AUTOSAR XML (schema 4-0-3)
package /AUTOSAR/Services/Dcm
  swc implementation IMPL_Dcm: programming-language=C, sw-version=6.14.0, swc-bsw-mapping=Dcm_SwcBswMapping, vendor-id=41, behavior=IB_Dcm
    code-descriptors:
      code CODE_Dcm: artifact-descriptors=autosar-engineering-object={short-label=Dcm, category=SWSRC}
    resource consumption RC_Dcm
  unit UnitNone
  178 x client server interface, all with is-service=true:
    DTRServices
      operation GetDTRValue: possible-error=DTRServices/E_NOT_OK
        5 x arg:
          OpStatus: type=Dcm_OpStatusType, direction=IN
          Testval: type=uint16, direction=OUT
          Minlimit: type=uint16, direction=OUT
          Maxlimit: type=uint16, direction=OUT
          Status: type=Dcm_DTRStatusType, direction=OUT
      error E_NOT_OK: error-code=1
    CallbackDCMRequestServices
      operation StartProtocol: possible-error=[CallbackDCMRequestServices/E_NOT_OK, E_PROTOCOL_NOT_ALLOWED, CallbackDCMRequestServices/E_UNCONNECTED]
        arg ProtocolID: type=Dcm_ProtocolType, direction=IN
      operation StopProtocol: possible-error=CallbackDCMRequestServices/E_NOT_OK
        arg ProtocolID: type=Dcm_ProtocolType, direction=IN
      error E_NOT_OK: error-code=1
      error E_PROTOCOL_NOT_ALLOWED: error-code=5
      error E_UNCONNECTED: error-code=134
    ServiceRequestNotification
      operation Indication: possible-error=[ServiceRequestNotification/E_NOT_OK, E_REQUEST_NOT_ACCEPTED, ServiceRequestNotification/E_UNCONNECTED]
        6 x arg:
          SID: type=uint8, direction=IN
          RequestData: type=Dcm_DataBuffer1024FixedType, direction=INOUT
          DataSize: type=uint16, direction=IN
          ReqType: type=uint8, direction=IN
          SourceAddress: type=uint16, direction=IN
          ErrorCode: type=Dcm_NegativeResponseCodeType, direction=OUT
      operation Confirmation: possible-error=ServiceRequestNotification/E_NOT_OK
        4 x arg, all with direction=IN:
          SID: type=uint8
          ReqType: type=uint8
          SourceAddress: type=uint16
          ConfirmationStatus: type=Dcm_ConfirmationStatusType
      error E_NOT_OK: error-code=1
      error E_REQUEST_NOT_ACCEPTED: error-code=8
      error E_UNCONNECTED: error-code=134
    ResetService
      operation EcuReset: possible-error=[ResetService/E_NOT_OK, ResetService/E_PENDING]
        arg resetType: type=uint8, direction=IN
        arg ErrorCode: type=Dcm_NegativeResponseCodeType, direction=OUT
      error E_NOT_OK: error-code=1
      error E_PENDING: error-code=10
    DCMServices
      4 x operation, all with possible-error=DCMServices/E_NOT_OK:
        GetActiveProtocol
          arg ActiveProtocol: type=Dcm_ProtocolType, direction=OUT
        GetSesCtrlType
          arg ActiveSession: type=Dcm_SesCtrlType, direction=OUT
        GetSecurityLevel
          arg SecLevel: type=Dcm_SecLevelType, direction=OUT
        ResetToDefaultSession
      error E_NOT_OK: error-code=1
    DCM_Roe
      operation TriggerOnEvent: possible-error=DCM_Roe/E_NOT_OK
        arg RoeEventId: type=uint8, direction=IN
      error E_NOT_OK: error-code=1
    ROEServices
      operation ActivateEvent: possible-error=ROEServices/E_NOT_OK
        arg RoeEventId: type=uint8, direction=IN
        arg RoeState: type=Dcm_RoeStateType, direction=IN
      error E_NOT_OK: error-code=1
    SecurityAccess_SecurityLevel1
      operation GetSeed: possible-error=[SecurityAccess_SecurityLevel1/E_NOT_OK, SecurityAccess_SecurityLevel1/E_PENDING]
        arg OpStatus: type=Dcm_OpStatusType, direction=IN
        arg Seed: type=Dcm_DataBuffer4FixedType, direction=OUT
        arg ErrorCode: type=Dcm_NegativeResponseCodeType, direction=OUT
      operation CompareKey: possible-error=[SecurityAccess_SecurityLevel1/E_NOT_OK, SecurityAccess_SecurityLevel1/E_PENDING, E_COMPARE_KEY_FAILED]
        arg Key: type=Dcm_DataBuffer4FixedType, direction=INOUT
        arg OpStatus: type=Dcm_OpStatusType, direction=IN
      error E_NOT_OK: error-code=1
      error E_PENDING: error-code=10
      error E_COMPARE_KEY_FAILED: error-code=11
    RoutineServices_RidAE10_MainRelayCtrl
      operation Start: possible-error=[RoutineServices_RidAE10_MainRelayCtrl/E_NOT_OK, RoutineServices_RidAE10_MainRelayCtrl/E_PENDING, RoutineServices_RidAE10_MainRelayCtrl/E_FORCE_RCRRP]
        arg OpStatus: type=Dcm_OpStatusType, direction=IN
        arg ErrorCode: type=Dcm_NegativeResponseCodeType, direction=OUT
      operation Stop: possible-error=[RoutineServices_RidAE10_MainRelayCtrl/E_NOT_OK, RoutineServices_RidAE10_MainRelayCtrl/E_PENDING, RoutineServices_RidAE10_MainRelayCtrl/E_FORCE_RCRRP]
        arg OpStatus: type=Dcm_OpStatusType, direction=IN
        arg ErrorCode: type=Dcm_NegativeResponseCodeType, direction=OUT
      operation RequestResults: possible-error=[RoutineServices_RidAE10_MainRelayCtrl/E_NOT_OK, RoutineServices_RidAE10_MainRelayCtrl/E_PENDING, RoutineServices_RidAE10_MainRelayCtrl/E_FORCE_RCRRP]
        arg OpStatus: type=Dcm_OpStatusType, direction=IN
        arg dataOut1: type=uint8, direction=OUT
        arg ErrorCode: type=Dcm_NegativeResponseCodeType, direction=OUT
      error E_NOT_OK: error-code=1
      error E_PENDING: error-code=10
      error E_FORCE_RCRRP: error-code=12
    RoutineServices_RidAE11_OnbdRelayCtrl
      operation Start: possible-error=[RoutineServices_RidAE11_OnbdRelayCtrl/E_NOT_OK, RoutineServices_RidAE11_OnbdRelayCtrl/E_PENDING, RoutineServices_RidAE11_OnbdRelayCtrl/E_FORCE_RCRRP]
        arg OpStatus: type=Dcm_OpStatusType, direction=IN
        arg ErrorCode: type=Dcm_NegativeResponseCodeType, direction=OUT
      operation Stop: possible-error=[RoutineServices_RidAE11_OnbdRelayCtrl/E_NOT_OK, RoutineServices_RidAE11_OnbdRelayCtrl/E_PENDING, RoutineServices_RidAE11_OnbdRelayCtrl/E_FORCE_RCRRP]
        arg OpStatus: type=Dcm_OpStatusType, direction=IN
        arg ErrorCode: type=Dcm_NegativeResponseCodeType, direction=OUT
      operation RequestResults: possible-error=[RoutineServices_RidAE11_OnbdRelayCtrl/E_NOT_OK, RoutineServices_RidAE11_OnbdRelayCtrl/E_PENDING, RoutineServices_RidAE11_OnbdRelayCtrl/E_FORCE_RCRRP]
        arg OpStatus: type=Dcm_OpStatusType, direction=IN
        arg dataOut1: type=uint8, direction=OUT
        arg ErrorCode: type=Dcm_NegativeResponseCodeType, direction=OUT
      error E_NOT_OK: error-code=1
      error E_PENDING: error-code=10
      error E_FORCE_RCRRP: error-code=12
    RoutineServices_RidAE12_OffbdRelayCtrl
      operation Start: possible-error=[RoutineServices_RidAE12_OffbdRelayCtrl/E_NOT_OK, RoutineServices_RidAE12_OffbdRelayCtrl/E_PENDING, RoutineServices_RidAE12_OffbdRelayCtrl/E_FORCE_RCRRP]
        arg OpStatus: type=Dcm_OpStatusType, direction=IN
        arg ErrorCode: type=Dcm_NegativeResponseCodeType, direction=OUT
      operation Stop: possible-error=[RoutineServices_RidAE12_OffbdRelayCtrl/E_NOT_OK, RoutineServices_RidAE12_OffbdRelayCtrl/E_PENDING, RoutineServices_RidAE12_OffbdRelayCtrl/E_FORCE_RCRRP]
        arg OpStatus: type=Dcm_OpStatusType, direction=IN
        arg ErrorCode: type=Dcm_NegativeResponseCodeType, direction=OUT
      operation RequestResults: possible-error=[RoutineServices_RidAE12_OffbdRelayCtrl/E_NOT_OK, RoutineServices_RidAE12_OffbdRelayCtrl/E_PENDING, RoutineServices_RidAE12_OffbdRelayCtrl/E_FORCE_RCRRP]
        arg OpStatus: type=Dcm_OpStatusType, direction=IN
        arg dataOut1: type=uint8, direction=OUT
        arg ErrorCode: type=Dcm_NegativeResponseCodeType, direction=OUT
      error E_NOT_OK: error-code=1
      error E_PENDING: error-code=10
      error E_FORCE_RCRRP: error-code=12
    RoutineServices_RidAE13_WakeOnbdChrgr
      operation Start: possible-error=[RoutineServices_RidAE13_WakeOnbdChrgr/E_NOT_OK, RoutineServices_RidAE13_WakeOnbdChrgr/E_PENDING, RoutineServices_RidAE13_WakeOnbdChrgr/E_FORCE_RCRRP]
        arg OpStatus: type=Dcm_OpStatusType, direction=IN
        arg ErrorCode: type=Dcm_NegativeResponseCodeType, direction=OUT
      operation RequestResults: possible-error=[RoutineServices_RidAE13_WakeOnbdChrgr/E_NOT_OK, RoutineServices_RidAE13_WakeOnbdChrgr/E_PENDING, RoutineServices_RidAE13_WakeOnbdChrgr/E_FORCE_RCRRP]
        arg OpStatus: type=Dcm_OpStatusType, direction=IN
        arg dataOut1: type=uint8, direction=OUT
        arg ErrorCode: type=Dcm_NegativeResponseCodeType, direction=OUT
      error E_NOT_OK: error-code=1
      error E_PENDING: error-code=10
      error E_FORCE_RCRRP: error-code=12
    RoutineServices_RidAE14_OBCRvseChk
      operation Start: possible-error=[RoutineServices_RidAE14_OBCRvseChk/E_NOT_OK, RoutineServices_RidAE14_OBCRvseChk/E_PENDING, RoutineServices_RidAE14_OBCRvseChk/E_FORCE_RCRRP]
        arg OpStatus: type=Dcm_OpStatusType, direction=IN
        arg ErrorCode: type=Dcm_NegativeResponseCodeType, direction=OUT
      operation RequestResults: possible-error=[RoutineServices_RidAE14_OBCRvseChk/E_NOT_OK, RoutineServices_RidAE14_OBCRvseChk/E_PENDING, RoutineServices_RidAE14_OBCRvseChk/E_FORCE_RCRRP]
        arg OpStatus: type=Dcm_OpStatusType, direction=IN
        arg dataOut1: type=uint8, direction=OUT
        arg ErrorCode: type=Dcm_NegativeResponseCodeType, direction=OUT
      error E_NOT_OK: error-code=1
      error E_PENDING: error-code=10
      error E_FORCE_RCRRP: error-code=12
    DataServices_Did010B_Data_DateTime
      operation ReadData: possible-error=DataServices_Did010B_Data_DateTime/E_NOT_OK
        arg Data: type=Dcm_DataBuffer6FixedType, direction=OUT
      operation ConditionCheckRead: possible-error=[DataServices_Did010B_Data_DateTime/E_NOT_OK, DataServices_Did010B_Data_DateTime/E_PENDING]
        arg OpStatus: type=Dcm_OpStatusType, direction=IN
        arg ErrorCode: type=Dcm_NegativeResponseCodeType, direction=OUT
      error E_NOT_OK: error-code=1
      error E_PENDING: error-code=10
    DataServices_Did010C_Data_CoolantTemp
      operation ReadData: possible-error=DataServices_Did010C_Data_CoolantTemp/E_NOT_OK
        arg Data: type=Dcm_DataBuffer1FixedType, direction=OUT
      operation ConditionCheckRead: possible-error=[DataServices_Did010C_Data_CoolantTemp/E_NOT_OK, DataServices_Did010C_Data_CoolantTemp/E_PENDING]
        arg OpStatus: type=Dcm_OpStatusType, direction=IN
        arg ErrorCode: type=Dcm_NegativeResponseCodeType, direction=OUT
      error E_NOT_OK: error-code=1
      error E_PENDING: error-code=10
    DataServices_Did0112_Data_LVSupplyVoltage
      operation ReadData: possible-error=DataServices_Did0112_Data_LVSupplyVoltage/E_NOT_OK
        arg Data: type=Dcm_DataBuffer1FixedType, direction=OUT
      operation ConditionCheckRead: possible-error=[DataServices_Did0112_Data_LVSupplyVoltage/E_NOT_OK, DataServices_Did0112_Data_LVSupplyVoltage/E_PENDING]
        arg OpStatus: type=Dcm_OpStatusType, direction=IN
        arg ErrorCode: type=Dcm_NegativeResponseCodeType, direction=OUT
      error E_NOT_OK: error-code=1
      error E_PENDING: error-code=10
    DataServices_DidB001_Data_Mod1CellInfo
      operation ReadData: possible-error=DataServices_DidB001_Data_Mod1CellInfo/E_NOT_OK
        arg Data: type=Dcm_DataBuffer7FixedType, direction=OUT
      operation ConditionCheckRead: possible-error=[DataServices_DidB001_Data_Mod1CellInfo/E_NOT_OK, DataServices_DidB001_Data_Mod1CellInfo/E_PENDING]
        arg OpStatus: type=Dcm_OpStatusType, direction=IN
        arg ErrorCode: type=Dcm_NegativeResponseCodeType, direction=OUT
      error E_NOT_OK: error-code=1
      error E_PENDING: error-code=10
    DataServices_DidB002_Data_Mod1CellVmax
      operation ReadData: possible-error=DataServices_DidB002_Data_Mod1CellVmax/E_NOT_OK
        arg Data: type=Dcm_DataBuffer2FixedType, direction=OUT
      operation ConditionCheckRead: possible-error=[DataServices_DidB002_Data_Mod1CellVmax/E_NOT_OK, DataServices_DidB002_Data_Mod1CellVmax/E_PENDING]
        arg OpStatus: type=Dcm_OpStatusType, direction=IN
        arg ErrorCode: type=Dcm_NegativeResponseCodeType, direction=OUT
      error E_NOT_OK: error-code=1
      error E_PENDING: error-code=10
    DataServices_DidB006_Data_Mod1Temp2
      operation ReadData: possible-error=DataServices_DidB006_Data_Mod1Temp2/E_NOT_OK
        arg Data: type=Dcm_DataBuffer1FixedType, direction=OUT
      operation ConditionCheckRead: possible-error=[DataServices_DidB006_Data_Mod1Temp2/E_NOT_OK, DataServices_DidB006_Data_Mod1Temp2/E_PENDING]
        arg OpStatus: type=Dcm_OpStatusType, direction=IN
        arg ErrorCode: type=Dcm_NegativeResponseCodeType, direction=OUT
      error E_NOT_OK: error-code=1
      error E_PENDING: error-code=10
    DataServices_DidB007_Data_Mod1Temp1
      operation ReadData: possible-error=DataServices_DidB007_Data_Mod1Temp1/E_NOT_OK
        arg Data: type=Dcm_DataBuffer1FixedType, direction=OUT
      operation ConditionCheckRead: possible-error=[DataServices_DidB007_Data_Mod1Temp1/E_NOT_OK, DataServices_DidB007_Data_Mod1Temp1/E_PENDING]
        arg OpStatus: type=Dcm_OpStatusType, direction=IN
        arg ErrorCode: type=Dcm_NegativeResponseCodeType, direction=OUT
      error E_NOT_OK: error-code=1
      error E_PENDING: error-code=10
    DataServices_DidB008_Data_Mod1PCBTemp
      operation ReadData: possible-error=DataServices_DidB008_Data_Mod1PCBTemp/E_NOT_OK
        arg Data: type=Dcm_DataBuffer1FixedType, direction=OUT
      operation ConditionCheckRead: possible-error=[DataServices_DidB008_Data_Mod1PCBTemp/E_NOT_OK, DataServices_DidB008_Data_Mod1PCBTemp/E_PENDING]
        arg OpStatus: type=Dcm_OpStatusType, direction=IN
        arg ErrorCode: type=Dcm_NegativeResponseCodeType, direction=OUT
      error E_NOT_OK: error-code=1
      error E_PENDING: error-code=10
    DataServices_DidB009_Data_Mod2CellInfo
      operation ReadData: possible-error=DataServices_DidB009_Data_Mod2CellInfo/E_NOT_OK
        arg Data: type=Dcm_DataBuffer7FixedType, direction=OUT
      operation ConditionCheckRead: possible-error=[DataServices_DidB009_Data_Mod2CellInfo/E_NOT_OK, DataServices_DidB009_Data_Mod2CellInfo/E_PENDING]
        arg OpStatus: type=Dcm_OpStatusType, direction=IN
        arg ErrorCode: type=Dcm_NegativeResponseCodeType, direction=OUT
      error E_NOT_OK: error-code=1
      error E_PENDING: error-code=10
    DataServices_DidB00A_Data_Mod2CellVmax
      operation ReadData: possible-error=DataServices_DidB00A_Data_Mod2CellVmax/E_NOT_OK
        arg Data: type=Dcm_DataBuffer2FixedType, direction=OUT
      operation ConditionCheckRead: possible-error=[DataServices_DidB00A_Data_Mod2CellVmax/E_NOT_OK, DataServices_DidB00A_Data_Mod2CellVmax/E_PENDING]
        arg OpStatus: type=Dcm_OpStatusType, direction=IN
        arg ErrorCode: type=Dcm_NegativeResponseCodeType, direction=OUT
      error E_NOT_OK: error-code=1
      error E_PENDING: error-code=10
    DataServices_DidB00E_Data_Mod2Temp2
      operation ReadData: possible-error=DataServices_DidB00E_Data_Mod2Temp2/E_NOT_OK
        arg Data: type=Dcm_DataBuffer1FixedType, direction=OUT
      operation ConditionCheckRead: possible-error=[DataServices_DidB00E_Data_Mod2Temp2/E_NOT_OK, DataServices_DidB00E_Data_Mod2Temp2/E_PENDING]
        arg OpStatus: type=Dcm_OpStatusType, direction=IN
        arg ErrorCode: type=Dcm_NegativeResponseCodeType, direction=OUT
      error E_NOT_OK: error-code=1
      error E_PENDING: error-code=10
    DataServices_DidB00F_Data_Mod2Temp1
      operation ReadData: possible-error=DataServices_DidB00F_Data_Mod2Temp1/E_NOT_OK
        arg Data: type=Dcm_DataBuffer1FixedType, direction=OUT
      operation ConditionCheckRead: possible-error=[DataServices_DidB00F_Data_Mod2Temp1/E_NOT_OK, DataServices_DidB00F_Data_Mod2Temp1/E_PENDING]
        arg OpStatus: type=Dcm_OpStatusType, direction=IN
        arg ErrorCode: type=Dcm_NegativeResponseCodeType, direction=OUT
      error E_NOT_OK: error-code=1
      error E_PENDING: error-code=10
    DataServices_DidB010_Data_Mod2PCBTemp
      operation ReadData: possible-error=DataServices_DidB010_Data_Mod2PCBTemp/E_NOT_OK
        arg Data: type=Dcm_DataBuffer1FixedType, direction=OUT
      operation ConditionCheckRead: possible-error=[DataServices_DidB010_Data_Mod2PCBTemp/E_NOT_OK, DataServices_DidB010_Data_Mod2PCBTemp/E_PENDING]
        arg OpStatus: type=Dcm_OpStatusType, direction=IN
        arg ErrorCode: type=Dcm_NegativeResponseCodeType, direction=OUT
      error E_NOT_OK: error-code=1
      error E_PENDING: error-code=10
    DataServices_DidB011_Data_Mod3CellInfo
      operation ReadData: possible-error=DataServices_DidB011_Data_Mod3CellInfo/E_NOT_OK
        arg Data: type=Dcm_DataBuffer7FixedType, direction=OUT
      operation ConditionCheckRead: possible-error=[DataServices_DidB011_Data_Mod3CellInfo/E_NOT_OK, DataServices_DidB011_Data_Mod3CellInfo/E_PENDING]
        arg OpStatus: type=Dcm_OpStatusType, direction=IN
        arg ErrorCode: type=Dcm_NegativeResponseCodeType, direction=OUT
      error E_NOT_OK: error-code=1
      error E_PENDING: error-code=10
    DataServices_DidB012_Data_Mod3CellVmax
      operation ReadData: possible-error=DataServices_DidB012_Data_Mod3CellVmax/E_NOT_OK
        arg Data: type=Dcm_DataBuffer2FixedType, direction=OUT
      operation ConditionCheckRead: possible-error=[DataServices_DidB012_Data_Mod3CellVmax/E_NOT_OK, DataServices_DidB012_Data_Mod3CellVmax/E_PENDING]
        arg OpStatus: type=Dcm_OpStatusType, direction=IN
        arg ErrorCode: type=Dcm_NegativeResponseCodeType, direction=OUT
      error E_NOT_OK: error-code=1
      error E_PENDING: error-code=10
    DataServices_DidB016_Data_Mod3Temp2
      operation ReadData: possible-error=DataServices_DidB016_Data_Mod3Temp2/E_NOT_OK
        arg Data: type=Dcm_DataBuffer1FixedType, direction=OUT
      operation ConditionCheckRead: possible-error=[DataServices_DidB016_Data_Mod3Temp2/E_NOT_OK, DataServices_DidB016_Data_Mod3Temp2/E_PENDING]
        arg OpStatus: type=Dcm_OpStatusType, direction=IN
        arg ErrorCode: type=Dcm_NegativeResponseCodeType, direction=OUT
      error E_NOT_OK: error-code=1
      error E_PENDING: error-code=10
    DataServices_DidB017_Data_Mod3Temp1
      operation ReadData: possible-error=DataServices_DidB017_Data_Mod3Temp1/E_NOT_OK
        arg Data: type=Dcm_DataBuffer1FixedType, direction=OUT
      operation ConditionCheckRead: possible-error=[DataServices_DidB017_Data_Mod3Temp1/E_NOT_OK, DataServices_DidB017_Data_Mod3Temp1/E_PENDING]
        arg OpStatus: type=Dcm_OpStatusType, direction=IN
        arg ErrorCode: type=Dcm_NegativeResponseCodeType, direction=OUT
      error E_NOT_OK: error-code=1
      error E_PENDING: error-code=10
    DataServices_DidB018_Data_Mod3PCBTemp
      operation ReadData: possible-error=DataServices_DidB018_Data_Mod3PCBTemp/E_NOT_OK
        arg Data: type=Dcm_DataBuffer1FixedType, direction=OUT
      operation ConditionCheckRead: possible-error=[DataServices_DidB018_Data_Mod3PCBTemp/E_NOT_OK, DataServices_DidB018_Data_Mod3PCBTemp/E_PENDING]
        arg OpStatus: type=Dcm_OpStatusType, direction=IN
        arg ErrorCode: type=Dcm_NegativeResponseCodeType, direction=OUT
      error E_NOT_OK: error-code=1
      error E_PENDING: error-code=10
    DataServices_DidB019_Data_Mod4CellInfo
      operation ReadData: possible-error=DataServices_DidB019_Data_Mod4CellInfo/E_NOT_OK
        arg Data: type=Dcm_DataBuffer7FixedType, direction=OUT
      operation ConditionCheckRead: possible-error=[DataServices_DidB019_Data_Mod4CellInfo/E_NOT_OK, DataServices_DidB019_Data_Mod4CellInfo/E_PENDING]
        arg OpStatus: type=Dcm_OpStatusType, direction=IN
        arg ErrorCode: type=Dcm_NegativeResponseCodeType, direction=OUT
      error E_NOT_OK: error-code=1
      error E_PENDING: error-code=10
    DataServices_DidB01A_Data_Mod4CellVmax
      operation ReadData: possible-error=DataServices_DidB01A_Data_Mod4CellVmax/E_NOT_OK
        arg Data: type=Dcm_DataBuffer2FixedType, direction=OUT
      operation ConditionCheckRead: possible-error=[DataServices_DidB01A_Data_Mod4CellVmax/E_NOT_OK, DataServices_DidB01A_Data_Mod4CellVmax/E_PENDING]
        arg OpStatus: type=Dcm_OpStatusType, direction=IN
        arg ErrorCode: type=Dcm_NegativeResponseCodeType, direction=OUT
      error E_NOT_OK: error-code=1
      error E_PENDING: error-code=10
    DataServices_DidB01E_Data_Mod4Temp2
      operation ReadData: possible-error=DataServices_DidB01E_Data_Mod4Temp2/E_NOT_OK
        arg Data: type=Dcm_DataBuffer1FixedType, direction=OUT
      operation ConditionCheckRead: possible-error=[DataServices_DidB01E_Data_Mod4Temp2/E_NOT_OK, DataServices_DidB01E_Data_Mod4Temp2/E_PENDING]
        arg OpStatus: type=Dcm_OpStatusType, direction=IN
        arg ErrorCode: type=Dcm_NegativeResponseCodeType, direction=OUT
      error E_NOT_OK: error-code=1
      error E_PENDING: error-code=10
    DataServices_DidB01F_Data_Mod4Temp1
      operation ReadData: possible-error=DataServices_DidB01F_Data_Mod4Temp1/E_NOT_OK
        arg Data: type=Dcm_DataBuffer1FixedType, direction=OUT
      operation ConditionCheckRead: possible-error=[DataServices_DidB01F_Data_Mod4Temp1/E_NOT_OK, DataServices_DidB01F_Data_Mod4Temp1/E_PENDING]
        arg OpStatus: type=Dcm_OpStatusType, direction=IN
        arg ErrorCode: type=Dcm_NegativeResponseCodeType, direction=OUT
      error E_NOT_OK: error-code=1
      error E_PENDING: error-code=10
    DataServices_DidB020_Data_Mod4PCBTemp
      operation ReadData: possible-error=DataServices_DidB020_Data_Mod4PCBTemp/E_NOT_OK
        arg Data: type=Dcm_DataBuffer1FixedType, direction=OUT
      operation ConditionCheckRead: possible-error=[DataServices_DidB020_Data_Mod4PCBTemp/E_NOT_OK, DataServices_DidB020_Data_Mod4PCBTemp/E_PENDING]
        arg OpStatus: type=Dcm_OpStatusType, direction=IN
        arg ErrorCode: type=Dcm_NegativeResponseCodeType, direction=OUT
      error E_NOT_OK: error-code=1
      error E_PENDING: error-code=10
    DataServices_DidB021_Data_Mod5CellInfo
      operation ReadData: possible-error=DataServices_DidB021_Data_Mod5CellInfo/E_NOT_OK
        arg Data: type=Dcm_DataBuffer7FixedType, direction=OUT
      operation ConditionCheckRead: possible-error=[DataServices_DidB021_Data_Mod5CellInfo/E_NOT_OK, DataServices_DidB021_Data_Mod5CellInfo/E_PENDING]
        arg OpStatus: type=Dcm_OpStatusType, direction=IN
        arg ErrorCode: type=Dcm_NegativeResponseCodeType, direction=OUT
      error E_NOT_OK: error-code=1
      error E_PENDING: error-code=10
    DataServices_DidB022_Data_Mod5CellVmax
      operation ReadData: possible-error=DataServices_DidB022_Data_Mod5CellVmax/E_NOT_OK
        arg Data: type=Dcm_DataBuffer2FixedType, direction=OUT
      operation ConditionCheckRead: possible-error=[DataServices_DidB022_Data_Mod5CellVmax/E_NOT_OK, DataServices_DidB022_Data_Mod5CellVmax/E_PENDING]
        arg OpStatus: type=Dcm_OpStatusType, direction=IN
        arg ErrorCode: type=Dcm_NegativeResponseCodeType, direction=OUT
      error E_NOT_OK: error-code=1
      error E_PENDING: error-code=10
    DataServices_DidB026_Data_Mod5Temp2
      operation ReadData: possible-error=DataServices_DidB026_Data_Mod5Temp2/E_NOT_OK
        arg Data: type=Dcm_DataBuffer1FixedType, direction=OUT
      operation ConditionCheckRead: possible-error=[DataServices_DidB026_Data_Mod5Temp2/E_NOT_OK, DataServices_DidB026_Data_Mod5Temp2/E_PENDING]
        arg OpStatus: type=Dcm_OpStatusType, direction=IN
        arg ErrorCode: type=Dcm_NegativeResponseCodeType, direction=OUT
      error E_NOT_OK: error-code=1
      error E_PENDING: error-code=10
    DataServices_DidB027_Data_Mod5Temp1
      operation ReadData: possible-error=DataServices_DidB027_Data_Mod5Temp1/E_NOT_OK
        arg Data: type=Dcm_DataBuffer1FixedType, direction=OUT
      operation ConditionCheckRead: possible-error=[DataServices_DidB027_Data_Mod5Temp1/E_NOT_OK, DataServices_DidB027_Data_Mod5Temp1/E_PENDING]
        arg OpStatus: type=Dcm_OpStatusType, direction=IN
        arg ErrorCode: type=Dcm_NegativeResponseCodeType, direction=OUT
      error E_NOT_OK: error-code=1
      error E_PENDING: error-code=10
    DataServices_DidB028_Data_Mod5PCBTemp
      operation ReadData: possible-error=DataServices_DidB028_Data_Mod5PCBTemp/E_NOT_OK
        arg Data: type=Dcm_DataBuffer1FixedType, direction=OUT
      operation ConditionCheckRead: possible-error=[DataServices_DidB028_Data_Mod5PCBTemp/E_NOT_OK, DataServices_DidB028_Data_Mod5PCBTemp/E_PENDING]
        arg OpStatus: type=Dcm_OpStatusType, direction=IN
        arg ErrorCode: type=Dcm_NegativeResponseCodeType, direction=OUT
      error E_NOT_OK: error-code=1
      error E_PENDING: error-code=10
    DataServices_DidB029_Data_Mod6CellInfo
      operation ReadData: possible-error=DataServices_DidB029_Data_Mod6CellInfo/E_NOT_OK
        arg Data: type=Dcm_DataBuffer7FixedType, direction=OUT
      operation ConditionCheckRead: possible-error=[DataServices_DidB029_Data_Mod6CellInfo/E_NOT_OK, DataServices_DidB029_Data_Mod6CellInfo/E_PENDING]
        arg OpStatus: type=Dcm_OpStatusType, direction=IN
        arg ErrorCode: type=Dcm_NegativeResponseCodeType, direction=OUT
      error E_NOT_OK: error-code=1
      error E_PENDING: error-code=10
    DataServices_DidB02A_Data_Mod6CellVmax
      operation ReadData: possible-error=DataServices_DidB02A_Data_Mod6CellVmax/E_NOT_OK
        arg Data: type=Dcm_DataBuffer2FixedType, direction=OUT
      operation ConditionCheckRead: possible-error=[DataServices_DidB02A_Data_Mod6CellVmax/E_NOT_OK, DataServices_DidB02A_Data_Mod6CellVmax/E_PENDING]
        arg OpStatus: type=Dcm_OpStatusType, direction=IN
        arg ErrorCode: type=Dcm_NegativeResponseCodeType, direction=OUT
      error E_NOT_OK: error-code=1
      error E_PENDING: error-code=10
    DataServices_DidB02E_Data_Mod6Temp2
      operation ReadData: possible-error=DataServices_DidB02E_Data_Mod6Temp2/E_NOT_OK
        arg Data: type=Dcm_DataBuffer1FixedType, direction=OUT
      operation ConditionCheckRead: possible-error=[DataServices_DidB02E_Data_Mod6Temp2/E_NOT_OK, DataServices_DidB02E_Data_Mod6Temp2/E_PENDING]
        arg OpStatus: type=Dcm_OpStatusType, direction=IN
        arg ErrorCode: type=Dcm_NegativeResponseCodeType, direction=OUT
      error E_NOT_OK: error-code=1
      error E_PENDING: error-code=10
    DataServices_DidB02F_Data_Mod6Temp1
      operation ReadData: possible-error=DataServices_DidB02F_Data_Mod6Temp1/E_NOT_OK
        arg Data: type=Dcm_DataBuffer1FixedType, direction=OUT
      operation ConditionCheckRead: possible-error=[DataServices_DidB02F_Data_Mod6Temp1/E_NOT_OK, DataServices_DidB02F_Data_Mod6Temp1/E_PENDING]
        arg OpStatus: type=Dcm_OpStatusType, direction=IN
        arg ErrorCode: type=Dcm_NegativeResponseCodeType, direction=OUT
      error E_NOT_OK: error-code=1
      error E_PENDING: error-code=10
    DataServices_DidB030_Data_Mod6PCBTemp
      operation ReadData: possible-error=DataServices_DidB030_Data_Mod6PCBTemp/E_NOT_OK
        arg Data: type=Dcm_DataBuffer1FixedType, direction=OUT
      operation ConditionCheckRead: possible-error=[DataServices_DidB030_Data_Mod6PCBTemp/E_NOT_OK, DataServices_DidB030_Data_Mod6PCBTemp/E_PENDING]
        arg OpStatus: type=Dcm_OpStatusType, direction=IN
        arg ErrorCode: type=Dcm_NegativeResponseCodeType, direction=OUT
      error E_NOT_OK: error-code=1
      error E_PENDING: error-code=10
    DataServices_DidB031_Data_Mod7CellVmin
      operation ReadData: possible-error=DataServices_DidB031_Data_Mod7CellVmin/E_NOT_OK
        arg Data: type=Dcm_DataBuffer2FixedType, direction=OUT
      operation ConditionCheckRead: possible-error=[DataServices_DidB031_Data_Mod7CellVmin/E_NOT_OK, DataServices_DidB031_Data_Mod7CellVmin/E_PENDING]
        arg OpStatus: type=Dcm_OpStatusType, direction=IN
        arg ErrorCode: type=Dcm_NegativeResponseCodeType, direction=OUT
      error E_NOT_OK: error-code=1
      error E_PENDING: error-code=10
    DataServices_DidB032_Data_Mod7CellVmax
      operation ReadData: possible-error=DataServices_DidB032_Data_Mod7CellVmax/E_NOT_OK
        arg Data: type=Dcm_DataBuffer2FixedType, direction=OUT
      operation ConditionCheckRead: possible-error=[DataServices_DidB032_Data_Mod7CellVmax/E_NOT_OK, DataServices_DidB032_Data_Mod7CellVmax/E_PENDING]
        arg OpStatus: type=Dcm_OpStatusType, direction=IN
        arg ErrorCode: type=Dcm_NegativeResponseCodeType, direction=OUT
      error E_NOT_OK: error-code=1
      error E_PENDING: error-code=10
    DataServices_DidB036_Data_Mod7Temp2
      operation ReadData: possible-error=DataServices_DidB036_Data_Mod7Temp2/E_NOT_OK
        arg Data: type=Dcm_DataBuffer1FixedType, direction=OUT
      operation ConditionCheckRead: possible-error=[DataServices_DidB036_Data_Mod7Temp2/E_NOT_OK, DataServices_DidB036_Data_Mod7Temp2/E_PENDING]
        arg OpStatus: type=Dcm_OpStatusType, direction=IN
        arg ErrorCode: type=Dcm_NegativeResponseCodeType, direction=OUT
      error E_NOT_OK: error-code=1
      error E_PENDING: error-code=10
    DataServices_DidB037_Data_Mod7Temp1
      operation ReadData: possible-error=DataServices_DidB037_Data_Mod7Temp1/E_NOT_OK
        arg Data: type=Dcm_DataBuffer1FixedType, direction=OUT
      operation ConditionCheckRead: possible-error=[DataServices_DidB037_Data_Mod7Temp1/E_NOT_OK, DataServices_DidB037_Data_Mod7Temp1/E_PENDING]
        arg OpStatus: type=Dcm_OpStatusType, direction=IN
        arg ErrorCode: type=Dcm_NegativeResponseCodeType, direction=OUT
      error E_NOT_OK: error-code=1
      error E_PENDING: error-code=10
    DataServices_DidB038_Data_Mod7PCBTemp
      operation ReadData: possible-error=DataServices_DidB038_Data_Mod7PCBTemp/E_NOT_OK
        arg Data: type=Dcm_DataBuffer1FixedType, direction=OUT
      operation ConditionCheckRead: possible-error=[DataServices_DidB038_Data_Mod7PCBTemp/E_NOT_OK, DataServices_DidB038_Data_Mod7PCBTemp/E_PENDING]
        arg OpStatus: type=Dcm_OpStatusType, direction=IN
        arg ErrorCode: type=Dcm_NegativeResponseCodeType, direction=OUT
      error E_NOT_OK: error-code=1
      error E_PENDING: error-code=10
    DataServices_DidB039_Data_Mod8CellVmin
      operation ReadData: possible-error=DataServices_DidB039_Data_Mod8CellVmin/E_NOT_OK
        arg Data: type=Dcm_DataBuffer2FixedType, direction=OUT
      operation ConditionCheckRead: possible-error=[DataServices_DidB039_Data_Mod8CellVmin/E_NOT_OK, DataServices_DidB039_Data_Mod8CellVmin/E_PENDING]
        arg OpStatus: type=Dcm_OpStatusType, direction=IN
        arg ErrorCode: type=Dcm_NegativeResponseCodeType, direction=OUT
      error E_NOT_OK: error-code=1
      error E_PENDING: error-code=10
    DataServices_DidB03A_Data_Mod8CellVmax
      operation ReadData: possible-error=DataServices_DidB03A_Data_Mod8CellVmax/E_NOT_OK
        arg Data: type=Dcm_DataBuffer2FixedType, direction=OUT
      operation ConditionCheckRead: possible-error=[DataServices_DidB03A_Data_Mod8CellVmax/E_NOT_OK, DataServices_DidB03A_Data_Mod8CellVmax/E_PENDING]
        arg OpStatus: type=Dcm_OpStatusType, direction=IN
        arg ErrorCode: type=Dcm_NegativeResponseCodeType, direction=OUT
      error E_NOT_OK: error-code=1
      error E_PENDING: error-code=10
    DataServices_DidB03E_Data_Mod8Temp2
      operation ReadData: possible-error=DataServices_DidB03E_Data_Mod8Temp2/E_NOT_OK
        arg Data: type=Dcm_DataBuffer1FixedType, direction=OUT
      operation ConditionCheckRead: possible-error=[DataServices_DidB03E_Data_Mod8Temp2/E_NOT_OK, DataServices_DidB03E_Data_Mod8Temp2/E_PENDING]
        arg OpStatus: type=Dcm_OpStatusType, direction=IN
        arg ErrorCode: type=Dcm_NegativeResponseCodeType, direction=OUT
      error E_NOT_OK: error-code=1
      error E_PENDING: error-code=10
    DataServices_DidB03F_Data_Mod8Temp1
      operation ReadData: possible-error=DataServices_DidB03F_Data_Mod8Temp1/E_NOT_OK
        arg Data: type=Dcm_DataBuffer1FixedType, direction=OUT
      operation ConditionCheckRead: possible-error=[DataServices_DidB03F_Data_Mod8Temp1/E_NOT_OK, DataServices_DidB03F_Data_Mod8Temp1/E_PENDING]
        arg OpStatus: type=Dcm_OpStatusType, direction=IN
        arg ErrorCode: type=Dcm_NegativeResponseCodeType, direction=OUT
      error E_NOT_OK: error-code=1
      error E_PENDING: error-code=10
    DataServices_DidB040_Data_Mod8PCBTemp
      operation ReadData: possible-error=DataServices_DidB040_Data_Mod8PCBTemp/E_NOT_OK
        arg Data: type=Dcm_DataBuffer1FixedType, direction=OUT
      operation ConditionCheckRead: possible-error=[DataServices_DidB040_Data_Mod8PCBTemp/E_NOT_OK, DataServices_DidB040_Data_Mod8PCBTemp/E_PENDING]
        arg OpStatus: type=Dcm_OpStatusType, direction=IN
        arg ErrorCode: type=Dcm_NegativeResponseCodeType, direction=OUT
      error E_NOT_OK: error-code=1
      error E_PENDING: error-code=10
    DataServices_DidB041_Data_BMSBusV
      operation ReadData: possible-error=DataServices_DidB041_Data_BMSBusV/E_NOT_OK
        arg Data: type=Dcm_DataBuffer2FixedType, direction=OUT
      operation ConditionCheckRead: possible-error=[DataServices_DidB041_Data_BMSBusV/E_NOT_OK, DataServices_DidB041_Data_BMSBusV/E_PENDING]
        arg OpStatus: type=Dcm_OpStatusType, direction=IN
        arg ErrorCode: type=Dcm_NegativeResponseCodeType, direction=OUT
      error E_NOT_OK: error-code=1
      error E_PENDING: error-code=10
    DataServices_DidB042_Data_BMSBatV
      operation ReadData: possible-error=DataServices_DidB042_Data_BMSBatV/E_NOT_OK
        arg Data: type=Dcm_DataBuffer2FixedType, direction=OUT
      operation ConditionCheckRead: possible-error=[DataServices_DidB042_Data_BMSBatV/E_NOT_OK, DataServices_DidB042_Data_BMSBatV/E_PENDING]
        arg OpStatus: type=Dcm_OpStatusType, direction=IN
        arg ErrorCode: type=Dcm_NegativeResponseCodeType, direction=OUT
      error E_NOT_OK: error-code=1
      error E_PENDING: error-code=10
    DataServices_DidB043_Data_BMSCur1
      operation ReadData: possible-error=DataServices_DidB043_Data_BMSCur1/E_NOT_OK
        arg Data: type=Dcm_DataBuffer2FixedType, direction=OUT
      operation ConditionCheckRead: possible-error=[DataServices_DidB043_Data_BMSCur1/E_NOT_OK, DataServices_DidB043_Data_BMSCur1/E_PENDING]
        arg OpStatus: type=Dcm_OpStatusType, direction=IN
        arg ErrorCode: type=Dcm_NegativeResponseCodeType, direction=OUT
      error E_NOT_OK: error-code=1
      error E_PENDING: error-code=10
    DataServices_DidB044_Data_BMSCur2
      operation ReadData: possible-error=DataServices_DidB044_Data_BMSCur2/E_NOT_OK
        arg Data: type=Dcm_DataBuffer2FixedType, direction=OUT
      operation ConditionCheckRead: possible-error=[DataServices_DidB044_Data_BMSCur2/E_NOT_OK, DataServices_DidB044_Data_BMSCur2/E_PENDING]
        arg OpStatus: type=Dcm_OpStatusType, direction=IN
        arg ErrorCode: type=Dcm_NegativeResponseCodeType, direction=OUT
      error E_NOT_OK: error-code=1
      error E_PENDING: error-code=10
    DataServices_DidB045_Data_BMSIso
      operation ReadData: possible-error=DataServices_DidB045_Data_BMSIso/E_NOT_OK
        arg Data: type=Dcm_DataBuffer2FixedType, direction=OUT
      operation ConditionCheckRead: possible-error=[DataServices_DidB045_Data_BMSIso/E_NOT_OK, DataServices_DidB045_Data_BMSIso/E_PENDING]
        arg OpStatus: type=Dcm_OpStatusType, direction=IN
        arg ErrorCode: type=Dcm_NegativeResponseCodeType, direction=OUT
      error E_NOT_OK: error-code=1
      error E_PENDING: error-code=10
    DataServices_DidB046_Data_BMSPackSOC
      operation ReadData: possible-error=[DataServices_DidB046_Data_BMSPackSOC/E_NOT_OK, DataServices_DidB046_Data_BMSPackSOC/E_PENDING]
        arg OpStatus: type=Dcm_OpStatusType, direction=IN
        arg Data: type=Dcm_DataBuffer2FixedType, direction=OUT
      operation ConditionCheckRead: possible-error=[DataServices_DidB046_Data_BMSPackSOC/E_NOT_OK, DataServices_DidB046_Data_BMSPackSOC/E_PENDING]
        arg OpStatus: type=Dcm_OpStatusType, direction=IN
        arg ErrorCode: type=Dcm_NegativeResponseCodeType, direction=OUT
      operation WriteData: possible-error=[DataServices_DidB046_Data_BMSPackSOC/E_NOT_OK, DataServices_DidB046_Data_BMSPackSOC/E_PENDING]
        arg Data: type=Dcm_DataBuffer2FixedType, direction=INOUT
        arg OpStatus: type=Dcm_OpStatusType, direction=IN
        arg ErrorCode: type=Dcm_NegativeResponseCodeType, direction=OUT
      error E_NOT_OK: error-code=1
      error E_PENDING: error-code=10
    DataServices_DidB047_Data_BMSFltLvl
      operation ReadData: possible-error=DataServices_DidB047_Data_BMSFltLvl/E_NOT_OK
        arg Data: type=Dcm_DataBuffer1FixedType, direction=OUT
      operation ConditionCheckRead: possible-error=[DataServices_DidB047_Data_BMSFltLvl/E_NOT_OK, DataServices_DidB047_Data_BMSFltLvl/E_PENDING]
        arg OpStatus: type=Dcm_OpStatusType, direction=IN
        arg ErrorCode: type=Dcm_NegativeResponseCodeType, direction=OUT
      error E_NOT_OK: error-code=1
      error E_PENDING: error-code=10
    DataServices_DidB048_Data_BMSBscSts
      operation ReadData: possible-error=DataServices_DidB048_Data_BMSBscSts/E_NOT_OK
        arg Data: type=Dcm_DataBuffer1FixedType, direction=OUT
      operation ConditionCheckRead: possible-error=[DataServices_DidB048_Data_BMSBscSts/E_NOT_OK, DataServices_DidB048_Data_BMSBscSts/E_PENDING]
        arg OpStatus: type=Dcm_OpStatusType, direction=IN
        arg ErrorCode: type=Dcm_NegativeResponseCodeType, direction=OUT
      error E_NOT_OK: error-code=1
      error E_PENDING: error-code=10
    DataServices_DidB049_Data_BMSVehHVIL
      operation ReadData: possible-error=DataServices_DidB049_Data_BMSVehHVIL/E_NOT_OK
        arg Data: type=Dcm_DataBuffer1FixedType, direction=OUT
      operation ConditionCheckRead: possible-error=[DataServices_DidB049_Data_BMSVehHVIL/E_NOT_OK, DataServices_DidB049_Data_BMSVehHVIL/E_PENDING]
        arg OpStatus: type=Dcm_OpStatusType, direction=IN
        arg ErrorCode: type=Dcm_NegativeResponseCodeType, direction=OUT
      error E_NOT_OK: error-code=1
      error E_PENDING: error-code=10
    DataServices_DidB04A_Data_BMSChgHVIL
      operation ReadData: possible-error=DataServices_DidB04A_Data_BMSChgHVIL/E_NOT_OK
        arg Data: type=Dcm_DataBuffer1FixedType, direction=OUT
      operation ConditionCheckRead: possible-error=[DataServices_DidB04A_Data_BMSChgHVIL/E_NOT_OK, DataServices_DidB04A_Data_BMSChgHVIL/E_PENDING]
        arg OpStatus: type=Dcm_OpStatusType, direction=IN
        arg ErrorCode: type=Dcm_NegativeResponseCodeType, direction=OUT
      error E_NOT_OK: error-code=1
      error E_PENDING: error-code=10
    DataServices_DidB04B_Data_BMSVehWake
      operation ReadData: possible-error=DataServices_DidB04B_Data_BMSVehWake/E_NOT_OK
        arg Data: type=Dcm_DataBuffer1FixedType, direction=OUT
      operation ConditionCheckRead: possible-error=[DataServices_DidB04B_Data_BMSVehWake/E_NOT_OK, DataServices_DidB04B_Data_BMSVehWake/E_PENDING]
        arg OpStatus: type=Dcm_OpStatusType, direction=IN
        arg ErrorCode: type=Dcm_NegativeResponseCodeType, direction=OUT
      error E_NOT_OK: error-code=1
      error E_PENDING: error-code=10
    DataServices_DidB04C_Data_BMSBMSOnbdWake
      operation ReadData: possible-error=DataServices_DidB04C_Data_BMSBMSOnbdWake/E_NOT_OK
        arg Data: type=Dcm_DataBuffer1FixedType, direction=OUT
      operation ConditionCheckRead: possible-error=[DataServices_DidB04C_Data_BMSBMSOnbdWake/E_NOT_OK, DataServices_DidB04C_Data_BMSBMSOnbdWake/E_PENDING]
        arg OpStatus: type=Dcm_OpStatusType, direction=IN
        arg ErrorCode: type=Dcm_NegativeResponseCodeType, direction=OUT
      error E_NOT_OK: error-code=1
      error E_PENDING: error-code=10
    DataServices_DidB04D_Data_BMSOffbdWake
      operation ReadData: possible-error=DataServices_DidB04D_Data_BMSOffbdWake/E_NOT_OK
        arg Data: type=Dcm_DataBuffer1FixedType, direction=OUT
      operation ConditionCheckRead: possible-error=[DataServices_DidB04D_Data_BMSOffbdWake/E_NOT_OK, DataServices_DidB04D_Data_BMSOffbdWake/E_PENDING]
        arg OpStatus: type=Dcm_OpStatusType, direction=IN
        arg ErrorCode: type=Dcm_NegativeResponseCodeType, direction=OUT
      error E_NOT_OK: error-code=1
      error E_PENDING: error-code=10
    DataServices_DidB04E_Data_BMSLvBat
      operation ReadData: possible-error=DataServices_DidB04E_Data_BMSLvBat/E_NOT_OK
        arg Data: type=Dcm_DataBuffer1FixedType, direction=OUT
      operation ConditionCheckRead: possible-error=[DataServices_DidB04E_Data_BMSLvBat/E_NOT_OK, DataServices_DidB04E_Data_BMSLvBat/E_PENDING]
        arg OpStatus: type=Dcm_OpStatusType, direction=IN
        arg ErrorCode: type=Dcm_NegativeResponseCodeType, direction=OUT
      error E_NOT_OK: error-code=1
      error E_PENDING: error-code=10
    DataServices_DidB04F_Data_BMSModuleEn
      operation ReadData: possible-error=DataServices_DidB04F_Data_BMSModuleEn/E_NOT_OK
        arg Data: type=Dcm_DataBuffer1FixedType, direction=OUT
      operation ConditionCheckRead: possible-error=[DataServices_DidB04F_Data_BMSModuleEn/E_NOT_OK, DataServices_DidB04F_Data_BMSModuleEn/E_PENDING]
        arg OpStatus: type=Dcm_OpStatusType, direction=IN
        arg ErrorCode: type=Dcm_NegativeResponseCodeType, direction=OUT
      error E_NOT_OK: error-code=1
      error E_PENDING: error-code=10
    DataServices_DidB050_Data_OffbdChgPlugOn
      operation ReadData: possible-error=DataServices_DidB050_Data_OffbdChgPlugOn/E_NOT_OK
        arg Data: type=Dcm_DataBuffer1FixedType, direction=OUT
      operation ConditionCheckRead: possible-error=[DataServices_DidB050_Data_OffbdChgPlugOn/E_NOT_OK, DataServices_DidB050_Data_OffbdChgPlugOn/E_PENDING]
        arg OpStatus: type=Dcm_OpStatusType, direction=IN
        arg ErrorCode: type=Dcm_NegativeResponseCodeType, direction=OUT
      error E_NOT_OK: error-code=1
      error E_PENDING: error-code=10
    DataServices_DidB051_Data_OnbdChgPlugOn
      operation ReadData: possible-error=DataServices_DidB051_Data_OnbdChgPlugOn/E_NOT_OK
        arg Data: type=Dcm_DataBuffer1FixedType, direction=OUT
      operation ConditionCheckRead: possible-error=[DataServices_DidB051_Data_OnbdChgPlugOn/E_NOT_OK, DataServices_DidB051_Data_OnbdChgPlugOn/E_PENDING]
        arg OpStatus: type=Dcm_OpStatusType, direction=IN
        arg ErrorCode: type=Dcm_NegativeResponseCodeType, direction=OUT
      error E_NOT_OK: error-code=1
      error E_PENDING: error-code=10
    DataServices_DidB052_Data_CrashSts
      operation ReadData: possible-error=DataServices_DidB052_Data_CrashSts/E_NOT_OK
        arg Data: type=Dcm_DataBuffer1FixedType, direction=OUT
      operation ConditionCheckRead: possible-error=[DataServices_DidB052_Data_CrashSts/E_NOT_OK, DataServices_DidB052_Data_CrashSts/E_PENDING]
        arg OpStatus: type=Dcm_OpStatusType, direction=IN
        arg ErrorCode: type=Dcm_NegativeResponseCodeType, direction=OUT
      error E_NOT_OK: error-code=1
      error E_PENDING: error-code=10
    DataServices_DidB053_Data_BMSBalSts
      operation ReadData: possible-error=DataServices_DidB053_Data_BMSBalSts/E_NOT_OK
        arg Data: type=Dcm_DataBuffer1FixedType, direction=OUT
      operation ConditionCheckRead: possible-error=[DataServices_DidB053_Data_BMSBalSts/E_NOT_OK, DataServices_DidB053_Data_BMSBalSts/E_PENDING]
        arg OpStatus: type=Dcm_OpStatusType, direction=IN
        arg ErrorCode: type=Dcm_NegativeResponseCodeType, direction=OUT
      error E_NOT_OK: error-code=1
      error E_PENDING: error-code=10
    DataServices_DidB054_Data_BMSBalCnt
      operation ReadData: possible-error=DataServices_DidB054_Data_BMSBalCnt/E_NOT_OK
        arg Data: type=Dcm_DataBuffer1FixedType, direction=OUT
      operation ConditionCheckRead: possible-error=[DataServices_DidB054_Data_BMSBalCnt/E_NOT_OK, DataServices_DidB054_Data_BMSBalCnt/E_PENDING]
        arg OpStatus: type=Dcm_OpStatusType, direction=IN
        arg ErrorCode: type=Dcm_NegativeResponseCodeType, direction=OUT
      error E_NOT_OK: error-code=1
      error E_PENDING: error-code=10
    DataServices_DidB055_Data_BMSEnergyAvail
      operation ReadData: possible-error=DataServices_DidB055_Data_BMSEnergyAvail/E_NOT_OK
        arg Data: type=Dcm_DataBuffer1FixedType, direction=OUT
      operation ConditionCheckRead: possible-error=[DataServices_DidB055_Data_BMSEnergyAvail/E_NOT_OK, DataServices_DidB055_Data_BMSEnergyAvail/E_PENDING]
        arg OpStatus: type=Dcm_OpStatusType, direction=IN
        arg ErrorCode: type=Dcm_NegativeResponseCodeType, direction=OUT
      error E_NOT_OK: error-code=1
      error E_PENDING: error-code=10
    DataServices_DidB056_Data_BMSCellTmax
      operation ReadData: possible-error=DataServices_DidB056_Data_BMSCellTmax/E_NOT_OK
        arg Data: type=Dcm_DataBuffer2FixedType, direction=OUT
      operation ConditionCheckRead: possible-error=[DataServices_DidB056_Data_BMSCellTmax/E_NOT_OK, DataServices_DidB056_Data_BMSCellTmax/E_PENDING]
        arg OpStatus: type=Dcm_OpStatusType, direction=IN
        arg ErrorCode: type=Dcm_NegativeResponseCodeType, direction=OUT
      error E_NOT_OK: error-code=1
      error E_PENDING: error-code=10
    DataServices_DidB057_Data_BMSCellTmin
      operation ReadData: possible-error=DataServices_DidB057_Data_BMSCellTmin/E_NOT_OK
        arg Data: type=Dcm_DataBuffer2FixedType, direction=OUT
      operation ConditionCheckRead: possible-error=[DataServices_DidB057_Data_BMSCellTmin/E_NOT_OK, DataServices_DidB057_Data_BMSCellTmin/E_PENDING]
        arg OpStatus: type=Dcm_OpStatusType, direction=IN
        arg ErrorCode: type=Dcm_NegativeResponseCodeType, direction=OUT
      error E_NOT_OK: error-code=1
      error E_PENDING: error-code=10
    DataServices_DidB058_Data_BMSCellVmax
      operation ReadData: possible-error=DataServices_DidB058_Data_BMSCellVmax/E_NOT_OK
        arg Data: type=Dcm_DataBuffer3FixedType, direction=OUT
      operation ConditionCheckRead: possible-error=[DataServices_DidB058_Data_BMSCellVmax/E_NOT_OK, DataServices_DidB058_Data_BMSCellVmax/E_PENDING]
        arg OpStatus: type=Dcm_OpStatusType, direction=IN
        arg ErrorCode: type=Dcm_NegativeResponseCodeType, direction=OUT
      error E_NOT_OK: error-code=1
      error E_PENDING: error-code=10
    DataServices_DidB059_Data_BMSCellVmin
      operation ReadData: possible-error=DataServices_DidB059_Data_BMSCellVmin/E_NOT_OK
        arg Data: type=Dcm_DataBuffer3FixedType, direction=OUT
      operation ConditionCheckRead: possible-error=[DataServices_DidB059_Data_BMSCellVmin/E_NOT_OK, DataServices_DidB059_Data_BMSCellVmin/E_PENDING]
        arg OpStatus: type=Dcm_OpStatusType, direction=IN
        arg ErrorCode: type=Dcm_NegativeResponseCodeType, direction=OUT
      error E_NOT_OK: error-code=1
      error E_PENDING: error-code=10
    DataServices_DidB05C_Data_BMSCoolantTemp
      operation ReadData: possible-error=DataServices_DidB05C_Data_BMSCoolantTemp/E_NOT_OK
        arg Data: type=Dcm_DataBuffer1FixedType, direction=OUT
      operation ConditionCheckRead: possible-error=[DataServices_DidB05C_Data_BMSCoolantTemp/E_NOT_OK, DataServices_DidB05C_Data_BMSCoolantTemp/E_PENDING]
        arg OpStatus: type=Dcm_OpStatusType, direction=IN
        arg ErrorCode: type=Dcm_NegativeResponseCodeType, direction=OUT
      error E_NOT_OK: error-code=1
      error E_PENDING: error-code=10
    DataServices_DidB05F_Data_BMSShuntTemp
      operation ReadData: possible-error=DataServices_DidB05F_Data_BMSShuntTemp/E_NOT_OK
        arg Data: type=Dcm_DataBuffer1FixedType, direction=OUT
      operation ConditionCheckRead: possible-error=[DataServices_DidB05F_Data_BMSShuntTemp/E_NOT_OK, DataServices_DidB05F_Data_BMSShuntTemp/E_PENDING]
        arg OpStatus: type=Dcm_OpStatusType, direction=IN
        arg ErrorCode: type=Dcm_NegativeResponseCodeType, direction=OUT
      error E_NOT_OK: error-code=1
      error E_PENDING: error-code=10
    DataServices_DidB061_Data_BMSPackSoh
      operation ReadData: possible-error=DataServices_DidB061_Data_BMSPackSoh/E_NOT_OK
        arg Data: type=Dcm_DataBuffer2FixedType, direction=OUT
      operation ConditionCheckRead: possible-error=[DataServices_DidB061_Data_BMSPackSoh/E_NOT_OK, DataServices_DidB061_Data_BMSPackSoh/E_PENDING]
        arg OpStatus: type=Dcm_OpStatusType, direction=IN
        arg ErrorCode: type=Dcm_NegativeResponseCodeType, direction=OUT
      error E_NOT_OK: error-code=1
      error E_PENDING: error-code=10
    DataServices_DidB062_Data_BMSPackCapFade
      operation ReadData: possible-error=DataServices_DidB062_Data_BMSPackCapFade/E_NOT_OK
        arg Data: type=Dcm_DataBuffer2FixedType, direction=OUT
      operation ConditionCheckRead: possible-error=[DataServices_DidB062_Data_BMSPackCapFade/E_NOT_OK, DataServices_DidB062_Data_BMSPackCapFade/E_PENDING]
        arg OpStatus: type=Dcm_OpStatusType, direction=IN
        arg ErrorCode: type=Dcm_NegativeResponseCodeType, direction=OUT
      error E_NOT_OK: error-code=1
      error E_PENDING: error-code=10
    DataServices_DidB063_Data_BMSPackResiGrw
      operation ReadData: possible-error=DataServices_DidB063_Data_BMSPackResiGrw/E_NOT_OK
        arg Data: type=Dcm_DataBuffer2FixedType, direction=OUT
      operation ConditionCheckRead: possible-error=[DataServices_DidB063_Data_BMSPackResiGrw/E_NOT_OK, DataServices_DidB063_Data_BMSPackResiGrw/E_PENDING]
        arg OpStatus: type=Dcm_OpStatusType, direction=IN
        arg ErrorCode: type=Dcm_NegativeResponseCodeType, direction=OUT
      error E_NOT_OK: error-code=1
      error E_PENDING: error-code=10
    DataServices_DidB064_Data_BMSCldAccumTime
      operation ReadData: possible-error=[DataServices_DidB064_Data_BMSCldAccumTime/E_NOT_OK, DataServices_DidB064_Data_BMSCldAccumTime/E_PENDING]
        arg OpStatus: type=Dcm_OpStatusType, direction=IN
        arg Data: type=Dcm_DataBuffer4FixedType, direction=OUT
      operation ConditionCheckRead: possible-error=[DataServices_DidB064_Data_BMSCldAccumTime/E_NOT_OK, DataServices_DidB064_Data_BMSCldAccumTime/E_PENDING]
        arg OpStatus: type=Dcm_OpStatusType, direction=IN
        arg ErrorCode: type=Dcm_NegativeResponseCodeType, direction=OUT
      operation WriteData: possible-error=[DataServices_DidB064_Data_BMSCldAccumTime/E_NOT_OK, DataServices_DidB064_Data_BMSCldAccumTime/E_PENDING]
        arg Data: type=Dcm_DataBuffer4FixedType, direction=INOUT
        arg OpStatus: type=Dcm_OpStatusType, direction=IN
        arg ErrorCode: type=Dcm_NegativeResponseCodeType, direction=OUT
      error E_NOT_OK: error-code=1
      error E_PENDING: error-code=10
    DataServices_DidB065_Data_BMSCldCapFade
      operation ReadData: possible-error=[DataServices_DidB065_Data_BMSCldCapFade/E_NOT_OK, DataServices_DidB065_Data_BMSCldCapFade/E_PENDING]
        arg OpStatus: type=Dcm_OpStatusType, direction=IN
        arg Data: type=Dcm_DataBuffer2FixedType, direction=OUT
      operation ConditionCheckRead: possible-error=[DataServices_DidB065_Data_BMSCldCapFade/E_NOT_OK, DataServices_DidB065_Data_BMSCldCapFade/E_PENDING]
        arg OpStatus: type=Dcm_OpStatusType, direction=IN
        arg ErrorCode: type=Dcm_NegativeResponseCodeType, direction=OUT
      operation WriteData: possible-error=[DataServices_DidB065_Data_BMSCldCapFade/E_NOT_OK, DataServices_DidB065_Data_BMSCldCapFade/E_PENDING]
        arg Data: type=Dcm_DataBuffer2FixedType, direction=INOUT
        arg OpStatus: type=Dcm_OpStatusType, direction=IN
        arg ErrorCode: type=Dcm_NegativeResponseCodeType, direction=OUT
      error E_NOT_OK: error-code=1
      error E_PENDING: error-code=10
    DataServices_DidB066_Data_BMSCldResiGrw
      operation ReadData: possible-error=[DataServices_DidB066_Data_BMSCldResiGrw/E_NOT_OK, DataServices_DidB066_Data_BMSCldResiGrw/E_PENDING]
        arg OpStatus: type=Dcm_OpStatusType, direction=IN
        arg Data: type=Dcm_DataBuffer2FixedType, direction=OUT
      operation ConditionCheckRead: possible-error=[DataServices_DidB066_Data_BMSCldResiGrw/E_NOT_OK, DataServices_DidB066_Data_BMSCldResiGrw/E_PENDING]
        arg OpStatus: type=Dcm_OpStatusType, direction=IN
        arg ErrorCode: type=Dcm_NegativeResponseCodeType, direction=OUT
      operation WriteData: possible-error=[DataServices_DidB066_Data_BMSCldResiGrw/E_NOT_OK, DataServices_DidB066_Data_BMSCldResiGrw/E_PENDING]
        arg Data: type=Dcm_DataBuffer2FixedType, direction=INOUT
        arg OpStatus: type=Dcm_OpStatusType, direction=IN
        arg ErrorCode: type=Dcm_NegativeResponseCodeType, direction=OUT
      error E_NOT_OK: error-code=1
      error E_PENDING: error-code=10
    DataServices_DidB067_Data_BMSCycAccumTime
      operation ReadData: possible-error=[DataServices_DidB067_Data_BMSCycAccumTime/E_NOT_OK, DataServices_DidB067_Data_BMSCycAccumTime/E_PENDING]
        arg OpStatus: type=Dcm_OpStatusType, direction=IN
        arg Data: type=Dcm_DataBuffer4FixedType, direction=OUT
      operation ConditionCheckRead: possible-error=[DataServices_DidB067_Data_BMSCycAccumTime/E_NOT_OK, DataServices_DidB067_Data_BMSCycAccumTime/E_PENDING]
        arg OpStatus: type=Dcm_OpStatusType, direction=IN
        arg ErrorCode: type=Dcm_NegativeResponseCodeType, direction=OUT
      operation WriteData: possible-error=[DataServices_DidB067_Data_BMSCycAccumTime/E_NOT_OK, DataServices_DidB067_Data_BMSCycAccumTime/E_PENDING]
        arg Data: type=Dcm_DataBuffer4FixedType, direction=INOUT
        arg OpStatus: type=Dcm_OpStatusType, direction=IN
        arg ErrorCode: type=Dcm_NegativeResponseCodeType, direction=OUT
      error E_NOT_OK: error-code=1
      error E_PENDING: error-code=10
    DataServices_DidB068_Data_BMSCycAccumEngy
      operation ReadData: possible-error=[DataServices_DidB068_Data_BMSCycAccumEngy/E_NOT_OK, DataServices_DidB068_Data_BMSCycAccumEngy/E_PENDING]
        arg OpStatus: type=Dcm_OpStatusType, direction=IN
        arg Data: type=Dcm_DataBuffer4FixedType, direction=OUT
      operation ConditionCheckRead: possible-error=[DataServices_DidB068_Data_BMSCycAccumEngy/E_NOT_OK, DataServices_DidB068_Data_BMSCycAccumEngy/E_PENDING]
        arg OpStatus: type=Dcm_OpStatusType, direction=IN
        arg ErrorCode: type=Dcm_NegativeResponseCodeType, direction=OUT
      operation WriteData: possible-error=[DataServices_DidB068_Data_BMSCycAccumEngy/E_NOT_OK, DataServices_DidB068_Data_BMSCycAccumEngy/E_PENDING]
        arg Data: type=Dcm_DataBuffer4FixedType, direction=INOUT
        arg OpStatus: type=Dcm_OpStatusType, direction=IN
        arg ErrorCode: type=Dcm_NegativeResponseCodeType, direction=OUT
      error E_NOT_OK: error-code=1
      error E_PENDING: error-code=10
    DataServices_DidB069_Data_BMSCycCapFade
      operation ReadData: possible-error=[DataServices_DidB069_Data_BMSCycCapFade/E_NOT_OK, DataServices_DidB069_Data_BMSCycCapFade/E_PENDING]
        arg OpStatus: type=Dcm_OpStatusType, direction=IN
        arg Data: type=Dcm_DataBuffer2FixedType, direction=OUT
      operation ConditionCheckRead: possible-error=[DataServices_DidB069_Data_BMSCycCapFade/E_NOT_OK, DataServices_DidB069_Data_BMSCycCapFade/E_PENDING]
        arg OpStatus: type=Dcm_OpStatusType, direction=IN
        arg ErrorCode: type=Dcm_NegativeResponseCodeType, direction=OUT
      operation WriteData: possible-error=[DataServices_DidB069_Data_BMSCycCapFade/E_NOT_OK, DataServices_DidB069_Data_BMSCycCapFade/E_PENDING]
        arg Data: type=Dcm_DataBuffer2FixedType, direction=INOUT
        arg OpStatus: type=Dcm_OpStatusType, direction=IN
        arg ErrorCode: type=Dcm_NegativeResponseCodeType, direction=OUT
      error E_NOT_OK: error-code=1
      error E_PENDING: error-code=10
    DataServices_DidB06A_Data_BMSCycResiGrw
      operation ReadData: possible-error=[DataServices_DidB06A_Data_BMSCycResiGrw/E_NOT_OK, DataServices_DidB06A_Data_BMSCycResiGrw/E_PENDING]
        arg OpStatus: type=Dcm_OpStatusType, direction=IN
        arg Data: type=Dcm_DataBuffer2FixedType, direction=OUT
      operation ConditionCheckRead: possible-error=[DataServices_DidB06A_Data_BMSCycResiGrw/E_NOT_OK, DataServices_DidB06A_Data_BMSCycResiGrw/E_PENDING]
        arg OpStatus: type=Dcm_OpStatusType, direction=IN
        arg ErrorCode: type=Dcm_NegativeResponseCodeType, direction=OUT
      operation WriteData: possible-error=[DataServices_DidB06A_Data_BMSCycResiGrw/E_NOT_OK, DataServices_DidB06A_Data_BMSCycResiGrw/E_PENDING]
        arg Data: type=Dcm_DataBuffer2FixedType, direction=INOUT
        arg OpStatus: type=Dcm_OpStatusType, direction=IN
        arg ErrorCode: type=Dcm_NegativeResponseCodeType, direction=OUT
      error E_NOT_OK: error-code=1
      error E_PENDING: error-code=10
    DataServices_DidB06D_Data_HvmRtcTime
      operation ReadData: possible-error=[DataServices_DidB06D_Data_HvmRtcTime/E_NOT_OK, DataServices_DidB06D_Data_HvmRtcTime/E_PENDING]
        arg OpStatus: type=Dcm_OpStatusType, direction=IN
        arg Data: type=Dcm_DataBuffer6FixedType, direction=OUT
      operation ConditionCheckRead: possible-error=[DataServices_DidB06D_Data_HvmRtcTime/E_NOT_OK, DataServices_DidB06D_Data_HvmRtcTime/E_PENDING]
        arg OpStatus: type=Dcm_OpStatusType, direction=IN
        arg ErrorCode: type=Dcm_NegativeResponseCodeType, direction=OUT
      operation WriteData: possible-error=[DataServices_DidB06D_Data_HvmRtcTime/E_NOT_OK, DataServices_DidB06D_Data_HvmRtcTime/E_PENDING]
        arg Data: type=Dcm_DataBuffer6FixedType, direction=INOUT
        arg OpStatus: type=Dcm_OpStatusType, direction=IN
        arg ErrorCode: type=Dcm_NegativeResponseCodeType, direction=OUT
      error E_NOT_OK: error-code=1
      error E_PENDING: error-code=10
    DataServices_DidB072_Data_BMSAccumAhLower
      operation ReadData: possible-error=[DataServices_DidB072_Data_BMSAccumAhLower/E_NOT_OK, DataServices_DidB072_Data_BMSAccumAhLower/E_PENDING]
        arg OpStatus: type=Dcm_OpStatusType, direction=IN
        arg Data: type=Dcm_DataBuffer2FixedType, direction=OUT
      operation ConditionCheckRead: possible-error=[DataServices_DidB072_Data_BMSAccumAhLower/E_NOT_OK, DataServices_DidB072_Data_BMSAccumAhLower/E_PENDING]
        arg OpStatus: type=Dcm_OpStatusType, direction=IN
        arg ErrorCode: type=Dcm_NegativeResponseCodeType, direction=OUT
      operation WriteData: possible-error=[DataServices_DidB072_Data_BMSAccumAhLower/E_NOT_OK, DataServices_DidB072_Data_BMSAccumAhLower/E_PENDING]
        arg Data: type=Dcm_DataBuffer2FixedType, direction=INOUT
        arg OpStatus: type=Dcm_OpStatusType, direction=IN
        arg ErrorCode: type=Dcm_NegativeResponseCodeType, direction=OUT
      error E_NOT_OK: error-code=1
      error E_PENDING: error-code=10
    DataServices_DidB073_Data_BMSAccumAhUpper
      operation ReadData: possible-error=[DataServices_DidB073_Data_BMSAccumAhUpper/E_NOT_OK, DataServices_DidB073_Data_BMSAccumAhUpper/E_PENDING]
        arg OpStatus: type=Dcm_OpStatusType, direction=IN
        arg Data: type=Dcm_DataBuffer2FixedType, direction=OUT
      operation ConditionCheckRead: possible-error=[DataServices_DidB073_Data_BMSAccumAhUpper/E_NOT_OK, DataServices_DidB073_Data_BMSAccumAhUpper/E_PENDING]
        arg OpStatus: type=Dcm_OpStatusType, direction=IN
        arg ErrorCode: type=Dcm_NegativeResponseCodeType, direction=OUT
      operation WriteData: possible-error=[DataServices_DidB073_Data_BMSAccumAhUpper/E_NOT_OK, DataServices_DidB073_Data_BMSAccumAhUpper/E_PENDING]
        arg Data: type=Dcm_DataBuffer2FixedType, direction=INOUT
        arg OpStatus: type=Dcm_OpStatusType, direction=IN
        arg ErrorCode: type=Dcm_NegativeResponseCodeType, direction=OUT
      error E_NOT_OK: error-code=1
      error E_PENDING: error-code=10
    DataServices_DidB074_Data_BMSCellTemDiffTime
      operation ReadData: possible-error=[DataServices_DidB074_Data_BMSCellTemDiffTime/E_NOT_OK, DataServices_DidB074_Data_BMSCellTemDiffTime/E_PENDING]
        arg OpStatus: type=Dcm_OpStatusType, direction=IN
        arg Data: type=Dcm_DataBuffer4FixedType, direction=OUT
      operation ConditionCheckRead: possible-error=[DataServices_DidB074_Data_BMSCellTemDiffTime/E_NOT_OK, DataServices_DidB074_Data_BMSCellTemDiffTime/E_PENDING]
        arg OpStatus: type=Dcm_OpStatusType, direction=IN
        arg ErrorCode: type=Dcm_NegativeResponseCodeType, direction=OUT
      operation WriteData: possible-error=[DataServices_DidB074_Data_BMSCellTemDiffTime/E_NOT_OK, DataServices_DidB074_Data_BMSCellTemDiffTime/E_PENDING]
        arg Data: type=Dcm_DataBuffer4FixedType, direction=INOUT
        arg OpStatus: type=Dcm_OpStatusType, direction=IN
        arg ErrorCode: type=Dcm_NegativeResponseCodeType, direction=OUT
      error E_NOT_OK: error-code=1
      error E_PENDING: error-code=10
    DataServices_DidB075_Data_UnlockLogi
      operation ReadData: possible-error=[DataServices_DidB075_Data_UnlockLogi/E_NOT_OK, DataServices_DidB075_Data_UnlockLogi/E_PENDING]
        arg OpStatus: type=Dcm_OpStatusType, direction=IN
        arg Data: type=Dcm_DataBuffer1FixedType, direction=OUT
      operation ConditionCheckRead: possible-error=[DataServices_DidB075_Data_UnlockLogi/E_NOT_OK, DataServices_DidB075_Data_UnlockLogi/E_PENDING]
        arg OpStatus: type=Dcm_OpStatusType, direction=IN
        arg ErrorCode: type=Dcm_NegativeResponseCodeType, direction=OUT
      operation WriteData: possible-error=[DataServices_DidB075_Data_UnlockLogi/E_NOT_OK, DataServices_DidB075_Data_UnlockLogi/E_PENDING]
        arg Data: type=Dcm_DataBuffer1FixedType, direction=INOUT
        arg OpStatus: type=Dcm_OpStatusType, direction=IN
        arg ErrorCode: type=Dcm_NegativeResponseCodeType, direction=OUT
      error E_NOT_OK: error-code=1
      error E_PENDING: error-code=10
    DataServices_DidB076_Data_BMSOffChgAccumTime
      operation ReadData: possible-error=[DataServices_DidB076_Data_BMSOffChgAccumTime/E_NOT_OK, DataServices_DidB076_Data_BMSOffChgAccumTime/E_PENDING]
        arg OpStatus: type=Dcm_OpStatusType, direction=IN
        arg Data: type=Dcm_DataBuffer4FixedType, direction=OUT
      operation ConditionCheckRead: possible-error=[DataServices_DidB076_Data_BMSOffChgAccumTime/E_NOT_OK, DataServices_DidB076_Data_BMSOffChgAccumTime/E_PENDING]
        arg OpStatus: type=Dcm_OpStatusType, direction=IN
        arg ErrorCode: type=Dcm_NegativeResponseCodeType, direction=OUT
      operation WriteData: possible-error=[DataServices_DidB076_Data_BMSOffChgAccumTime/E_NOT_OK, DataServices_DidB076_Data_BMSOffChgAccumTime/E_PENDING]
        arg Data: type=Dcm_DataBuffer4FixedType, direction=INOUT
        arg OpStatus: type=Dcm_OpStatusType, direction=IN
        arg ErrorCode: type=Dcm_NegativeResponseCodeType, direction=OUT
      error E_NOT_OK: error-code=1
      error E_PENDING: error-code=10
    DataServices_DidB080_Data_BMSBalanceTime
      operation ReadData: possible-error=[DataServices_DidB080_Data_BMSBalanceTime/E_NOT_OK, DataServices_DidB080_Data_BMSBalanceTime/E_PENDING]
        arg OpStatus: type=Dcm_OpStatusType, direction=IN
        arg Data: type=Dcm_DataBuffer2FixedType, direction=OUT
      operation ConditionCheckRead: possible-error=[DataServices_DidB080_Data_BMSBalanceTime/E_NOT_OK, DataServices_DidB080_Data_BMSBalanceTime/E_PENDING]
        arg OpStatus: type=Dcm_OpStatusType, direction=IN
        arg ErrorCode: type=Dcm_NegativeResponseCodeType, direction=OUT
      operation WriteData: possible-error=[DataServices_DidB080_Data_BMSBalanceTime/E_NOT_OK, DataServices_DidB080_Data_BMSBalanceTime/E_PENDING]
        arg Data: type=Dcm_DataBuffer2FixedType, direction=INOUT
        arg OpStatus: type=Dcm_OpStatusType, direction=IN
        arg ErrorCode: type=Dcm_NegativeResponseCodeType, direction=OUT
      error E_NOT_OK: error-code=1
      error E_PENDING: error-code=10
    DataServices_DidB081_Data_CMUMissingCnt
      operation ReadData: possible-error=[DataServices_DidB081_Data_CMUMissingCnt/E_NOT_OK, DataServices_DidB081_Data_CMUMissingCnt/E_PENDING]
        arg OpStatus: type=Dcm_OpStatusType, direction=IN
        arg Data: type=Dcm_DataBuffer2FixedType, direction=OUT
      operation ConditionCheckRead: possible-error=[DataServices_DidB081_Data_CMUMissingCnt/E_NOT_OK, DataServices_DidB081_Data_CMUMissingCnt/E_PENDING]
        arg OpStatus: type=Dcm_OpStatusType, direction=IN
        arg ErrorCode: type=Dcm_NegativeResponseCodeType, direction=OUT
      operation WriteData: possible-error=[DataServices_DidB081_Data_CMUMissingCnt/E_NOT_OK, DataServices_DidB081_Data_CMUMissingCnt/E_PENDING]
        arg Data: type=Dcm_DataBuffer2FixedType, direction=INOUT
        arg OpStatus: type=Dcm_OpStatusType, direction=IN
        arg ErrorCode: type=Dcm_NegativeResponseCodeType, direction=OUT
      error E_NOT_OK: error-code=1
      error E_PENDING: error-code=10
    DataServices_DidB082_Data_CMUMissingTime
      operation ReadData: possible-error=[DataServices_DidB082_Data_CMUMissingTime/E_NOT_OK, DataServices_DidB082_Data_CMUMissingTime/E_PENDING]
        arg OpStatus: type=Dcm_OpStatusType, direction=IN
        arg Data: type=Dcm_DataBuffer2FixedType, direction=OUT
      operation ConditionCheckRead: possible-error=[DataServices_DidB082_Data_CMUMissingTime/E_NOT_OK, DataServices_DidB082_Data_CMUMissingTime/E_PENDING]
        arg OpStatus: type=Dcm_OpStatusType, direction=IN
        arg ErrorCode: type=Dcm_NegativeResponseCodeType, direction=OUT
      operation WriteData: possible-error=[DataServices_DidB082_Data_CMUMissingTime/E_NOT_OK, DataServices_DidB082_Data_CMUMissingTime/E_PENDING]
        arg Data: type=Dcm_DataBuffer2FixedType, direction=INOUT
        arg OpStatus: type=Dcm_OpStatusType, direction=IN
        arg ErrorCode: type=Dcm_NegativeResponseCodeType, direction=OUT
      error E_NOT_OK: error-code=1
      error E_PENDING: error-code=10
    DataServices_DidB083_Data_ExtPackLeakageFltCnt
      operation ReadData: possible-error=[DataServices_DidB083_Data_ExtPackLeakageFltCnt/E_NOT_OK, DataServices_DidB083_Data_ExtPackLeakageFltCnt/E_PENDING]
        arg OpStatus: type=Dcm_OpStatusType, direction=IN
        arg Data: type=Dcm_DataBuffer2FixedType, direction=OUT
      operation ConditionCheckRead: possible-error=[DataServices_DidB083_Data_ExtPackLeakageFltCnt/E_NOT_OK, DataServices_DidB083_Data_ExtPackLeakageFltCnt/E_PENDING]
        arg OpStatus: type=Dcm_OpStatusType, direction=IN
        arg ErrorCode: type=Dcm_NegativeResponseCodeType, direction=OUT
      operation WriteData: possible-error=[DataServices_DidB083_Data_ExtPackLeakageFltCnt/E_NOT_OK, DataServices_DidB083_Data_ExtPackLeakageFltCnt/E_PENDING]
        arg Data: type=Dcm_DataBuffer2FixedType, direction=INOUT
        arg OpStatus: type=Dcm_OpStatusType, direction=IN
        arg ErrorCode: type=Dcm_NegativeResponseCodeType, direction=OUT
      error E_NOT_OK: error-code=1
      error E_PENDING: error-code=10
    DataServices_DidB084_Data_IntPackLeakageFltCnt
      operation ReadData: possible-error=[DataServices_DidB084_Data_IntPackLeakageFltCnt/E_NOT_OK, DataServices_DidB084_Data_IntPackLeakageFltCnt/E_PENDING]
        arg OpStatus: type=Dcm_OpStatusType, direction=IN
        arg Data: type=Dcm_DataBuffer2FixedType, direction=OUT
      operation ConditionCheckRead: possible-error=[DataServices_DidB084_Data_IntPackLeakageFltCnt/E_NOT_OK, DataServices_DidB084_Data_IntPackLeakageFltCnt/E_PENDING]
        arg OpStatus: type=Dcm_OpStatusType, direction=IN
        arg ErrorCode: type=Dcm_NegativeResponseCodeType, direction=OUT
      operation WriteData: possible-error=[DataServices_DidB084_Data_IntPackLeakageFltCnt/E_NOT_OK, DataServices_DidB084_Data_IntPackLeakageFltCnt/E_PENDING]
        arg Data: type=Dcm_DataBuffer2FixedType, direction=INOUT
        arg OpStatus: type=Dcm_OpStatusType, direction=IN
        arg ErrorCode: type=Dcm_NegativeResponseCodeType, direction=OUT
      error E_NOT_OK: error-code=1
      error E_PENDING: error-code=10
    DataServices_DidB085_Data_CellOverVoltageCnt
      operation ReadData: possible-error=[DataServices_DidB085_Data_CellOverVoltageCnt/E_NOT_OK, DataServices_DidB085_Data_CellOverVoltageCnt/E_PENDING]
        arg OpStatus: type=Dcm_OpStatusType, direction=IN
        arg Data: type=Dcm_DataBuffer2FixedType, direction=OUT
      operation ConditionCheckRead: possible-error=[DataServices_DidB085_Data_CellOverVoltageCnt/E_NOT_OK, DataServices_DidB085_Data_CellOverVoltageCnt/E_PENDING]
        arg OpStatus: type=Dcm_OpStatusType, direction=IN
        arg ErrorCode: type=Dcm_NegativeResponseCodeType, direction=OUT
      operation WriteData: possible-error=[DataServices_DidB085_Data_CellOverVoltageCnt/E_NOT_OK, DataServices_DidB085_Data_CellOverVoltageCnt/E_PENDING]
        arg Data: type=Dcm_DataBuffer2FixedType, direction=INOUT
        arg OpStatus: type=Dcm_OpStatusType, direction=IN
        arg ErrorCode: type=Dcm_NegativeResponseCodeType, direction=OUT
      error E_NOT_OK: error-code=1
      error E_PENDING: error-code=10
    DataServices_DidB086_Data_PrechrgResEnrgExCnt
      operation ReadData: possible-error=[DataServices_DidB086_Data_PrechrgResEnrgExCnt/E_NOT_OK, DataServices_DidB086_Data_PrechrgResEnrgExCnt/E_PENDING]
        arg OpStatus: type=Dcm_OpStatusType, direction=IN
        arg Data: type=Dcm_DataBuffer2FixedType, direction=OUT
      operation ConditionCheckRead: possible-error=[DataServices_DidB086_Data_PrechrgResEnrgExCnt/E_NOT_OK, DataServices_DidB086_Data_PrechrgResEnrgExCnt/E_PENDING]
        arg OpStatus: type=Dcm_OpStatusType, direction=IN
        arg ErrorCode: type=Dcm_NegativeResponseCodeType, direction=OUT
      operation WriteData: possible-error=[DataServices_DidB086_Data_PrechrgResEnrgExCnt/E_NOT_OK, DataServices_DidB086_Data_PrechrgResEnrgExCnt/E_PENDING]
        arg Data: type=Dcm_DataBuffer2FixedType, direction=INOUT
        arg OpStatus: type=Dcm_OpStatusType, direction=IN
        arg ErrorCode: type=Dcm_NegativeResponseCodeType, direction=OUT
      error E_NOT_OK: error-code=1
      error E_PENDING: error-code=10
    DataServices_DidB087_Data_PrechrgTimeOutExCnt
      operation ReadData: possible-error=[DataServices_DidB087_Data_PrechrgTimeOutExCnt/E_NOT_OK, DataServices_DidB087_Data_PrechrgTimeOutExCnt/E_PENDING]
        arg OpStatus: type=Dcm_OpStatusType, direction=IN
        arg Data: type=Dcm_DataBuffer2FixedType, direction=OUT
      operation ConditionCheckRead: possible-error=[DataServices_DidB087_Data_PrechrgTimeOutExCnt/E_NOT_OK, DataServices_DidB087_Data_PrechrgTimeOutExCnt/E_PENDING]
        arg OpStatus: type=Dcm_OpStatusType, direction=IN
        arg ErrorCode: type=Dcm_NegativeResponseCodeType, direction=OUT
      operation WriteData: possible-error=[DataServices_DidB087_Data_PrechrgTimeOutExCnt/E_NOT_OK, DataServices_DidB087_Data_PrechrgTimeOutExCnt/E_PENDING]
        arg Data: type=Dcm_DataBuffer2FixedType, direction=INOUT
        arg OpStatus: type=Dcm_OpStatusType, direction=IN
        arg ErrorCode: type=Dcm_NegativeResponseCodeType, direction=OUT
      error E_NOT_OK: error-code=1
      error E_PENDING: error-code=10
    DataServices_DidB088_Data_RlyOpenWithCrntCnt
      operation ReadData: possible-error=[DataServices_DidB088_Data_RlyOpenWithCrntCnt/E_NOT_OK, DataServices_DidB088_Data_RlyOpenWithCrntCnt/E_PENDING]
        arg OpStatus: type=Dcm_OpStatusType, direction=IN
        arg Data: type=Dcm_DataBuffer2FixedType, direction=OUT
      operation ConditionCheckRead: possible-error=[DataServices_DidB088_Data_RlyOpenWithCrntCnt/E_NOT_OK, DataServices_DidB088_Data_RlyOpenWithCrntCnt/E_PENDING]
        arg OpStatus: type=Dcm_OpStatusType, direction=IN
        arg ErrorCode: type=Dcm_NegativeResponseCodeType, direction=OUT
      operation WriteData: possible-error=[DataServices_DidB088_Data_RlyOpenWithCrntCnt/E_NOT_OK, DataServices_DidB088_Data_RlyOpenWithCrntCnt/E_PENDING]
        arg Data: type=Dcm_DataBuffer2FixedType, direction=INOUT
        arg OpStatus: type=Dcm_OpStatusType, direction=IN
        arg ErrorCode: type=Dcm_NegativeResponseCodeType, direction=OUT
      error E_NOT_OK: error-code=1
      error E_PENDING: error-code=10
    DataServices_DidB089_Data_RlyOpenWithCrntLvl1Cnt
      operation ReadData: possible-error=[DataServices_DidB089_Data_RlyOpenWithCrntLvl1Cnt/E_NOT_OK, DataServices_DidB089_Data_RlyOpenWithCrntLvl1Cnt/E_PENDING]
        arg OpStatus: type=Dcm_OpStatusType, direction=IN
        arg Data: type=Dcm_DataBuffer2FixedType, direction=OUT
      operation ConditionCheckRead: possible-error=[DataServices_DidB089_Data_RlyOpenWithCrntLvl1Cnt/E_NOT_OK, DataServices_DidB089_Data_RlyOpenWithCrntLvl1Cnt/E_PENDING]
        arg OpStatus: type=Dcm_OpStatusType, direction=IN
        arg ErrorCode: type=Dcm_NegativeResponseCodeType, direction=OUT
      operation WriteData: possible-error=[DataServices_DidB089_Data_RlyOpenWithCrntLvl1Cnt/E_NOT_OK, DataServices_DidB089_Data_RlyOpenWithCrntLvl1Cnt/E_PENDING]
        arg Data: type=Dcm_DataBuffer2FixedType, direction=INOUT
        arg OpStatus: type=Dcm_OpStatusType, direction=IN
        arg ErrorCode: type=Dcm_NegativeResponseCodeType, direction=OUT
      error E_NOT_OK: error-code=1
      error E_PENDING: error-code=10
    DataServices_DidB08A_Data_RlyOpenWithCrntLvl2Cnt
      operation ReadData: possible-error=[DataServices_DidB08A_Data_RlyOpenWithCrntLvl2Cnt/E_NOT_OK, DataServices_DidB08A_Data_RlyOpenWithCrntLvl2Cnt/E_PENDING]
        arg OpStatus: type=Dcm_OpStatusType, direction=IN
        arg Data: type=Dcm_DataBuffer2FixedType, direction=OUT
      operation ConditionCheckRead: possible-error=[DataServices_DidB08A_Data_RlyOpenWithCrntLvl2Cnt/E_NOT_OK, DataServices_DidB08A_Data_RlyOpenWithCrntLvl2Cnt/E_PENDING]
        arg OpStatus: type=Dcm_OpStatusType, direction=IN
        arg ErrorCode: type=Dcm_NegativeResponseCodeType, direction=OUT
      operation WriteData: possible-error=[DataServices_DidB08A_Data_RlyOpenWithCrntLvl2Cnt/E_NOT_OK, DataServices_DidB08A_Data_RlyOpenWithCrntLvl2Cnt/E_PENDING]
        arg Data: type=Dcm_DataBuffer2FixedType, direction=INOUT
        arg OpStatus: type=Dcm_OpStatusType, direction=IN
        arg ErrorCode: type=Dcm_NegativeResponseCodeType, direction=OUT
      error E_NOT_OK: error-code=1
      error E_PENDING: error-code=10
    DataServices_DidB08B_Data_RlyOpenWithCrntLvl3Cnt
      operation ReadData: possible-error=[DataServices_DidB08B_Data_RlyOpenWithCrntLvl3Cnt/E_NOT_OK, DataServices_DidB08B_Data_RlyOpenWithCrntLvl3Cnt/E_PENDING]
        arg OpStatus: type=Dcm_OpStatusType, direction=IN
        arg Data: type=Dcm_DataBuffer2FixedType, direction=OUT
      operation ConditionCheckRead: possible-error=[DataServices_DidB08B_Data_RlyOpenWithCrntLvl3Cnt/E_NOT_OK, DataServices_DidB08B_Data_RlyOpenWithCrntLvl3Cnt/E_PENDING]
        arg OpStatus: type=Dcm_OpStatusType, direction=IN
        arg ErrorCode: type=Dcm_NegativeResponseCodeType, direction=OUT
      operation WriteData: possible-error=[DataServices_DidB08B_Data_RlyOpenWithCrntLvl3Cnt/E_NOT_OK, DataServices_DidB08B_Data_RlyOpenWithCrntLvl3Cnt/E_PENDING]
        arg Data: type=Dcm_DataBuffer2FixedType, direction=INOUT
        arg OpStatus: type=Dcm_OpStatusType, direction=IN
        arg ErrorCode: type=Dcm_NegativeResponseCodeType, direction=OUT
      error E_NOT_OK: error-code=1
      error E_PENDING: error-code=10
    DataServices_DidB08C_Data_PackSOCLowTime
      operation ReadData: possible-error=[DataServices_DidB08C_Data_PackSOCLowTime/E_NOT_OK, DataServices_DidB08C_Data_PackSOCLowTime/E_PENDING]
        arg OpStatus: type=Dcm_OpStatusType, direction=IN
        arg Data: type=Dcm_DataBuffer2FixedType, direction=OUT
      operation ConditionCheckRead: possible-error=[DataServices_DidB08C_Data_PackSOCLowTime/E_NOT_OK, DataServices_DidB08C_Data_PackSOCLowTime/E_PENDING]
        arg OpStatus: type=Dcm_OpStatusType, direction=IN
        arg ErrorCode: type=Dcm_NegativeResponseCodeType, direction=OUT
      operation WriteData: possible-error=[DataServices_DidB08C_Data_PackSOCLowTime/E_NOT_OK, DataServices_DidB08C_Data_PackSOCLowTime/E_PENDING]
        arg Data: type=Dcm_DataBuffer2FixedType, direction=INOUT
        arg OpStatus: type=Dcm_OpStatusType, direction=IN
        arg ErrorCode: type=Dcm_NegativeResponseCodeType, direction=OUT
      error E_NOT_OK: error-code=1
      error E_PENDING: error-code=10
    DataServices_DidB08D_Data_CellUnderVoltageCnt
      operation ReadData: possible-error=[DataServices_DidB08D_Data_CellUnderVoltageCnt/E_NOT_OK, DataServices_DidB08D_Data_CellUnderVoltageCnt/E_PENDING]
        arg OpStatus: type=Dcm_OpStatusType, direction=IN
        arg Data: type=Dcm_DataBuffer2FixedType, direction=OUT
      operation ConditionCheckRead: possible-error=[DataServices_DidB08D_Data_CellUnderVoltageCnt/E_NOT_OK, DataServices_DidB08D_Data_CellUnderVoltageCnt/E_PENDING]
        arg OpStatus: type=Dcm_OpStatusType, direction=IN
        arg ErrorCode: type=Dcm_NegativeResponseCodeType, direction=OUT
      operation WriteData: possible-error=[DataServices_DidB08D_Data_CellUnderVoltageCnt/E_NOT_OK, DataServices_DidB08D_Data_CellUnderVoltageCnt/E_PENDING]
        arg Data: type=Dcm_DataBuffer2FixedType, direction=INOUT
        arg OpStatus: type=Dcm_OpStatusType, direction=IN
        arg ErrorCode: type=Dcm_NegativeResponseCodeType, direction=OUT
      error E_NOT_OK: error-code=1
      error E_PENDING: error-code=10
    DataServices_DidB08E_Data_TempLvl1Cnt
      operation ReadData: possible-error=[DataServices_DidB08E_Data_TempLvl1Cnt/E_NOT_OK, DataServices_DidB08E_Data_TempLvl1Cnt/E_PENDING]
        arg OpStatus: type=Dcm_OpStatusType, direction=IN
        arg Data: type=Dcm_DataBuffer2FixedType, direction=OUT
      operation ConditionCheckRead: possible-error=[DataServices_DidB08E_Data_TempLvl1Cnt/E_NOT_OK, DataServices_DidB08E_Data_TempLvl1Cnt/E_PENDING]
        arg OpStatus: type=Dcm_OpStatusType, direction=IN
        arg ErrorCode: type=Dcm_NegativeResponseCodeType, direction=OUT
      operation WriteData: possible-error=[DataServices_DidB08E_Data_TempLvl1Cnt/E_NOT_OK, DataServices_DidB08E_Data_TempLvl1Cnt/E_PENDING]
        arg Data: type=Dcm_DataBuffer2FixedType, direction=INOUT
        arg OpStatus: type=Dcm_OpStatusType, direction=IN
        arg ErrorCode: type=Dcm_NegativeResponseCodeType, direction=OUT
      error E_NOT_OK: error-code=1
      error E_PENDING: error-code=10
    DataServices_DidB08F_Data_TempLvl2Cnt
      operation ReadData: possible-error=[DataServices_DidB08F_Data_TempLvl2Cnt/E_NOT_OK, DataServices_DidB08F_Data_TempLvl2Cnt/E_PENDING]
        arg OpStatus: type=Dcm_OpStatusType, direction=IN
        arg Data: type=Dcm_DataBuffer2FixedType, direction=OUT
      operation ConditionCheckRead: possible-error=[DataServices_DidB08F_Data_TempLvl2Cnt/E_NOT_OK, DataServices_DidB08F_Data_TempLvl2Cnt/E_PENDING]
        arg OpStatus: type=Dcm_OpStatusType, direction=IN
        arg ErrorCode: type=Dcm_NegativeResponseCodeType, direction=OUT
      operation WriteData: possible-error=[DataServices_DidB08F_Data_TempLvl2Cnt/E_NOT_OK, DataServices_DidB08F_Data_TempLvl2Cnt/E_PENDING]
        arg Data: type=Dcm_DataBuffer2FixedType, direction=INOUT
        arg OpStatus: type=Dcm_OpStatusType, direction=IN
        arg ErrorCode: type=Dcm_NegativeResponseCodeType, direction=OUT
      error E_NOT_OK: error-code=1
      error E_PENDING: error-code=10
    DataServices_DidB090_Data_TempLvl3Cnt
      operation ReadData: possible-error=[DataServices_DidB090_Data_TempLvl3Cnt/E_NOT_OK, DataServices_DidB090_Data_TempLvl3Cnt/E_PENDING]
        arg OpStatus: type=Dcm_OpStatusType, direction=IN
        arg Data: type=Dcm_DataBuffer2FixedType, direction=OUT
      operation ConditionCheckRead: possible-error=[DataServices_DidB090_Data_TempLvl3Cnt/E_NOT_OK, DataServices_DidB090_Data_TempLvl3Cnt/E_PENDING]
        arg OpStatus: type=Dcm_OpStatusType, direction=IN
        arg ErrorCode: type=Dcm_NegativeResponseCodeType, direction=OUT
      operation WriteData: possible-error=[DataServices_DidB090_Data_TempLvl3Cnt/E_NOT_OK, DataServices_DidB090_Data_TempLvl3Cnt/E_PENDING]
        arg Data: type=Dcm_DataBuffer2FixedType, direction=INOUT
        arg OpStatus: type=Dcm_OpStatusType, direction=IN
        arg ErrorCode: type=Dcm_NegativeResponseCodeType, direction=OUT
      error E_NOT_OK: error-code=1
      error E_PENDING: error-code=10
    DataServices_DidB091_Data_TempLvl4Cnt
      operation ReadData: possible-error=[DataServices_DidB091_Data_TempLvl4Cnt/E_NOT_OK, DataServices_DidB091_Data_TempLvl4Cnt/E_PENDING]
        arg OpStatus: type=Dcm_OpStatusType, direction=IN
        arg Data: type=Dcm_DataBuffer2FixedType, direction=OUT
      operation ConditionCheckRead: possible-error=[DataServices_DidB091_Data_TempLvl4Cnt/E_NOT_OK, DataServices_DidB091_Data_TempLvl4Cnt/E_PENDING]
        arg OpStatus: type=Dcm_OpStatusType, direction=IN
        arg ErrorCode: type=Dcm_NegativeResponseCodeType, direction=OUT
      operation WriteData: possible-error=[DataServices_DidB091_Data_TempLvl4Cnt/E_NOT_OK, DataServices_DidB091_Data_TempLvl4Cnt/E_PENDING]
        arg Data: type=Dcm_DataBuffer2FixedType, direction=INOUT
        arg OpStatus: type=Dcm_OpStatusType, direction=IN
        arg ErrorCode: type=Dcm_NegativeResponseCodeType, direction=OUT
      error E_NOT_OK: error-code=1
      error E_PENDING: error-code=10
    DataServices_DidB092_Data_TempLvl5Cnt
      operation ReadData: possible-error=[DataServices_DidB092_Data_TempLvl5Cnt/E_NOT_OK, DataServices_DidB092_Data_TempLvl5Cnt/E_PENDING]
        arg OpStatus: type=Dcm_OpStatusType, direction=IN
        arg Data: type=Dcm_DataBuffer2FixedType, direction=OUT
      operation ConditionCheckRead: possible-error=[DataServices_DidB092_Data_TempLvl5Cnt/E_NOT_OK, DataServices_DidB092_Data_TempLvl5Cnt/E_PENDING]
        arg OpStatus: type=Dcm_OpStatusType, direction=IN
        arg ErrorCode: type=Dcm_NegativeResponseCodeType, direction=OUT
      operation WriteData: possible-error=[DataServices_DidB092_Data_TempLvl5Cnt/E_NOT_OK, DataServices_DidB092_Data_TempLvl5Cnt/E_PENDING]
        arg Data: type=Dcm_DataBuffer2FixedType, direction=INOUT
        arg OpStatus: type=Dcm_OpStatusType, direction=IN
        arg ErrorCode: type=Dcm_NegativeResponseCodeType, direction=OUT
      error E_NOT_OK: error-code=1
      error E_PENDING: error-code=10
    DataServices_DidB093_Data_TempLvl6Cnt
      operation ReadData: possible-error=[DataServices_DidB093_Data_TempLvl6Cnt/E_NOT_OK, DataServices_DidB093_Data_TempLvl6Cnt/E_PENDING]
        arg OpStatus: type=Dcm_OpStatusType, direction=IN
        arg Data: type=Dcm_DataBuffer2FixedType, direction=OUT
      operation ConditionCheckRead: possible-error=[DataServices_DidB093_Data_TempLvl6Cnt/E_NOT_OK, DataServices_DidB093_Data_TempLvl6Cnt/E_PENDING]
        arg OpStatus: type=Dcm_OpStatusType, direction=IN
        arg ErrorCode: type=Dcm_NegativeResponseCodeType, direction=OUT
      operation WriteData: possible-error=[DataServices_DidB093_Data_TempLvl6Cnt/E_NOT_OK, DataServices_DidB093_Data_TempLvl6Cnt/E_PENDING]
        arg Data: type=Dcm_DataBuffer2FixedType, direction=INOUT
        arg OpStatus: type=Dcm_OpStatusType, direction=IN
        arg ErrorCode: type=Dcm_NegativeResponseCodeType, direction=OUT
      error E_NOT_OK: error-code=1
      error E_PENDING: error-code=10
    DataServices_DidB094_Data_TempLvl7Cnt
      operation ReadData: possible-error=[DataServices_DidB094_Data_TempLvl7Cnt/E_NOT_OK, DataServices_DidB094_Data_TempLvl7Cnt/E_PENDING]
        arg OpStatus: type=Dcm_OpStatusType, direction=IN
        arg Data: type=Dcm_DataBuffer2FixedType, direction=OUT
      operation ConditionCheckRead: possible-error=[DataServices_DidB094_Data_TempLvl7Cnt/E_NOT_OK, DataServices_DidB094_Data_TempLvl7Cnt/E_PENDING]
        arg OpStatus: type=Dcm_OpStatusType, direction=IN
        arg ErrorCode: type=Dcm_NegativeResponseCodeType, direction=OUT
      operation WriteData: possible-error=[DataServices_DidB094_Data_TempLvl7Cnt/E_NOT_OK, DataServices_DidB094_Data_TempLvl7Cnt/E_PENDING]
        arg Data: type=Dcm_DataBuffer2FixedType, direction=INOUT
        arg OpStatus: type=Dcm_OpStatusType, direction=IN
        arg ErrorCode: type=Dcm_NegativeResponseCodeType, direction=OUT
      error E_NOT_OK: error-code=1
      error E_PENDING: error-code=10
    DataServices_DidB095_Data_BMSOnChgEngy
      operation ReadData: possible-error=[DataServices_DidB095_Data_BMSOnChgEngy/E_NOT_OK, DataServices_DidB095_Data_BMSOnChgEngy/E_PENDING]
        arg OpStatus: type=Dcm_OpStatusType, direction=IN
        arg Data: type=Dcm_DataBuffer2FixedType, direction=OUT
      operation ConditionCheckRead: possible-error=[DataServices_DidB095_Data_BMSOnChgEngy/E_NOT_OK, DataServices_DidB095_Data_BMSOnChgEngy/E_PENDING]
        arg OpStatus: type=Dcm_OpStatusType, direction=IN
        arg ErrorCode: type=Dcm_NegativeResponseCodeType, direction=OUT
      operation WriteData: possible-error=[DataServices_DidB095_Data_BMSOnChgEngy/E_NOT_OK, DataServices_DidB095_Data_BMSOnChgEngy/E_PENDING]
        arg Data: type=Dcm_DataBuffer2FixedType, direction=INOUT
        arg OpStatus: type=Dcm_OpStatusType, direction=IN
        arg ErrorCode: type=Dcm_NegativeResponseCodeType, direction=OUT
      error E_NOT_OK: error-code=1
      error E_PENDING: error-code=10
    DataServices_DidB096_Data_BMSReservedData1
      operation ReadData: possible-error=DataServices_DidB096_Data_BMSReservedData1/E_NOT_OK
        arg Data: type=Dcm_DataBuffer40FixedType, direction=OUT
      operation ConditionCheckRead: possible-error=[DataServices_DidB096_Data_BMSReservedData1/E_NOT_OK, DataServices_DidB096_Data_BMSReservedData1/E_PENDING]
        arg OpStatus: type=Dcm_OpStatusType, direction=IN
        arg ErrorCode: type=Dcm_NegativeResponseCodeType, direction=OUT
      error E_NOT_OK: error-code=1
      error E_PENDING: error-code=10
    DataServices_DidB097_Data_BMSReservedData2
      operation ReadData: possible-error=DataServices_DidB097_Data_BMSReservedData2/E_NOT_OK
        arg Data: type=Dcm_DataBuffer2FixedType, direction=OUT
      operation ConditionCheckRead: possible-error=[DataServices_DidB097_Data_BMSReservedData2/E_NOT_OK, DataServices_DidB097_Data_BMSReservedData2/E_PENDING]
        arg OpStatus: type=Dcm_OpStatusType, direction=IN
        arg ErrorCode: type=Dcm_NegativeResponseCodeType, direction=OUT
      error E_NOT_OK: error-code=1
      error E_PENDING: error-code=10
    DataServices_DidB098_Data_BMSReservedData3
      operation ReadData: possible-error=DataServices_DidB098_Data_BMSReservedData3/E_NOT_OK
        arg Data: type=Dcm_DataBuffer2FixedType, direction=OUT
      operation ConditionCheckRead: possible-error=[DataServices_DidB098_Data_BMSReservedData3/E_NOT_OK, DataServices_DidB098_Data_BMSReservedData3/E_PENDING]
        arg OpStatus: type=Dcm_OpStatusType, direction=IN
        arg ErrorCode: type=Dcm_NegativeResponseCodeType, direction=OUT
      error E_NOT_OK: error-code=1
      error E_PENDING: error-code=10
    DataServices_DidB099_Data_BMSReservedData4
      operation ReadData: possible-error=DataServices_DidB099_Data_BMSReservedData4/E_NOT_OK
        arg Data: type=Dcm_DataBuffer2FixedType, direction=OUT
      operation ConditionCheckRead: possible-error=[DataServices_DidB099_Data_BMSReservedData4/E_NOT_OK, DataServices_DidB099_Data_BMSReservedData4/E_PENDING]
        arg OpStatus: type=Dcm_OpStatusType, direction=IN
        arg ErrorCode: type=Dcm_NegativeResponseCodeType, direction=OUT
      error E_NOT_OK: error-code=1
      error E_PENDING: error-code=10
    DataServices_DidB09A_Data_BMSReservedData5
      operation ReadData: possible-error=DataServices_DidB09A_Data_BMSReservedData5/E_NOT_OK
        arg Data: type=Dcm_DataBuffer2FixedType, direction=OUT
      operation ConditionCheckRead: possible-error=[DataServices_DidB09A_Data_BMSReservedData5/E_NOT_OK, DataServices_DidB09A_Data_BMSReservedData5/E_PENDING]
        arg OpStatus: type=Dcm_OpStatusType, direction=IN
        arg ErrorCode: type=Dcm_NegativeResponseCodeType, direction=OUT
      error E_NOT_OK: error-code=1
      error E_PENDING: error-code=10
    DataServices_DidB09B_Data_BMSReservedData6
      operation ReadData: possible-error=DataServices_DidB09B_Data_BMSReservedData6/E_NOT_OK
        arg Data: type=Dcm_DataBuffer1FixedType, direction=OUT
      operation ConditionCheckRead: possible-error=[DataServices_DidB09B_Data_BMSReservedData6/E_NOT_OK, DataServices_DidB09B_Data_BMSReservedData6/E_PENDING]
        arg OpStatus: type=Dcm_OpStatusType, direction=IN
        arg ErrorCode: type=Dcm_NegativeResponseCodeType, direction=OUT
      error E_NOT_OK: error-code=1
      error E_PENDING: error-code=10
    DataServices_DidB09C_Data_BMSReservedData7
      operation ReadData: possible-error=DataServices_DidB09C_Data_BMSReservedData7/E_NOT_OK
        arg Data: type=Dcm_DataBuffer1FixedType, direction=OUT
      operation ConditionCheckRead: possible-error=[DataServices_DidB09C_Data_BMSReservedData7/E_NOT_OK, DataServices_DidB09C_Data_BMSReservedData7/E_PENDING]
        arg OpStatus: type=Dcm_OpStatusType, direction=IN
        arg ErrorCode: type=Dcm_NegativeResponseCodeType, direction=OUT
      error E_NOT_OK: error-code=1
      error E_PENDING: error-code=10
    DataServices_DidB09D_Data_BMSReservedData8
      operation ReadData: possible-error=DataServices_DidB09D_Data_BMSReservedData8/E_NOT_OK
        arg Data: type=Dcm_DataBuffer1FixedType, direction=OUT
      operation ConditionCheckRead: possible-error=[DataServices_DidB09D_Data_BMSReservedData8/E_NOT_OK, DataServices_DidB09D_Data_BMSReservedData8/E_PENDING]
        arg OpStatus: type=Dcm_OpStatusType, direction=IN
        arg ErrorCode: type=Dcm_NegativeResponseCodeType, direction=OUT
      error E_NOT_OK: error-code=1
      error E_PENDING: error-code=10
    DataServices_DidB09E_Data_BMSReservedData9
      operation ReadData: possible-error=DataServices_DidB09E_Data_BMSReservedData9/E_NOT_OK
        arg Data: type=Dcm_DataBuffer1FixedType, direction=OUT
      operation ConditionCheckRead: possible-error=[DataServices_DidB09E_Data_BMSReservedData9/E_NOT_OK, DataServices_DidB09E_Data_BMSReservedData9/E_PENDING]
        arg OpStatus: type=Dcm_OpStatusType, direction=IN
        arg ErrorCode: type=Dcm_NegativeResponseCodeType, direction=OUT
      error E_NOT_OK: error-code=1
      error E_PENDING: error-code=10
    DataServices_DidB09F_Data_BMSReservedData10
      operation ReadData: possible-error=DataServices_DidB09F_Data_BMSReservedData10/E_NOT_OK
        arg Data: type=Dcm_DataBuffer1FixedType, direction=OUT
      operation ConditionCheckRead: possible-error=[DataServices_DidB09F_Data_BMSReservedData10/E_NOT_OK, DataServices_DidB09F_Data_BMSReservedData10/E_PENDING]
        arg OpStatus: type=Dcm_OpStatusType, direction=IN
        arg ErrorCode: type=Dcm_NegativeResponseCodeType, direction=OUT
      error E_NOT_OK: error-code=1
      error E_PENDING: error-code=10
    DataServices_DidB0A0_Data_BMSOnChgAccumTime
      operation ReadData: possible-error=[DataServices_DidB0A0_Data_BMSOnChgAccumTime/E_NOT_OK, DataServices_DidB0A0_Data_BMSOnChgAccumTime/E_PENDING]
        arg OpStatus: type=Dcm_OpStatusType, direction=IN
        arg Data: type=Dcm_DataBuffer4FixedType, direction=OUT
      operation ConditionCheckRead: possible-error=[DataServices_DidB0A0_Data_BMSOnChgAccumTime/E_NOT_OK, DataServices_DidB0A0_Data_BMSOnChgAccumTime/E_PENDING]
        arg OpStatus: type=Dcm_OpStatusType, direction=IN
        arg ErrorCode: type=Dcm_NegativeResponseCodeType, direction=OUT
      operation WriteData: possible-error=[DataServices_DidB0A0_Data_BMSOnChgAccumTime/E_NOT_OK, DataServices_DidB0A0_Data_BMSOnChgAccumTime/E_PENDING]
        arg Data: type=Dcm_DataBuffer4FixedType, direction=INOUT
        arg OpStatus: type=Dcm_OpStatusType, direction=IN
        arg ErrorCode: type=Dcm_NegativeResponseCodeType, direction=OUT
      error E_NOT_OK: error-code=1
      error E_PENDING: error-code=10
    DataServices_DidB0A1_Data_BMSOnChgCnt
      operation ReadData: possible-error=[DataServices_DidB0A1_Data_BMSOnChgCnt/E_NOT_OK, DataServices_DidB0A1_Data_BMSOnChgCnt/E_PENDING]
        arg OpStatus: type=Dcm_OpStatusType, direction=IN
        arg Data: type=Dcm_DataBuffer2FixedType, direction=OUT
      operation ConditionCheckRead: possible-error=[DataServices_DidB0A1_Data_BMSOnChgCnt/E_NOT_OK, DataServices_DidB0A1_Data_BMSOnChgCnt/E_PENDING]
        arg OpStatus: type=Dcm_OpStatusType, direction=IN
        arg ErrorCode: type=Dcm_NegativeResponseCodeType, direction=OUT
      operation WriteData: possible-error=[DataServices_DidB0A1_Data_BMSOnChgCnt/E_NOT_OK, DataServices_DidB0A1_Data_BMSOnChgCnt/E_PENDING]
        arg Data: type=Dcm_DataBuffer2FixedType, direction=INOUT
        arg OpStatus: type=Dcm_OpStatusType, direction=IN
        arg ErrorCode: type=Dcm_NegativeResponseCodeType, direction=OUT
      error E_NOT_OK: error-code=1
      error E_PENDING: error-code=10
    DataServices_DidB0A2_Data_BMSSupConfigParam
      operation WriteData: possible-error=[DataServices_DidB0A2_Data_BMSSupConfigParam/E_NOT_OK, DataServices_DidB0A2_Data_BMSSupConfigParam/E_PENDING]
        arg Data: type=Dcm_DataBuffer2FixedType, direction=INOUT
        arg OpStatus: type=Dcm_OpStatusType, direction=IN
        arg ErrorCode: type=Dcm_NegativeResponseCodeType, direction=OUT
      error E_NOT_OK: error-code=1
      error E_PENDING: error-code=10
    DataServices_DidB0BD_Data_VehicleSpeed
      operation ReadData: possible-error=DataServices_DidB0BD_Data_VehicleSpeed/E_NOT_OK
        arg Data: type=Dcm_DataBuffer1FixedType, direction=OUT
      operation ConditionCheckRead: possible-error=[DataServices_DidB0BD_Data_VehicleSpeed/E_NOT_OK, DataServices_DidB0BD_Data_VehicleSpeed/E_PENDING]
        arg OpStatus: type=Dcm_OpStatusType, direction=IN
        arg ErrorCode: type=Dcm_NegativeResponseCodeType, direction=OUT
      error E_NOT_OK: error-code=1
      error E_PENDING: error-code=10
    DataServices_DidD001_Data_PowerMode
      operation ReadData: possible-error=DataServices_DidD001_Data_PowerMode/E_NOT_OK
        arg Data: type=Dcm_DataBuffer1FixedType, direction=OUT
      operation ConditionCheckRead: possible-error=[DataServices_DidD001_Data_PowerMode/E_NOT_OK, DataServices_DidD001_Data_PowerMode/E_PENDING]
        arg OpStatus: type=Dcm_OpStatusType, direction=IN
        arg ErrorCode: type=Dcm_NegativeResponseCodeType, direction=OUT
      error E_NOT_OK: error-code=1
      error E_PENDING: error-code=10
    DataServices_DidE000_Data_CoolingPump
      6 x operation:
        ReadData: possible-error=DataServices_DidE000_Data_CoolingPump/E_NOT_OK
          arg Data: type=Dcm_DataBuffer1FixedType, direction=OUT
        ConditionCheckRead: possible-error=[DataServices_DidE000_Data_CoolingPump/E_NOT_OK, DataServices_DidE000_Data_CoolingPump/E_PENDING]
          arg OpStatus: type=Dcm_OpStatusType, direction=IN
          arg ErrorCode: type=Dcm_NegativeResponseCodeType, direction=OUT
        FreezeCurrentState: possible-error=[DataServices_DidE000_Data_CoolingPump/E_NOT_OK, DataServices_DidE000_Data_CoolingPump/E_PENDING]
          arg OpStatus: type=Dcm_OpStatusType, direction=IN
          arg ErrorCode: type=Dcm_NegativeResponseCodeType, direction=OUT
        ResetToDefault: possible-error=[DataServices_DidE000_Data_CoolingPump/E_NOT_OK, DataServices_DidE000_Data_CoolingPump/E_PENDING]
          arg OpStatus: type=Dcm_OpStatusType, direction=IN
          arg ErrorCode: type=Dcm_NegativeResponseCodeType, direction=OUT
        ReturnControlToECU: possible-error=[DataServices_DidE000_Data_CoolingPump/E_NOT_OK, DataServices_DidE000_Data_CoolingPump/E_PENDING]
          arg OpStatus: type=Dcm_OpStatusType, direction=IN
          arg ErrorCode: type=Dcm_NegativeResponseCodeType, direction=OUT
        ShortTermAdjustment: possible-error=[DataServices_DidE000_Data_CoolingPump/E_NOT_OK, DataServices_DidE000_Data_CoolingPump/E_PENDING]
          arg ControlOptionRecord: type=Dcm_DataBuffer1FixedType, direction=INOUT
          arg OpStatus: type=Dcm_OpStatusType, direction=IN
          arg ErrorCode: type=Dcm_NegativeResponseCodeType, direction=OUT
      error E_NOT_OK: error-code=1
      error E_PENDING: error-code=10
    DataServices_DidE001_Data_ChgIndDriver
      6 x operation:
        ReadData: possible-error=DataServices_DidE001_Data_ChgIndDriver/E_NOT_OK
          arg Data: type=Dcm_DataBuffer1FixedType, direction=OUT
        ConditionCheckRead: possible-error=[DataServices_DidE001_Data_ChgIndDriver/E_NOT_OK, DataServices_DidE001_Data_ChgIndDriver/E_PENDING]
          arg OpStatus: type=Dcm_OpStatusType, direction=IN
          arg ErrorCode: type=Dcm_NegativeResponseCodeType, direction=OUT
        FreezeCurrentState: possible-error=[DataServices_DidE001_Data_ChgIndDriver/E_NOT_OK, DataServices_DidE001_Data_ChgIndDriver/E_PENDING]
          arg OpStatus: type=Dcm_OpStatusType, direction=IN
          arg ErrorCode: type=Dcm_NegativeResponseCodeType, direction=OUT
        ResetToDefault: possible-error=[DataServices_DidE001_Data_ChgIndDriver/E_NOT_OK, DataServices_DidE001_Data_ChgIndDriver/E_PENDING]
          arg OpStatus: type=Dcm_OpStatusType, direction=IN
          arg ErrorCode: type=Dcm_NegativeResponseCodeType, direction=OUT
        ReturnControlToECU: possible-error=[DataServices_DidE001_Data_ChgIndDriver/E_NOT_OK, DataServices_DidE001_Data_ChgIndDriver/E_PENDING]
          arg OpStatus: type=Dcm_OpStatusType, direction=IN
          arg ErrorCode: type=Dcm_NegativeResponseCodeType, direction=OUT
        ShortTermAdjustment: possible-error=[DataServices_DidE001_Data_ChgIndDriver/E_NOT_OK, DataServices_DidE001_Data_ChgIndDriver/E_PENDING]
          arg ControlOptionRecord: type=Dcm_DataBuffer1FixedType, direction=INOUT
          arg OpStatus: type=Dcm_OpStatusType, direction=IN
          arg ErrorCode: type=Dcm_NegativeResponseCodeType, direction=OUT
      error E_NOT_OK: error-code=1
      error E_PENDING: error-code=10
    DataServices_DidE002_Data_ConnIndDriver
      6 x operation:
        ReadData: possible-error=DataServices_DidE002_Data_ConnIndDriver/E_NOT_OK
          arg Data: type=Dcm_DataBuffer1FixedType, direction=OUT
        ConditionCheckRead: possible-error=[DataServices_DidE002_Data_ConnIndDriver/E_NOT_OK, DataServices_DidE002_Data_ConnIndDriver/E_PENDING]
          arg OpStatus: type=Dcm_OpStatusType, direction=IN
          arg ErrorCode: type=Dcm_NegativeResponseCodeType, direction=OUT
        FreezeCurrentState: possible-error=[DataServices_DidE002_Data_ConnIndDriver/E_NOT_OK, DataServices_DidE002_Data_ConnIndDriver/E_PENDING]
          arg OpStatus: type=Dcm_OpStatusType, direction=IN
          arg ErrorCode: type=Dcm_NegativeResponseCodeType, direction=OUT
        ResetToDefault: possible-error=[DataServices_DidE002_Data_ConnIndDriver/E_NOT_OK, DataServices_DidE002_Data_ConnIndDriver/E_PENDING]
          arg OpStatus: type=Dcm_OpStatusType, direction=IN
          arg ErrorCode: type=Dcm_NegativeResponseCodeType, direction=OUT
        ReturnControlToECU: possible-error=[DataServices_DidE002_Data_ConnIndDriver/E_NOT_OK, DataServices_DidE002_Data_ConnIndDriver/E_PENDING]
          arg OpStatus: type=Dcm_OpStatusType, direction=IN
          arg ErrorCode: type=Dcm_NegativeResponseCodeType, direction=OUT
        ShortTermAdjustment: possible-error=[DataServices_DidE002_Data_ConnIndDriver/E_NOT_OK, DataServices_DidE002_Data_ConnIndDriver/E_PENDING]
          arg ControlOptionRecord: type=Dcm_DataBuffer1FixedType, direction=INOUT
          arg OpStatus: type=Dcm_OpStatusType, direction=IN
          arg ErrorCode: type=Dcm_NegativeResponseCodeType, direction=OUT
      error E_NOT_OK: error-code=1
      error E_PENDING: error-code=10
    DataServices_DidE003_Data_LeakDetectEn
      6 x operation:
        ReadData: possible-error=DataServices_DidE003_Data_LeakDetectEn/E_NOT_OK
          arg Data: type=Dcm_DataBuffer1FixedType, direction=OUT
        ConditionCheckRead: possible-error=[DataServices_DidE003_Data_LeakDetectEn/E_NOT_OK, DataServices_DidE003_Data_LeakDetectEn/E_PENDING]
          arg OpStatus: type=Dcm_OpStatusType, direction=IN
          arg ErrorCode: type=Dcm_NegativeResponseCodeType, direction=OUT
        FreezeCurrentState: possible-error=[DataServices_DidE003_Data_LeakDetectEn/E_NOT_OK, DataServices_DidE003_Data_LeakDetectEn/E_PENDING]
          arg OpStatus: type=Dcm_OpStatusType, direction=IN
          arg ErrorCode: type=Dcm_NegativeResponseCodeType, direction=OUT
        ResetToDefault: possible-error=[DataServices_DidE003_Data_LeakDetectEn/E_NOT_OK, DataServices_DidE003_Data_LeakDetectEn/E_PENDING]
          arg OpStatus: type=Dcm_OpStatusType, direction=IN
          arg ErrorCode: type=Dcm_NegativeResponseCodeType, direction=OUT
        ReturnControlToECU: possible-error=[DataServices_DidE003_Data_LeakDetectEn/E_NOT_OK, DataServices_DidE003_Data_LeakDetectEn/E_PENDING]
          arg OpStatus: type=Dcm_OpStatusType, direction=IN
          arg ErrorCode: type=Dcm_NegativeResponseCodeType, direction=OUT
        ShortTermAdjustment: possible-error=[DataServices_DidE003_Data_LeakDetectEn/E_NOT_OK, DataServices_DidE003_Data_LeakDetectEn/E_PENDING]
          arg ControlOptionRecord: type=Dcm_DataBuffer1FixedType, direction=INOUT
          arg OpStatus: type=Dcm_OpStatusType, direction=IN
          arg ErrorCode: type=Dcm_NegativeResponseCodeType, direction=OUT
      error E_NOT_OK: error-code=1
      error E_PENDING: error-code=10
    DataServices_DidE004_Data_BthIndDriver
      6 x operation:
        ReadData: possible-error=DataServices_DidE004_Data_BthIndDriver/E_NOT_OK
          arg Data: type=Dcm_DataBuffer1FixedType, direction=OUT
        ConditionCheckRead: possible-error=[DataServices_DidE004_Data_BthIndDriver/E_NOT_OK, DataServices_DidE004_Data_BthIndDriver/E_PENDING]
          arg OpStatus: type=Dcm_OpStatusType, direction=IN
          arg ErrorCode: type=Dcm_NegativeResponseCodeType, direction=OUT
        FreezeCurrentState: possible-error=[DataServices_DidE004_Data_BthIndDriver/E_NOT_OK, DataServices_DidE004_Data_BthIndDriver/E_PENDING]
          arg OpStatus: type=Dcm_OpStatusType, direction=IN
          arg ErrorCode: type=Dcm_NegativeResponseCodeType, direction=OUT
        ResetToDefault: possible-error=[DataServices_DidE004_Data_BthIndDriver/E_NOT_OK, DataServices_DidE004_Data_BthIndDriver/E_PENDING]
          arg OpStatus: type=Dcm_OpStatusType, direction=IN
          arg ErrorCode: type=Dcm_NegativeResponseCodeType, direction=OUT
        ReturnControlToECU: possible-error=[DataServices_DidE004_Data_BthIndDriver/E_NOT_OK, DataServices_DidE004_Data_BthIndDriver/E_PENDING]
          arg OpStatus: type=Dcm_OpStatusType, direction=IN
          arg ErrorCode: type=Dcm_NegativeResponseCodeType, direction=OUT
        ShortTermAdjustment: possible-error=[DataServices_DidE004_Data_BthIndDriver/E_NOT_OK, DataServices_DidE004_Data_BthIndDriver/E_PENDING]
          arg ControlOptionRecord: type=Dcm_DataBuffer1FixedType, direction=INOUT
          arg OpStatus: type=Dcm_OpStatusType, direction=IN
          arg ErrorCode: type=Dcm_NegativeResponseCodeType, direction=OUT
      error E_NOT_OK: error-code=1
      error E_PENDING: error-code=10
    DataServices_DidE101_Data_Odometer
      operation ReadData: possible-error=DataServices_DidE101_Data_Odometer/E_NOT_OK
        arg Data: type=Dcm_DataBuffer3FixedType, direction=OUT
      operation ConditionCheckRead: possible-error=[DataServices_DidE101_Data_Odometer/E_NOT_OK, DataServices_DidE101_Data_Odometer/E_PENDING]
        arg OpStatus: type=Dcm_OpStatusType, direction=IN
        arg ErrorCode: type=Dcm_NegativeResponseCodeType, direction=OUT
      error E_NOT_OK: error-code=1
      error E_PENDING: error-code=10
    DataServices_DidF100_Data_SVIF
      operation ReadData: possible-error=DataServices_DidF100_Data_SVIF/E_NOT_OK
        arg Data: type=Dcm_DataBuffer6FixedType, direction=OUT
      operation ConditionCheckRead: possible-error=[DataServices_DidF100_Data_SVIF/E_NOT_OK, DataServices_DidF100_Data_SVIF/E_PENDING]
        arg OpStatus: type=Dcm_OpStatusType, direction=IN
        arg ErrorCode: type=Dcm_NegativeResponseCodeType, direction=OUT
      error E_NOT_OK: error-code=1
      error E_PENDING: error-code=10
    DataServices_DidF110_Data_PIFptr
      operation ReadData: possible-error=DataServices_DidF110_Data_PIFptr/E_NOT_OK
        arg Data: type=Dcm_DataBuffer16FixedType, direction=OUT
      operation ConditionCheckRead: possible-error=[DataServices_DidF110_Data_PIFptr/E_NOT_OK, DataServices_DidF110_Data_PIFptr/E_PENDING]
        arg OpStatus: type=Dcm_OpStatusType, direction=IN
        arg ErrorCode: type=Dcm_NegativeResponseCodeType, direction=OUT
      error E_NOT_OK: error-code=1
      error E_PENDING: error-code=10
    DataServices_DidF111_Data_PIF1
      operation ReadData: possible-error=DataServices_DidF111_Data_PIF1/E_NOT_OK
        arg Data: type=Dcm_DataBuffer16FixedType, direction=OUT
      operation ConditionCheckRead: possible-error=[DataServices_DidF111_Data_PIF1/E_NOT_OK, DataServices_DidF111_Data_PIF1/E_PENDING]
        arg OpStatus: type=Dcm_OpStatusType, direction=IN
        arg ErrorCode: type=Dcm_NegativeResponseCodeType, direction=OUT
      error E_NOT_OK: error-code=1
      error E_PENDING: error-code=10
    DataServices_DidF112_Data_PIF2
      operation ReadData: possible-error=DataServices_DidF112_Data_PIF2/E_NOT_OK
        arg Data: type=Dcm_DataBuffer16FixedType, direction=OUT
      operation ConditionCheckRead: possible-error=[DataServices_DidF112_Data_PIF2/E_NOT_OK, DataServices_DidF112_Data_PIF2/E_PENDING]
        arg OpStatus: type=Dcm_OpStatusType, direction=IN
        arg ErrorCode: type=Dcm_NegativeResponseCodeType, direction=OUT
      error E_NOT_OK: error-code=1
      error E_PENDING: error-code=10
    DataServices_DidF113_Data_PIF3
      operation ReadData: possible-error=DataServices_DidF113_Data_PIF3/E_NOT_OK
        arg Data: type=Dcm_DataBuffer16FixedType, direction=OUT
      operation ConditionCheckRead: possible-error=[DataServices_DidF113_Data_PIF3/E_NOT_OK, DataServices_DidF113_Data_PIF3/E_PENDING]
        arg OpStatus: type=Dcm_OpStatusType, direction=IN
        arg ErrorCode: type=Dcm_NegativeResponseCodeType, direction=OUT
      error E_NOT_OK: error-code=1
      error E_PENDING: error-code=10
    DataServices_DidF114_Data_PIF4
      operation ReadData: possible-error=DataServices_DidF114_Data_PIF4/E_NOT_OK
        arg Data: type=Dcm_DataBuffer16FixedType, direction=OUT
      operation ConditionCheckRead: possible-error=[DataServices_DidF114_Data_PIF4/E_NOT_OK, DataServices_DidF114_Data_PIF4/E_PENDING]
        arg OpStatus: type=Dcm_OpStatusType, direction=IN
        arg ErrorCode: type=Dcm_NegativeResponseCodeType, direction=OUT
      error E_NOT_OK: error-code=1
      error E_PENDING: error-code=10
    DataServices_DidF115_Data_PIF5
      operation ReadData: possible-error=DataServices_DidF115_Data_PIF5/E_NOT_OK
        arg Data: type=Dcm_DataBuffer16FixedType, direction=OUT
      operation ConditionCheckRead: possible-error=[DataServices_DidF115_Data_PIF5/E_NOT_OK, DataServices_DidF115_Data_PIF5/E_PENDING]
        arg OpStatus: type=Dcm_OpStatusType, direction=IN
        arg ErrorCode: type=Dcm_NegativeResponseCodeType, direction=OUT
      error E_NOT_OK: error-code=1
      error E_PENDING: error-code=10
    DataServices_DidF116_Data_PIF6
      operation ReadData: possible-error=DataServices_DidF116_Data_PIF6/E_NOT_OK
        arg Data: type=Dcm_DataBuffer16FixedType, direction=OUT
      operation ConditionCheckRead: possible-error=[DataServices_DidF116_Data_PIF6/E_NOT_OK, DataServices_DidF116_Data_PIF6/E_PENDING]
        arg OpStatus: type=Dcm_OpStatusType, direction=IN
        arg ErrorCode: type=Dcm_NegativeResponseCodeType, direction=OUT
      error E_NOT_OK: error-code=1
      error E_PENDING: error-code=10
    DataServices_DidF117_Data_PIF7
      operation ReadData: possible-error=DataServices_DidF117_Data_PIF7/E_NOT_OK
        arg Data: type=Dcm_DataBuffer16FixedType, direction=OUT
      operation ConditionCheckRead: possible-error=[DataServices_DidF117_Data_PIF7/E_NOT_OK, DataServices_DidF117_Data_PIF7/E_PENDING]
        arg OpStatus: type=Dcm_OpStatusType, direction=IN
        arg ErrorCode: type=Dcm_NegativeResponseCodeType, direction=OUT
      error E_NOT_OK: error-code=1
      error E_PENDING: error-code=10
    DataServices_DidF118_Data_PIF8
      operation ReadData: possible-error=DataServices_DidF118_Data_PIF8/E_NOT_OK
        arg Data: type=Dcm_DataBuffer16FixedType, direction=OUT
      operation ConditionCheckRead: possible-error=[DataServices_DidF118_Data_PIF8/E_NOT_OK, DataServices_DidF118_Data_PIF8/E_PENDING]
        arg OpStatus: type=Dcm_OpStatusType, direction=IN
        arg ErrorCode: type=Dcm_NegativeResponseCodeType, direction=OUT
      error E_NOT_OK: error-code=1
      error E_PENDING: error-code=10
    DataServices_DidF119_Data_PIF9
      operation ReadData: possible-error=DataServices_DidF119_Data_PIF9/E_NOT_OK
        arg Data: type=Dcm_DataBuffer16FixedType, direction=OUT
      operation ConditionCheckRead: possible-error=[DataServices_DidF119_Data_PIF9/E_NOT_OK, DataServices_DidF119_Data_PIF9/E_PENDING]
        arg OpStatus: type=Dcm_OpStatusType, direction=IN
        arg ErrorCode: type=Dcm_NegativeResponseCodeType, direction=OUT
      error E_NOT_OK: error-code=1
      error E_PENDING: error-code=10
    DataServices_DidF11A_Data_PIFA
      operation ReadData: possible-error=DataServices_DidF11A_Data_PIFA/E_NOT_OK
        arg Data: type=Dcm_DataBuffer16FixedType, direction=OUT
      operation ConditionCheckRead: possible-error=[DataServices_DidF11A_Data_PIFA/E_NOT_OK, DataServices_DidF11A_Data_PIFA/E_PENDING]
        arg OpStatus: type=Dcm_OpStatusType, direction=IN
        arg ErrorCode: type=Dcm_NegativeResponseCodeType, direction=OUT
      error E_NOT_OK: error-code=1
      error E_PENDING: error-code=10
    DataServices_DidF11B_Data_PIFB
      operation ReadData: possible-error=DataServices_DidF11B_Data_PIFB/E_NOT_OK
        arg Data: type=Dcm_DataBuffer16FixedType, direction=OUT
      operation ConditionCheckRead: possible-error=[DataServices_DidF11B_Data_PIFB/E_NOT_OK, DataServices_DidF11B_Data_PIFB/E_PENDING]
        arg OpStatus: type=Dcm_OpStatusType, direction=IN
        arg ErrorCode: type=Dcm_NegativeResponseCodeType, direction=OUT
      error E_NOT_OK: error-code=1
      error E_PENDING: error-code=10
    DataServices_DidF11C_Data_PIFC
      operation ReadData: possible-error=DataServices_DidF11C_Data_PIFC/E_NOT_OK
        arg Data: type=Dcm_DataBuffer16FixedType, direction=OUT
      operation ConditionCheckRead: possible-error=[DataServices_DidF11C_Data_PIFC/E_NOT_OK, DataServices_DidF11C_Data_PIFC/E_PENDING]
        arg OpStatus: type=Dcm_OpStatusType, direction=IN
        arg ErrorCode: type=Dcm_NegativeResponseCodeType, direction=OUT
      error E_NOT_OK: error-code=1
      error E_PENDING: error-code=10
    DataServices_DidF11D_Data_PIFD
      operation ReadData: possible-error=DataServices_DidF11D_Data_PIFD/E_NOT_OK
        arg Data: type=Dcm_DataBuffer16FixedType, direction=OUT
      operation ConditionCheckRead: possible-error=[DataServices_DidF11D_Data_PIFD/E_NOT_OK, DataServices_DidF11D_Data_PIFD/E_PENDING]
        arg OpStatus: type=Dcm_OpStatusType, direction=IN
        arg ErrorCode: type=Dcm_NegativeResponseCodeType, direction=OUT
      error E_NOT_OK: error-code=1
      error E_PENDING: error-code=10
    DataServices_DidF11E_Data_PIFE
      operation ReadData: possible-error=DataServices_DidF11E_Data_PIFE/E_NOT_OK
        arg Data: type=Dcm_DataBuffer16FixedType, direction=OUT
      operation ConditionCheckRead: possible-error=[DataServices_DidF11E_Data_PIFE/E_NOT_OK, DataServices_DidF11E_Data_PIFE/E_PENDING]
        arg OpStatus: type=Dcm_OpStatusType, direction=IN
        arg ErrorCode: type=Dcm_NegativeResponseCodeType, direction=OUT
      error E_NOT_OK: error-code=1
      error E_PENDING: error-code=10
    DataServices_DidF11F_Data_PIFF
      operation ReadData: possible-error=DataServices_DidF11F_Data_PIFF/E_NOT_OK
        arg Data: type=Dcm_DataBuffer16FixedType, direction=OUT
      operation ConditionCheckRead: possible-error=[DataServices_DidF11F_Data_PIFF/E_NOT_OK, DataServices_DidF11F_Data_PIFF/E_PENDING]
        arg OpStatus: type=Dcm_OpStatusType, direction=IN
        arg ErrorCode: type=Dcm_NegativeResponseCodeType, direction=OUT
      error E_NOT_OK: error-code=1
      error E_PENDING: error-code=10
    DataServices_DidF120_Data_NIFfactory
      operation ReadData: possible-error=DataServices_DidF120_Data_NIFfactory/E_NOT_OK
        arg Data: type=Dcm_DataBuffer16FixedType, direction=OUT
      operation ConditionCheckRead: possible-error=[DataServices_DidF120_Data_NIFfactory/E_NOT_OK, DataServices_DidF120_Data_NIFfactory/E_PENDING]
        arg OpStatus: type=Dcm_OpStatusType, direction=IN
        arg ErrorCode: type=Dcm_NegativeResponseCodeType, direction=OUT
      error E_NOT_OK: error-code=1
      error E_PENDING: error-code=10
    DataServices_DidF121_Data_NIFcur
      operation ReadData: possible-error=DataServices_DidF121_Data_NIFcur/E_NOT_OK
        arg Data: type=Dcm_DataBuffer16FixedType, direction=OUT
      operation ConditionCheckRead: possible-error=[DataServices_DidF121_Data_NIFcur/E_NOT_OK, DataServices_DidF121_Data_NIFcur/E_PENDING]
        arg OpStatus: type=Dcm_OpStatusType, direction=IN
        arg ErrorCode: type=Dcm_NegativeResponseCodeType, direction=OUT
      error E_NOT_OK: error-code=1
      error E_PENDING: error-code=10
    DataServices_DidF183_Data_BootloaderSRN
      operation ReadData: possible-error=DataServices_DidF183_Data_BootloaderSRN/E_NOT_OK
        arg Data: type=Dcm_DataBuffer10FixedType, direction=OUT
      operation ConditionCheckRead: possible-error=[DataServices_DidF183_Data_BootloaderSRN/E_NOT_OK, DataServices_DidF183_Data_BootloaderSRN/E_PENDING]
        arg OpStatus: type=Dcm_OpStatusType, direction=IN
        arg ErrorCode: type=Dcm_NegativeResponseCodeType, direction=OUT
      error E_NOT_OK: error-code=1
      error E_PENDING: error-code=10
    DataServices_DidF187_Data_ECUPN
      operation ReadData: possible-error=DataServices_DidF187_Data_ECUPN/E_NOT_OK
        arg Data: type=Dcm_DataBuffer5FixedType, direction=OUT
      operation ConditionCheckRead: possible-error=[DataServices_DidF187_Data_ECUPN/E_NOT_OK, DataServices_DidF187_Data_ECUPN/E_PENDING]
        arg OpStatus: type=Dcm_OpStatusType, direction=IN
        arg ErrorCode: type=Dcm_NegativeResponseCodeType, direction=OUT
      error E_NOT_OK: error-code=1
      error E_PENDING: error-code=10
    DataServices_DidF18A_Data_SupID
      operation ReadData: possible-error=DataServices_DidF18A_Data_SupID/E_NOT_OK
        arg Data: type=Dcm_DataBuffer5FixedType, direction=OUT
      operation ConditionCheckRead: possible-error=[DataServices_DidF18A_Data_SupID/E_NOT_OK, DataServices_DidF18A_Data_SupID/E_PENDING]
        arg OpStatus: type=Dcm_OpStatusType, direction=IN
        arg ErrorCode: type=Dcm_NegativeResponseCodeType, direction=OUT
      error E_NOT_OK: error-code=1
      error E_PENDING: error-code=10
    DataServices_DidF18B_Data_ECUDate
      operation ReadData: possible-error=[DataServices_DidF18B_Data_ECUDate/E_NOT_OK, DataServices_DidF18B_Data_ECUDate/E_PENDING]
        arg OpStatus: type=Dcm_OpStatusType, direction=IN
        arg Data: type=Dcm_DataBuffer3FixedType, direction=OUT
      operation ConditionCheckRead: possible-error=[DataServices_DidF18B_Data_ECUDate/E_NOT_OK, DataServices_DidF18B_Data_ECUDate/E_PENDING]
        arg OpStatus: type=Dcm_OpStatusType, direction=IN
        arg ErrorCode: type=Dcm_NegativeResponseCodeType, direction=OUT
      operation WriteData: possible-error=[DataServices_DidF18B_Data_ECUDate/E_NOT_OK, DataServices_DidF18B_Data_ECUDate/E_PENDING]
        arg Data: type=Dcm_DataBuffer3FixedType, direction=INOUT
        arg OpStatus: type=Dcm_OpStatusType, direction=IN
        arg ErrorCode: type=Dcm_NegativeResponseCodeType, direction=OUT
      error E_NOT_OK: error-code=1
      error E_PENDING: error-code=10
    DataServices_DidF18C_Data_ECUSN
      operation ReadData: possible-error=[DataServices_DidF18C_Data_ECUSN/E_NOT_OK, DataServices_DidF18C_Data_ECUSN/E_PENDING]
        arg OpStatus: type=Dcm_OpStatusType, direction=IN
        arg Data: type=Dcm_DataBuffer16FixedType, direction=OUT
      operation ConditionCheckRead: possible-error=[DataServices_DidF18C_Data_ECUSN/E_NOT_OK, DataServices_DidF18C_Data_ECUSN/E_PENDING]
        arg OpStatus: type=Dcm_OpStatusType, direction=IN
        arg ErrorCode: type=Dcm_NegativeResponseCodeType, direction=OUT
      operation WriteData: possible-error=[DataServices_DidF18C_Data_ECUSN/E_NOT_OK, DataServices_DidF18C_Data_ECUSN/E_PENDING]
        arg Data: type=Dcm_DataBuffer16FixedType, direction=INOUT
        arg OpStatus: type=Dcm_OpStatusType, direction=IN
        arg ErrorCode: type=Dcm_NegativeResponseCodeType, direction=OUT
      error E_NOT_OK: error-code=1
      error E_PENDING: error-code=10
    DataServices_DidF190_Data_VIN
      operation ReadData: possible-error=[DataServices_DidF190_Data_VIN/E_NOT_OK, DataServices_DidF190_Data_VIN/E_PENDING]
        arg OpStatus: type=Dcm_OpStatusType, direction=IN
        arg Data: type=Dcm_DataBuffer17FixedType, direction=OUT
      operation ConditionCheckRead: possible-error=[DataServices_DidF190_Data_VIN/E_NOT_OK, DataServices_DidF190_Data_VIN/E_PENDING]
        arg OpStatus: type=Dcm_OpStatusType, direction=IN
        arg ErrorCode: type=Dcm_NegativeResponseCodeType, direction=OUT
      operation WriteData: possible-error=[DataServices_DidF190_Data_VIN/E_NOT_OK, DataServices_DidF190_Data_VIN/E_PENDING]
        arg Data: type=Dcm_DataBuffer17FixedType, direction=INOUT
        arg OpStatus: type=Dcm_OpStatusType, direction=IN
        arg ErrorCode: type=Dcm_NegativeResponseCodeType, direction=OUT
      error E_NOT_OK: error-code=1
      error E_PENDING: error-code=10
    DataServices_DidF191_Data_ECUHWNo
      operation ReadData: possible-error=DataServices_DidF191_Data_ECUHWNo/E_NOT_OK
        arg Data: type=Dcm_DataBuffer5FixedType, direction=OUT
      operation ConditionCheckRead: possible-error=[DataServices_DidF191_Data_ECUHWNo/E_NOT_OK, DataServices_DidF191_Data_ECUHWNo/E_PENDING]
        arg OpStatus: type=Dcm_OpStatusType, direction=IN
        arg ErrorCode: type=Dcm_NegativeResponseCodeType, direction=OUT
      error E_NOT_OK: error-code=1
      error E_PENDING: error-code=10
    DataServices_DidF192_Data_SupHWRN
      operation ReadData: possible-error=DataServices_DidF192_Data_SupHWRN/E_NOT_OK
        arg Data: type=Dcm_DataBuffer10FixedType, direction=OUT
      operation ConditionCheckRead: possible-error=[DataServices_DidF192_Data_SupHWRN/E_NOT_OK, DataServices_DidF192_Data_SupHWRN/E_PENDING]
        arg OpStatus: type=Dcm_OpStatusType, direction=IN
        arg ErrorCode: type=Dcm_NegativeResponseCodeType, direction=OUT
      error E_NOT_OK: error-code=1
      error E_PENDING: error-code=10
    DataServices_DidF194_Data_SupSWRN
      operation ReadData: possible-error=DataServices_DidF194_Data_SupSWRN/E_NOT_OK
        arg Data: type=Dcm_DataBuffer10FixedType, direction=OUT
      operation ConditionCheckRead: possible-error=[DataServices_DidF194_Data_SupSWRN/E_NOT_OK, DataServices_DidF194_Data_SupSWRN/E_PENDING]
        arg OpStatus: type=Dcm_OpStatusType, direction=IN
        arg ErrorCode: type=Dcm_NegativeResponseCodeType, direction=OUT
      error E_NOT_OK: error-code=1
      error E_PENDING: error-code=10
    DataServices_DidF198_Data_ConfigTF
      operation ReadData: possible-error=[DataServices_DidF198_Data_ConfigTF/E_NOT_OK, DataServices_DidF198_Data_ConfigTF/E_PENDING]
        arg OpStatus: type=Dcm_OpStatusType, direction=IN
        arg Data: type=Dcm_DataBuffer11FixedType, direction=OUT
      operation ConditionCheckRead: possible-error=[DataServices_DidF198_Data_ConfigTF/E_NOT_OK, DataServices_DidF198_Data_ConfigTF/E_PENDING]
        arg OpStatus: type=Dcm_OpStatusType, direction=IN
        arg ErrorCode: type=Dcm_NegativeResponseCodeType, direction=OUT
      operation WriteData: possible-error=[DataServices_DidF198_Data_ConfigTF/E_NOT_OK, DataServices_DidF198_Data_ConfigTF/E_PENDING]
        arg Data: type=Dcm_DataBuffer11FixedType, direction=INOUT
        arg OpStatus: type=Dcm_OpStatusType, direction=IN
        arg ErrorCode: type=Dcm_NegativeResponseCodeType, direction=OUT
      error E_NOT_OK: error-code=1
      error E_PENDING: error-code=10
    DataServices_DidF1A0_Data_AppSWNo
      operation ReadData: possible-error=DataServices_DidF1A0_Data_AppSWNo/E_NOT_OK
        arg Data: type=Dcm_DataBuffer5FixedType, direction=OUT
      operation ConditionCheckRead: possible-error=[DataServices_DidF1A0_Data_AppSWNo/E_NOT_OK, DataServices_DidF1A0_Data_AppSWNo/E_PENDING]
        arg OpStatus: type=Dcm_OpStatusType, direction=IN
        arg ErrorCode: type=Dcm_NegativeResponseCodeType, direction=OUT
      error E_NOT_OK: error-code=1
      error E_PENDING: error-code=10
    DataServices_DidF1A1_Data_CalSWNo
      operation ReadData: possible-error=DataServices_DidF1A1_Data_CalSWNo/E_NOT_OK
        arg Data: type=Dcm_DataBuffer5FixedType, direction=OUT
      operation ConditionCheckRead: possible-error=[DataServices_DidF1A1_Data_CalSWNo/E_NOT_OK, DataServices_DidF1A1_Data_CalSWNo/E_PENDING]
        arg OpStatus: type=Dcm_OpStatusType, direction=IN
        arg ErrorCode: type=Dcm_NegativeResponseCodeType, direction=OUT
      error E_NOT_OK: error-code=1
      error E_PENDING: error-code=10
    DataServices_DidF1A2_Data_NCFRN
      operation ReadData: possible-error=DataServices_DidF1A2_Data_NCFRN/E_NOT_OK
        arg Data: type=Dcm_DataBuffer8FixedType, direction=OUT
      operation ConditionCheckRead: possible-error=[DataServices_DidF1A2_Data_NCFRN/E_NOT_OK, DataServices_DidF1A2_Data_NCFRN/E_PENDING]
        arg OpStatus: type=Dcm_OpStatusType, direction=IN
        arg ErrorCode: type=Dcm_NegativeResponseCodeType, direction=OUT
      error E_NOT_OK: error-code=1
      error E_PENDING: error-code=10
    DataServices_DidF1A5_Data_ECUIndex
      operation ReadData: possible-error=DataServices_DidF1A5_Data_ECUIndex/E_NOT_OK
        arg Data: type=Dcm_DataBuffer3FixedType, direction=OUT
      operation ConditionCheckRead: possible-error=[DataServices_DidF1A5_Data_ECUIndex/E_NOT_OK, DataServices_DidF1A5_Data_ECUIndex/E_PENDING]
        arg OpStatus: type=Dcm_OpStatusType, direction=IN
        arg ErrorCode: type=Dcm_NegativeResponseCodeType, direction=OUT
      error E_NOT_OK: error-code=1
      error E_PENDING: error-code=10
    DataServices_DidF1A8_Data_VehFeature
      operation ReadData: possible-error=[DataServices_DidF1A8_Data_VehFeature/E_NOT_OK, DataServices_DidF1A8_Data_VehFeature/E_PENDING]
        arg OpStatus: type=Dcm_OpStatusType, direction=IN
        arg Data: type=Dcm_DataBuffer20FixedType, direction=OUT
      operation ConditionCheckRead: possible-error=[DataServices_DidF1A8_Data_VehFeature/E_NOT_OK, DataServices_DidF1A8_Data_VehFeature/E_PENDING]
        arg OpStatus: type=Dcm_OpStatusType, direction=IN
        arg ErrorCode: type=Dcm_NegativeResponseCodeType, direction=OUT
      operation WriteData: possible-error=[DataServices_DidF1A8_Data_VehFeature/E_NOT_OK, DataServices_DidF1A8_Data_VehFeature/E_PENDING]
        arg Data: type=Dcm_DataBuffer20FixedType, direction=INOUT
        arg OpStatus: type=Dcm_OpStatusType, direction=IN
        arg ErrorCode: type=Dcm_NegativeResponseCodeType, direction=OUT
      error E_NOT_OK: error-code=1
      error E_PENDING: error-code=10
    DataServices_DidF1A9_Data_ECUConfigFN
      operation ReadData: possible-error=[DataServices_DidF1A9_Data_ECUConfigFN/E_NOT_OK, DataServices_DidF1A9_Data_ECUConfigFN/E_PENDING]
        arg OpStatus: type=Dcm_OpStatusType, direction=IN
        arg Data: type=Dcm_DataBuffer5FixedType, direction=OUT
      operation ConditionCheckRead: possible-error=[DataServices_DidF1A9_Data_ECUConfigFN/E_NOT_OK, DataServices_DidF1A9_Data_ECUConfigFN/E_PENDING]
        arg OpStatus: type=Dcm_OpStatusType, direction=IN
        arg ErrorCode: type=Dcm_NegativeResponseCodeType, direction=OUT
      operation WriteData: possible-error=[DataServices_DidF1A9_Data_ECUConfigFN/E_NOT_OK, DataServices_DidF1A9_Data_ECUConfigFN/E_PENDING]
        arg Data: type=Dcm_DataBuffer5FixedType, direction=INOUT
        arg OpStatus: type=Dcm_OpStatusType, direction=IN
        arg ErrorCode: type=Dcm_NegativeResponseCodeType, direction=OUT
      error E_NOT_OK: error-code=1
      error E_PENDING: error-code=10
    DataServices_DidF1AA_Data_EUCProgPrcsFN
      operation ReadData: possible-error=DataServices_DidF1AA_Data_EUCProgPrcsFN/E_NOT_OK
        arg Data: type=Dcm_DataBuffer5FixedType, direction=OUT
      operation ConditionCheckRead: possible-error=[DataServices_DidF1AA_Data_EUCProgPrcsFN/E_NOT_OK, DataServices_DidF1AA_Data_EUCProgPrcsFN/E_PENDING]
        arg OpStatus: type=Dcm_OpStatusType, direction=IN
        arg ErrorCode: type=Dcm_NegativeResponseCodeType, direction=OUT
      error E_NOT_OK: error-code=1
      error E_PENDING: error-code=10
  5 x mode switch interface, all with is-service=true:
    If_DcmEcuReset
      mode group DcmEcuReset: type=DcmEcuReset
    If_DcmCommunicationControl
      mode group DcmCommunicationControl: type=DcmCommunicationControl
    If_DcmControlDTCSetting
      mode group DcmControlDTCSetting: type=DcmControlDTCSetting
    If_DcmModeRapidPowerShutDown
      mode group DcmModeRapidPowerShutDown: type=DcmModeRapidPowerShutDown
    If_DcmDiagnosticSessionControl
      mode group DcmDiagnosticSessionControl: type=DcmDiagnosticSessionControl
  impl type Dcm_ProtocolType: compu {0=DCM_OBD_ON_CAN, 1=DCM_OBD_ON_FLEXRAY, 2=DCM_OBD_ON_IP, 3=DCM_UDS_ON_CAN, 4=DCM_UDS_ON_FLEXRAY, 5=DCM_UDS_ON_IP, 6=DCM_ROE_ON_CAN, 7=DCM_ROE_ON_FLEXRAY, 8=DCM_ROE_ON_IP, 9=DCM_PERIODICTRANS_ON_CAN, 10=DCM_PERIODICTRANS_ON_FLEXRAY, 11=DCM_PERIODICTRANS_ON_IP, 255=DCM_PROTOCOL_UNUSED}, implementation-data-type=uint8
  impl type Dcm_NegativeResponseCodeType: compu {0=DCM_E_POSITIVERESPONSE, 16=DCM_E_GENERALREJECT, 17=DCM_E_SERVICENOTSUPPORTED, 18=DCM_E_SUBFUNCTIONNOTSUPPORTED, 19=DCM_E_INCORRECTMESSAGELENGTHORINVALIDFORMAT, 20=DCM_E_RESPONSETOOLONG, 33=DCM_E_BUSYREPEATREQUEST, 34=DCM_E_CONDITIONSNOTCORRECT, 36=DCM_E_REQUESTSEQUENCEERROR, 37=DCM_E_NORESPONSEFROMSUBNETCOMPONENT, 38=DCM_E_FAILUREPREVENTSEXECUTIONOFREQUESTEDACTION, 49=DCM_E_REQUESTOUTOFRANGE, 51=DCM_E_SECURITYACCESSDENIED, 53=DCM_E_INVALIDKEY, 54=DCM_E_EXCEEDNUMBEROFATTEMPTS, 55=DCM_E_REQUIREDTIMEDELAYNOTEXPIRED, 112=DCM_E_UPLOADDOWNLOADNOTACCEPTED, 113=DCM_E_TRANSFERDATASUSPENDED, 114=DCM_E_GENERALPROGRAMMINGFAILURE, 115=DCM_E_WRONGBLOCKSEQUENCECOUNTER, 120=DCM_E_REQUESTCORRECTLYRECEIVEDRESPONSEPENDING, 126=DCM_E_SUBFUNCTIONNOTSUPPORTEDINACTIVESESSION, 127=DCM_E_SERVICENOTSUPPORTEDINACTIVESESSION, 129=DCM_E_RPMTOOHIGH, 130=DCM_E_RPMTOOLOW, 131=DCM_E_ENGINEISRUNNING, 132=DCM_E_ENGINEISNOTRUNNING, 133=DCM_E_ENGINERUNTIMETOOLOW, 134=DCM_E_TEMPERATURETOOHIGH, 135=DCM_E_TEMPERATURETOOLOW, 136=DCM_E_VEHICLESPEEDTOOHIGH, 137=DCM_E_VEHICLESPEEDTOOLOW, 138=DCM_E_THROTTLE_PEDALTOOHIGH, 139=DCM_E_THROTTLE_PEDALTOOLOW, 140=DCM_E_TRANSMISSIONRANGENOTINNEUTRAL, 141=DCM_E_TRANSMISSIONRANGENOTINGEAR, 143=DCM_E_BRAKESWITCH_NOTCLOSED, 144=DCM_E_SHIFTERLEVERNOTINPARK, 145=DCM_E_TORQUECONVERTERCLUTCHLOCKED, 146=DCM_E_VOLTAGETOOHIGH, 147=DCM_E_VOLTAGETOOLOW}, implementation-data-type=uint8
  impl type Dcm_SecLevelType: compu {0=DCM_SEC_LEV_LOCKED, 1=SecurityLevel1, 255=DCM_SEC_LEV_ALL}, implementation-data-type=uint8
  impl type Dcm_SesCtrlType: compu {1=DCM_DEFAULT_SESSION, 2=DCM_PROGRAMMING_SESSION, 3=DCM_EXTENDED_DIAGNOSTIC_SESSION, 255=DCM_ALL_SESSION_LEVEL}, implementation-data-type=uint8
  impl type Dcm_OpStatusType: compu {0=DCM_INITIAL, 1=DCM_PENDING, 2=DCM_CANCEL, 3=DCM_FORCE_RCRRP_OK}, implementation-data-type=uint8
  impl type Dcm_DTRStatusType: compu {0=DCM_DTRSTATUS_VISIBLE, 1=DCM_DTRSTATUS_INVISIBLE}, implementation-data-type=uint8
  impl type Dcm_ConfirmationStatusType: compu {0=DCM_RES_POS_OK, 1=DCM_RES_POS_NOT_OK, 2=DCM_RES_NEG_OK, 3=DCM_RES_NEG_NOT_OK}, implementation-data-type=uint8
  impl type Dcm_RoeStateType: compu {0=DCM_ROE_ACTIVE, 1=DCM_ROE_UNACTIVE}, implementation-data-type=uint8
  15 x impl type, all with category=ARRAY:
    Dcm_DataBuffer1024FixedType
      element ARRAYELEMENT: array-size=1024, array-size-semantics=FIXED-SIZE, implementation-data-type=uint8
    Dcm_DataBuffer10FixedType
      element ARRAYELEMENT: array-size=10, array-size-semantics=FIXED-SIZE, implementation-data-type=uint8
    Dcm_DataBuffer11FixedType
      element ARRAYELEMENT: array-size=11, array-size-semantics=FIXED-SIZE, implementation-data-type=uint8
    Dcm_DataBuffer16FixedType
      element ARRAYELEMENT: array-size=16, array-size-semantics=FIXED-SIZE, implementation-data-type=uint8
    Dcm_DataBuffer17FixedType
      element ARRAYELEMENT: array-size=17, array-size-semantics=FIXED-SIZE, implementation-data-type=uint8
    Dcm_DataBuffer1FixedType
      element ARRAYELEMENT: array-size=1, array-size-semantics=FIXED-SIZE, implementation-data-type=uint8
    Dcm_DataBuffer20FixedType
      element ARRAYELEMENT: array-size=20, array-size-semantics=FIXED-SIZE, implementation-data-type=uint8
    Dcm_DataBuffer2FixedType
      element ARRAYELEMENT: array-size=2, array-size-semantics=FIXED-SIZE, implementation-data-type=uint8
    Dcm_DataBuffer3FixedType
      element ARRAYELEMENT: array-size=3, array-size-semantics=FIXED-SIZE, implementation-data-type=uint8
    Dcm_DataBuffer40FixedType
      element ARRAYELEMENT: array-size=40, array-size-semantics=FIXED-SIZE, implementation-data-type=uint8
    Dcm_DataBuffer4FixedType
      element ARRAYELEMENT: array-size=4, array-size-semantics=FIXED-SIZE, implementation-data-type=uint8
    Dcm_DataBuffer5FixedType
      element ARRAYELEMENT: array-size=5, array-size-semantics=FIXED-SIZE, implementation-data-type=uint8
    Dcm_DataBuffer6FixedType
      element ARRAYELEMENT: array-size=6, array-size-semantics=FIXED-SIZE, implementation-data-type=uint8
    Dcm_DataBuffer7FixedType
      element ARRAYELEMENT: array-size=7, array-size-semantics=FIXED-SIZE, implementation-data-type=uint8
    Dcm_DataBuffer8FixedType
      element ARRAYELEMENT: array-size=8, array-size-semantics=FIXED-SIZE, implementation-data-type=uint8
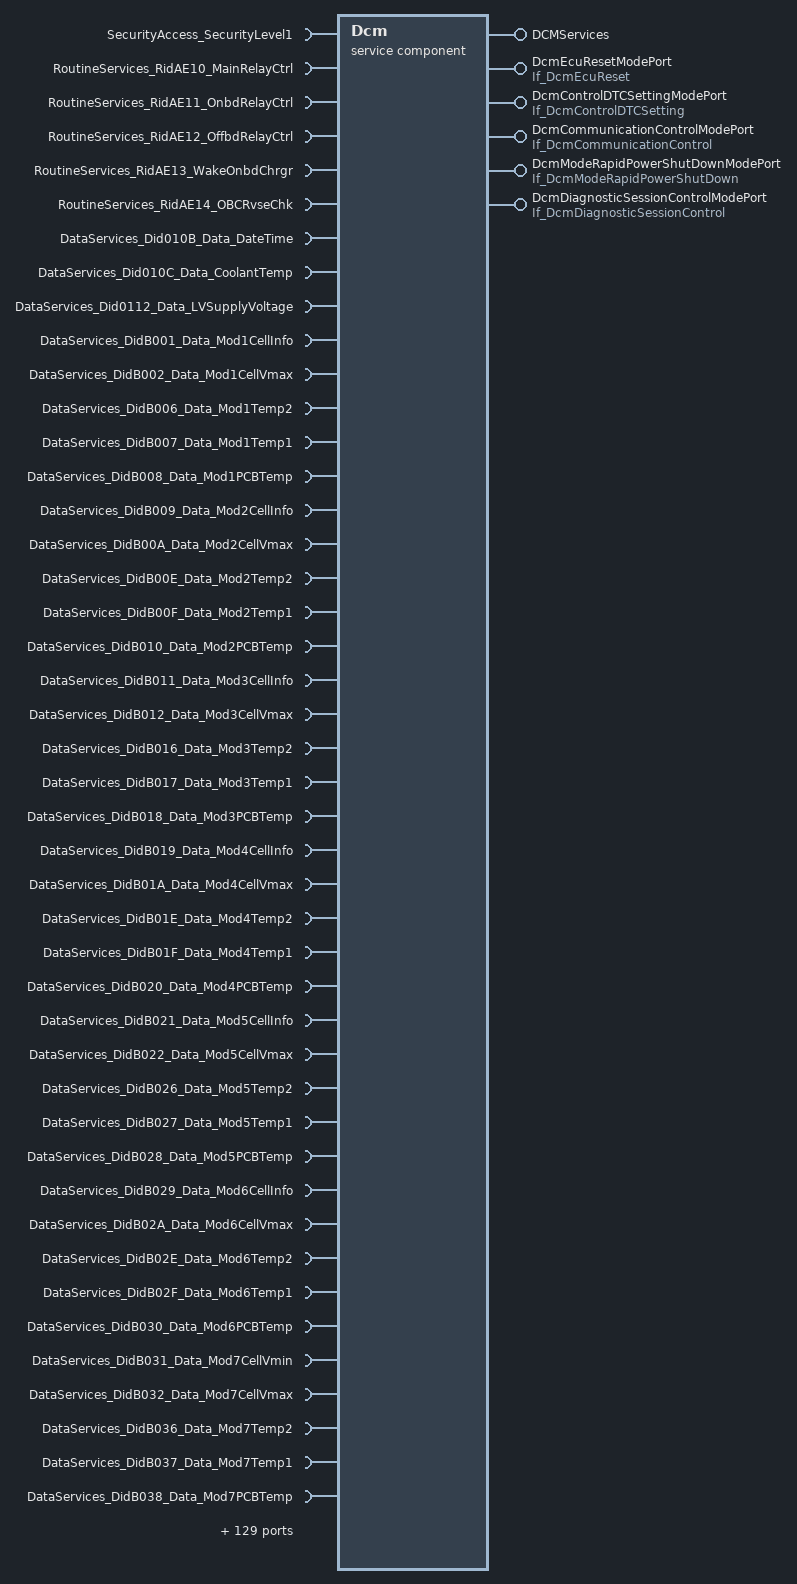
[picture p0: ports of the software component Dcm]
  service sw component type Dcm
    6 x provide port:
      DCMServices: provided-interface=DCMServices
        provided-com-specs:
          operation=GetActiveProtocol, queue-length=1
          operation=GetSesCtrlType, queue-length=1
          operation=GetSecurityLevel, queue-length=1
          operation=ResetToDefaultSession, queue-length=1
      DcmEcuResetModePort: provided-interface=If_DcmEcuReset
      DcmControlDTCSettingModePort: provided-interface=If_DcmControlDTCSetting
      DcmCommunicationControlModePort: provided-interface=If_DcmCommunicationControl
      DcmModeRapidPowerShutDownModePort: provided-interface=If_DcmModeRapidPowerShutDown
      DcmDiagnosticSessionControlModePort: provided-interface=If_DcmDiagnosticSessionControl
    173 x require port:
      SecurityAccess_SecurityLevel1: required-interface=SecurityAccess_SecurityLevel1
      RoutineServices_RidAE10_MainRelayCtrl: required-interface=RoutineServices_RidAE10_MainRelayCtrl
      RoutineServices_RidAE11_OnbdRelayCtrl: required-interface=RoutineServices_RidAE11_OnbdRelayCtrl
      RoutineServices_RidAE12_OffbdRelayCtrl: required-interface=RoutineServices_RidAE12_OffbdRelayCtrl
      RoutineServices_RidAE13_WakeOnbdChrgr: required-interface=RoutineServices_RidAE13_WakeOnbdChrgr
      RoutineServices_RidAE14_OBCRvseChk: required-interface=RoutineServices_RidAE14_OBCRvseChk
      DataServices_Did010B_Data_DateTime: required-interface=DataServices_Did010B_Data_DateTime
      DataServices_Did010C_Data_CoolantTemp: required-interface=DataServices_Did010C_Data_CoolantTemp
      DataServices_Did0112_Data_LVSupplyVoltage: required-interface=DataServices_Did0112_Data_LVSupplyVoltage
      DataServices_DidB001_Data_Mod1CellInfo: required-interface=DataServices_DidB001_Data_Mod1CellInfo
      DataServices_DidB002_Data_Mod1CellVmax: required-interface=DataServices_DidB002_Data_Mod1CellVmax
      DataServices_DidB006_Data_Mod1Temp2: required-interface=DataServices_DidB006_Data_Mod1Temp2
      DataServices_DidB007_Data_Mod1Temp1: required-interface=DataServices_DidB007_Data_Mod1Temp1
      DataServices_DidB008_Data_Mod1PCBTemp: required-interface=DataServices_DidB008_Data_Mod1PCBTemp
      DataServices_DidB009_Data_Mod2CellInfo: required-interface=DataServices_DidB009_Data_Mod2CellInfo
      DataServices_DidB00A_Data_Mod2CellVmax: required-interface=DataServices_DidB00A_Data_Mod2CellVmax
      DataServices_DidB00E_Data_Mod2Temp2: required-interface=DataServices_DidB00E_Data_Mod2Temp2
      DataServices_DidB00F_Data_Mod2Temp1: required-interface=DataServices_DidB00F_Data_Mod2Temp1
      DataServices_DidB010_Data_Mod2PCBTemp: required-interface=DataServices_DidB010_Data_Mod2PCBTemp
      DataServices_DidB011_Data_Mod3CellInfo: required-interface=DataServices_DidB011_Data_Mod3CellInfo
      DataServices_DidB012_Data_Mod3CellVmax: required-interface=DataServices_DidB012_Data_Mod3CellVmax
      DataServices_DidB016_Data_Mod3Temp2: required-interface=DataServices_DidB016_Data_Mod3Temp2
      DataServices_DidB017_Data_Mod3Temp1: required-interface=DataServices_DidB017_Data_Mod3Temp1
      DataServices_DidB018_Data_Mod3PCBTemp: required-interface=DataServices_DidB018_Data_Mod3PCBTemp
      DataServices_DidB019_Data_Mod4CellInfo: required-interface=DataServices_DidB019_Data_Mod4CellInfo
      DataServices_DidB01A_Data_Mod4CellVmax: required-interface=DataServices_DidB01A_Data_Mod4CellVmax
      DataServices_DidB01E_Data_Mod4Temp2: required-interface=DataServices_DidB01E_Data_Mod4Temp2
      DataServices_DidB01F_Data_Mod4Temp1: required-interface=DataServices_DidB01F_Data_Mod4Temp1
      DataServices_DidB020_Data_Mod4PCBTemp: required-interface=DataServices_DidB020_Data_Mod4PCBTemp
      DataServices_DidB021_Data_Mod5CellInfo: required-interface=DataServices_DidB021_Data_Mod5CellInfo
      DataServices_DidB022_Data_Mod5CellVmax: required-interface=DataServices_DidB022_Data_Mod5CellVmax
      DataServices_DidB026_Data_Mod5Temp2: required-interface=DataServices_DidB026_Data_Mod5Temp2
      DataServices_DidB027_Data_Mod5Temp1: required-interface=DataServices_DidB027_Data_Mod5Temp1
      DataServices_DidB028_Data_Mod5PCBTemp: required-interface=DataServices_DidB028_Data_Mod5PCBTemp
      DataServices_DidB029_Data_Mod6CellInfo: required-interface=DataServices_DidB029_Data_Mod6CellInfo
      DataServices_DidB02A_Data_Mod6CellVmax: required-interface=DataServices_DidB02A_Data_Mod6CellVmax
      DataServices_DidB02E_Data_Mod6Temp2: required-interface=DataServices_DidB02E_Data_Mod6Temp2
      DataServices_DidB02F_Data_Mod6Temp1: required-interface=DataServices_DidB02F_Data_Mod6Temp1
      DataServices_DidB030_Data_Mod6PCBTemp: required-interface=DataServices_DidB030_Data_Mod6PCBTemp
      DataServices_DidB031_Data_Mod7CellVmin: required-interface=DataServices_DidB031_Data_Mod7CellVmin
      DataServices_DidB032_Data_Mod7CellVmax: required-interface=DataServices_DidB032_Data_Mod7CellVmax
      DataServices_DidB036_Data_Mod7Temp2: required-interface=DataServices_DidB036_Data_Mod7Temp2
      DataServices_DidB037_Data_Mod7Temp1: required-interface=DataServices_DidB037_Data_Mod7Temp1
      DataServices_DidB038_Data_Mod7PCBTemp: required-interface=DataServices_DidB038_Data_Mod7PCBTemp
      DataServices_DidB039_Data_Mod8CellVmin: required-interface=DataServices_DidB039_Data_Mod8CellVmin
      DataServices_DidB03A_Data_Mod8CellVmax: required-interface=DataServices_DidB03A_Data_Mod8CellVmax
      DataServices_DidB03E_Data_Mod8Temp2: required-interface=DataServices_DidB03E_Data_Mod8Temp2
      DataServices_DidB03F_Data_Mod8Temp1: required-interface=DataServices_DidB03F_Data_Mod8Temp1
      DataServices_DidB040_Data_Mod8PCBTemp: required-interface=DataServices_DidB040_Data_Mod8PCBTemp
      DataServices_DidB041_Data_BMSBusV: required-interface=DataServices_DidB041_Data_BMSBusV
      DataServices_DidB042_Data_BMSBatV: required-interface=DataServices_DidB042_Data_BMSBatV
      DataServices_DidB043_Data_BMSCur1: required-interface=DataServices_DidB043_Data_BMSCur1
      DataServices_DidB044_Data_BMSCur2: required-interface=DataServices_DidB044_Data_BMSCur2
      DataServices_DidB045_Data_BMSIso: required-interface=DataServices_DidB045_Data_BMSIso
      DataServices_DidB046_Data_BMSPackSOC: required-interface=DataServices_DidB046_Data_BMSPackSOC
      DataServices_DidB047_Data_BMSFltLvl: required-interface=DataServices_DidB047_Data_BMSFltLvl
      DataServices_DidB048_Data_BMSBscSts: required-interface=DataServices_DidB048_Data_BMSBscSts
      DataServices_DidB049_Data_BMSVehHVIL: required-interface=DataServices_DidB049_Data_BMSVehHVIL
      DataServices_DidB04A_Data_BMSChgHVIL: required-interface=DataServices_DidB04A_Data_BMSChgHVIL
      DataServices_DidB04B_Data_BMSVehWake: required-interface=DataServices_DidB04B_Data_BMSVehWake
      DataServices_DidB04C_Data_BMSBMSOnbdWake: required-interface=DataServices_DidB04C_Data_BMSBMSOnbdWake
      DataServices_DidB04D_Data_BMSOffbdWake: required-interface=DataServices_DidB04D_Data_BMSOffbdWake
      DataServices_DidB04E_Data_BMSLvBat: required-interface=DataServices_DidB04E_Data_BMSLvBat
      DataServices_DidB04F_Data_BMSModuleEn: required-interface=DataServices_DidB04F_Data_BMSModuleEn
      DataServices_DidB050_Data_OffbdChgPlugOn: required-interface=DataServices_DidB050_Data_OffbdChgPlugOn
      DataServices_DidB051_Data_OnbdChgPlugOn: required-interface=DataServices_DidB051_Data_OnbdChgPlugOn
      DataServices_DidB052_Data_CrashSts: required-interface=DataServices_DidB052_Data_CrashSts
      DataServices_DidB053_Data_BMSBalSts: required-interface=DataServices_DidB053_Data_BMSBalSts
      DataServices_DidB054_Data_BMSBalCnt: required-interface=DataServices_DidB054_Data_BMSBalCnt
      DataServices_DidB055_Data_BMSEnergyAvail: required-interface=DataServices_DidB055_Data_BMSEnergyAvail
      DataServices_DidB056_Data_BMSCellTmax: required-interface=DataServices_DidB056_Data_BMSCellTmax
      DataServices_DidB057_Data_BMSCellTmin: required-interface=DataServices_DidB057_Data_BMSCellTmin
      DataServices_DidB058_Data_BMSCellVmax: required-interface=DataServices_DidB058_Data_BMSCellVmax
      DataServices_DidB059_Data_BMSCellVmin: required-interface=DataServices_DidB059_Data_BMSCellVmin
      DataServices_DidB05C_Data_BMSCoolantTemp: required-interface=DataServices_DidB05C_Data_BMSCoolantTemp
      DataServices_DidB05F_Data_BMSShuntTemp: required-interface=DataServices_DidB05F_Data_BMSShuntTemp
      DataServices_DidB061_Data_BMSPackSoh: required-interface=DataServices_DidB061_Data_BMSPackSoh
      DataServices_DidB062_Data_BMSPackCapFade: required-interface=DataServices_DidB062_Data_BMSPackCapFade
      DataServices_DidB063_Data_BMSPackResiGrw: required-interface=DataServices_DidB063_Data_BMSPackResiGrw
      DataServices_DidB064_Data_BMSCldAccumTime: required-interface=DataServices_DidB064_Data_BMSCldAccumTime
      DataServices_DidB065_Data_BMSCldCapFade: required-interface=DataServices_DidB065_Data_BMSCldCapFade
      DataServices_DidB066_Data_BMSCldResiGrw: required-interface=DataServices_DidB066_Data_BMSCldResiGrw
      DataServices_DidB067_Data_BMSCycAccumTime: required-interface=DataServices_DidB067_Data_BMSCycAccumTime
      DataServices_DidB068_Data_BMSCycAccumEngy: required-interface=DataServices_DidB068_Data_BMSCycAccumEngy
      DataServices_DidB069_Data_BMSCycCapFade: required-interface=DataServices_DidB069_Data_BMSCycCapFade
      DataServices_DidB06A_Data_BMSCycResiGrw: required-interface=DataServices_DidB06A_Data_BMSCycResiGrw
      DataServices_DidB06D_Data_HvmRtcTime: required-interface=DataServices_DidB06D_Data_HvmRtcTime
      DataServices_DidB072_Data_BMSAccumAhLower: required-interface=DataServices_DidB072_Data_BMSAccumAhLower
      DataServices_DidB073_Data_BMSAccumAhUpper: required-interface=DataServices_DidB073_Data_BMSAccumAhUpper
      DataServices_DidB074_Data_BMSCellTemDiffTime: required-interface=DataServices_DidB074_Data_BMSCellTemDiffTime
      DataServices_DidB075_Data_UnlockLogi: required-interface=DataServices_DidB075_Data_UnlockLogi
      DataServices_DidB076_Data_BMSOffChgAccumTime: required-interface=DataServices_DidB076_Data_BMSOffChgAccumTime
      DataServices_DidB080_Data_BMSBalanceTime: required-interface=DataServices_DidB080_Data_BMSBalanceTime
      DataServices_DidB081_Data_CMUMissingCnt: required-interface=DataServices_DidB081_Data_CMUMissingCnt
      DataServices_DidB082_Data_CMUMissingTime: required-interface=DataServices_DidB082_Data_CMUMissingTime
      DataServices_DidB083_Data_ExtPackLeakageFltCnt: required-interface=DataServices_DidB083_Data_ExtPackLeakageFltCnt
      DataServices_DidB084_Data_IntPackLeakageFltCnt: required-interface=DataServices_DidB084_Data_IntPackLeakageFltCnt
      DataServices_DidB085_Data_CellOverVoltageCnt: required-interface=DataServices_DidB085_Data_CellOverVoltageCnt
      DataServices_DidB086_Data_PrechrgResEnrgExCnt: required-interface=DataServices_DidB086_Data_PrechrgResEnrgExCnt
      DataServices_DidB087_Data_PrechrgTimeOutExCnt: required-interface=DataServices_DidB087_Data_PrechrgTimeOutExCnt
      DataServices_DidB088_Data_RlyOpenWithCrntCnt: required-interface=DataServices_DidB088_Data_RlyOpenWithCrntCnt
      DataServices_DidB089_Data_RlyOpenWithCrntLvl1Cnt: required-interface=DataServices_DidB089_Data_RlyOpenWithCrntLvl1Cnt
      DataServices_DidB08A_Data_RlyOpenWithCrntLvl2Cnt: required-interface=DataServices_DidB08A_Data_RlyOpenWithCrntLvl2Cnt
      DataServices_DidB08B_Data_RlyOpenWithCrntLvl3Cnt: required-interface=DataServices_DidB08B_Data_RlyOpenWithCrntLvl3Cnt
      DataServices_DidB08C_Data_PackSOCLowTime: required-interface=DataServices_DidB08C_Data_PackSOCLowTime
      DataServices_DidB08D_Data_CellUnderVoltageCnt: required-interface=DataServices_DidB08D_Data_CellUnderVoltageCnt
      DataServices_DidB08E_Data_TempLvl1Cnt: required-interface=DataServices_DidB08E_Data_TempLvl1Cnt
      DataServices_DidB08F_Data_TempLvl2Cnt: required-interface=DataServices_DidB08F_Data_TempLvl2Cnt
      DataServices_DidB090_Data_TempLvl3Cnt: required-interface=DataServices_DidB090_Data_TempLvl3Cnt
      DataServices_DidB091_Data_TempLvl4Cnt: required-interface=DataServices_DidB091_Data_TempLvl4Cnt
      DataServices_DidB092_Data_TempLvl5Cnt: required-interface=DataServices_DidB092_Data_TempLvl5Cnt
      DataServices_DidB093_Data_TempLvl6Cnt: required-interface=DataServices_DidB093_Data_TempLvl6Cnt
      DataServices_DidB094_Data_TempLvl7Cnt: required-interface=DataServices_DidB094_Data_TempLvl7Cnt
      DataServices_DidB095_Data_BMSOnChgEngy: required-interface=DataServices_DidB095_Data_BMSOnChgEngy
      DataServices_DidB096_Data_BMSReservedData1: required-interface=DataServices_DidB096_Data_BMSReservedData1
      DataServices_DidB097_Data_BMSReservedData2: required-interface=DataServices_DidB097_Data_BMSReservedData2
      DataServices_DidB098_Data_BMSReservedData3: required-interface=DataServices_DidB098_Data_BMSReservedData3
      DataServices_DidB099_Data_BMSReservedData4: required-interface=DataServices_DidB099_Data_BMSReservedData4
      DataServices_DidB09A_Data_BMSReservedData5: required-interface=DataServices_DidB09A_Data_BMSReservedData5
      DataServices_DidB09B_Data_BMSReservedData6: required-interface=DataServices_DidB09B_Data_BMSReservedData6
      DataServices_DidB09C_Data_BMSReservedData7: required-interface=DataServices_DidB09C_Data_BMSReservedData7
      DataServices_DidB09D_Data_BMSReservedData8: required-interface=DataServices_DidB09D_Data_BMSReservedData8
      DataServices_DidB09E_Data_BMSReservedData9: required-interface=DataServices_DidB09E_Data_BMSReservedData9
      DataServices_DidB09F_Data_BMSReservedData10: required-interface=DataServices_DidB09F_Data_BMSReservedData10
      DataServices_DidB0A0_Data_BMSOnChgAccumTime: required-interface=DataServices_DidB0A0_Data_BMSOnChgAccumTime
      DataServices_DidB0A1_Data_BMSOnChgCnt: required-interface=DataServices_DidB0A1_Data_BMSOnChgCnt
      DataServices_DidB0A2_Data_BMSSupConfigParam: required-interface=DataServices_DidB0A2_Data_BMSSupConfigParam
      DataServices_DidB0BD_Data_VehicleSpeed: required-interface=DataServices_DidB0BD_Data_VehicleSpeed
      DataServices_DidD001_Data_PowerMode: required-interface=DataServices_DidD001_Data_PowerMode
      DataServices_DidE000_Data_CoolingPump: required-interface=DataServices_DidE000_Data_CoolingPump
      DataServices_DidE001_Data_ChgIndDriver: required-interface=DataServices_DidE001_Data_ChgIndDriver
      DataServices_DidE002_Data_ConnIndDriver: required-interface=DataServices_DidE002_Data_ConnIndDriver
      DataServices_DidE003_Data_LeakDetectEn: required-interface=DataServices_DidE003_Data_LeakDetectEn
      DataServices_DidE004_Data_BthIndDriver: required-interface=DataServices_DidE004_Data_BthIndDriver
      DataServices_DidE101_Data_Odometer: required-interface=DataServices_DidE101_Data_Odometer
      DataServices_DidF100_Data_SVIF: required-interface=DataServices_DidF100_Data_SVIF
      DataServices_DidF110_Data_PIFptr: required-interface=DataServices_DidF110_Data_PIFptr
      DataServices_DidF111_Data_PIF1: required-interface=DataServices_DidF111_Data_PIF1
      DataServices_DidF112_Data_PIF2: required-interface=DataServices_DidF112_Data_PIF2
      DataServices_DidF113_Data_PIF3: required-interface=DataServices_DidF113_Data_PIF3
      DataServices_DidF114_Data_PIF4: required-interface=DataServices_DidF114_Data_PIF4
      DataServices_DidF115_Data_PIF5: required-interface=DataServices_DidF115_Data_PIF5
      DataServices_DidF116_Data_PIF6: required-interface=DataServices_DidF116_Data_PIF6
      DataServices_DidF117_Data_PIF7: required-interface=DataServices_DidF117_Data_PIF7
      DataServices_DidF118_Data_PIF8: required-interface=DataServices_DidF118_Data_PIF8
      DataServices_DidF119_Data_PIF9: required-interface=DataServices_DidF119_Data_PIF9
      DataServices_DidF11A_Data_PIFA: required-interface=DataServices_DidF11A_Data_PIFA
      DataServices_DidF11B_Data_PIFB: required-interface=DataServices_DidF11B_Data_PIFB
      DataServices_DidF11C_Data_PIFC: required-interface=DataServices_DidF11C_Data_PIFC
      DataServices_DidF11D_Data_PIFD: required-interface=DataServices_DidF11D_Data_PIFD
      DataServices_DidF11E_Data_PIFE: required-interface=DataServices_DidF11E_Data_PIFE
      DataServices_DidF11F_Data_PIFF: required-interface=DataServices_DidF11F_Data_PIFF
      DataServices_DidF120_Data_NIFfactory: required-interface=DataServices_DidF120_Data_NIFfactory
      DataServices_DidF121_Data_NIFcur: required-interface=DataServices_DidF121_Data_NIFcur
      DataServices_DidF183_Data_BootloaderSRN: required-interface=DataServices_DidF183_Data_BootloaderSRN
      DataServices_DidF187_Data_ECUPN: required-interface=DataServices_DidF187_Data_ECUPN
      DataServices_DidF18A_Data_SupID: required-interface=DataServices_DidF18A_Data_SupID
      DataServices_DidF18B_Data_ECUDate: required-interface=DataServices_DidF18B_Data_ECUDate
      DataServices_DidF18C_Data_ECUSN: required-interface=DataServices_DidF18C_Data_ECUSN
      DataServices_DidF190_Data_VIN: required-interface=DataServices_DidF190_Data_VIN
      DataServices_DidF191_Data_ECUHWNo: required-interface=DataServices_DidF191_Data_ECUHWNo
      DataServices_DidF192_Data_SupHWRN: required-interface=DataServices_DidF192_Data_SupHWRN
      DataServices_DidF194_Data_SupSWRN: required-interface=DataServices_DidF194_Data_SupSWRN
      DataServices_DidF198_Data_ConfigTF: required-interface=DataServices_DidF198_Data_ConfigTF
      DataServices_DidF1A0_Data_AppSWNo: required-interface=DataServices_DidF1A0_Data_AppSWNo
      DataServices_DidF1A1_Data_CalSWNo: required-interface=DataServices_DidF1A1_Data_CalSWNo
      DataServices_DidF1A2_Data_NCFRN: required-interface=DataServices_DidF1A2_Data_NCFRN
      DataServices_DidF1A5_Data_ECUIndex: required-interface=DataServices_DidF1A5_Data_ECUIndex
      DataServices_DidF1A8_Data_VehFeature: required-interface=DataServices_DidF1A8_Data_VehFeature
      DataServices_DidF1A9_Data_ECUConfigFN: required-interface=DataServices_DidF1A9_Data_ECUConfigFN
      DataServices_DidF1AA_Data_EUCProgPrcsFN: required-interface=DataServices_DidF1AA_Data_EUCProgPrcsFN
      CallbackDCMRequestServices_CBReqServInd_1: required-interface=CallbackDCMRequestServices
      ServiceRequestManufacturerNotification_DcmDslServiceRequestManufacturerNotification: required-interface=ServiceRequestNotification
    behavior IB_Dcm: data-type-mapping=DcmModeMappingSet, handle-termination-and-restart=NO-SUPPORT, included-data-type-set=data-type=[Dcm_ProtocolType, Dcm_NegativeResponseCodeType, Dcm_SecLevelType, Dcm_SesCtrlType, Dcm_OpStatusType, Dcm_DTRStatusType, Dcm_ConfirmationStatusType, Dcm_RoeStateType]
      4 x operation invoked event:
        OI_GetActiveProtocol: start-on-event=GetActiveProtocol, operation=DCMServices.GetActiveProtocol
        OI_GetSesCtrlType: start-on-event=GetSesCtrlType, operation=DCMServices.GetSesCtrlType
        OI_GetSecurityLevel: start-on-event=GetSecurityLevel, operation=DCMServices.GetSecurityLevel
        OI_ResetToDefaultSession: start-on-event=ResetToDefaultSession, operation=DCMServices.ResetToDefaultSession
      5 x runnable:
        GetActiveProtocol: can-be-invoked-concurrently=true, symbol=Dcm_GetActiveProtocol
        GetSesCtrlType: can-be-invoked-concurrently=true, symbol=Dcm_GetSesCtrlType
        GetSecurityLevel: can-be-invoked-concurrently=true, symbol=Dcm_GetSecurityLevel
        ResetToDefaultSession: can-be-invoked-concurrently=true, symbol=Dcm_ResetToDefaultSession
        Dcm_MainFunction
          412 x sync call, all with timeout=0.0:
            SSCP_0: operation=SecurityAccess_SecurityLevel1.GetSeed
            SSCP_1: operation=SecurityAccess_SecurityLevel1.CompareKey
            SSCP_2: operation=RoutineServices_RidAE10_MainRelayCtrl.Start
            SSCP_3: operation=RoutineServices_RidAE10_MainRelayCtrl.Stop
            SSCP_4: operation=RoutineServices_RidAE10_MainRelayCtrl.RequestResults
            SSCP_5: operation=RoutineServices_RidAE11_OnbdRelayCtrl.Start
            SSCP_6: operation=RoutineServices_RidAE11_OnbdRelayCtrl.Stop
            SSCP_7: operation=RoutineServices_RidAE11_OnbdRelayCtrl.RequestResults
            SSCP_8: operation=RoutineServices_RidAE12_OffbdRelayCtrl.Start
            SSCP_9: operation=RoutineServices_RidAE12_OffbdRelayCtrl.Stop
            SSCP_10: operation=RoutineServices_RidAE12_OffbdRelayCtrl.RequestResults
            SSCP_11: operation=RoutineServices_RidAE13_WakeOnbdChrgr.Start
            SSCP_12: operation=RoutineServices_RidAE13_WakeOnbdChrgr.RequestResults
            SSCP_13: operation=RoutineServices_RidAE14_OBCRvseChk.Start
            SSCP_14: operation=RoutineServices_RidAE14_OBCRvseChk.RequestResults
            SSCP_15: operation=DataServices_Did010B_Data_DateTime.ReadData
            SSCP_16: operation=DataServices_Did010B_Data_DateTime.ConditionCheckRead
            SSCP_17: operation=DataServices_Did010C_Data_CoolantTemp.ReadData
            SSCP_18: operation=DataServices_Did010C_Data_CoolantTemp.ConditionCheckRead
            SSCP_19: operation=DataServices_Did0112_Data_LVSupplyVoltage.ReadData
            SSCP_20: operation=DataServices_Did0112_Data_LVSupplyVoltage.ConditionCheckRead
            SSCP_21: operation=DataServices_DidB001_Data_Mod1CellInfo.ReadData
            SSCP_22: operation=DataServices_DidB001_Data_Mod1CellInfo.ConditionCheckRead
            SSCP_23: operation=DataServices_DidB002_Data_Mod1CellVmax.ReadData
            SSCP_24: operation=DataServices_DidB002_Data_Mod1CellVmax.ConditionCheckRead
            SSCP_25: operation=DataServices_DidB006_Data_Mod1Temp2.ReadData
            SSCP_26: operation=DataServices_DidB006_Data_Mod1Temp2.ConditionCheckRead
            SSCP_27: operation=DataServices_DidB007_Data_Mod1Temp1.ReadData
            SSCP_28: operation=DataServices_DidB007_Data_Mod1Temp1.ConditionCheckRead
            SSCP_29: operation=DataServices_DidB008_Data_Mod1PCBTemp.ReadData
            SSCP_30: operation=DataServices_DidB008_Data_Mod1PCBTemp.ConditionCheckRead
            SSCP_31: operation=DataServices_DidB009_Data_Mod2CellInfo.ReadData
            SSCP_32: operation=DataServices_DidB009_Data_Mod2CellInfo.ConditionCheckRead
            SSCP_33: operation=DataServices_DidB00A_Data_Mod2CellVmax.ReadData
            SSCP_34: operation=DataServices_DidB00A_Data_Mod2CellVmax.ConditionCheckRead
            SSCP_35: operation=DataServices_DidB00E_Data_Mod2Temp2.ReadData
            SSCP_36: operation=DataServices_DidB00E_Data_Mod2Temp2.ConditionCheckRead
            SSCP_37: operation=DataServices_DidB00F_Data_Mod2Temp1.ReadData
            SSCP_38: operation=DataServices_DidB00F_Data_Mod2Temp1.ConditionCheckRead
            SSCP_39: operation=DataServices_DidB010_Data_Mod2PCBTemp.ReadData
            SSCP_40: operation=DataServices_DidB010_Data_Mod2PCBTemp.ConditionCheckRead
            SSCP_41: operation=DataServices_DidB011_Data_Mod3CellInfo.ReadData
            SSCP_42: operation=DataServices_DidB011_Data_Mod3CellInfo.ConditionCheckRead
            SSCP_43: operation=DataServices_DidB012_Data_Mod3CellVmax.ReadData
            SSCP_44: operation=DataServices_DidB012_Data_Mod3CellVmax.ConditionCheckRead
            SSCP_45: operation=DataServices_DidB016_Data_Mod3Temp2.ReadData
            SSCP_46: operation=DataServices_DidB016_Data_Mod3Temp2.ConditionCheckRead
            SSCP_47: operation=DataServices_DidB017_Data_Mod3Temp1.ReadData
            SSCP_48: operation=DataServices_DidB017_Data_Mod3Temp1.ConditionCheckRead
            SSCP_49: operation=DataServices_DidB018_Data_Mod3PCBTemp.ReadData
            SSCP_50: operation=DataServices_DidB018_Data_Mod3PCBTemp.ConditionCheckRead
            SSCP_51: operation=DataServices_DidB019_Data_Mod4CellInfo.ReadData
            SSCP_52: operation=DataServices_DidB019_Data_Mod4CellInfo.ConditionCheckRead
            SSCP_53: operation=DataServices_DidB01A_Data_Mod4CellVmax.ReadData
            SSCP_54: operation=DataServices_DidB01A_Data_Mod4CellVmax.ConditionCheckRead
            SSCP_55: operation=DataServices_DidB01E_Data_Mod4Temp2.ReadData
            SSCP_56: operation=DataServices_DidB01E_Data_Mod4Temp2.ConditionCheckRead
            SSCP_57: operation=DataServices_DidB01F_Data_Mod4Temp1.ReadData
            SSCP_58: operation=DataServices_DidB01F_Data_Mod4Temp1.ConditionCheckRead
            SSCP_59: operation=DataServices_DidB020_Data_Mod4PCBTemp.ReadData
            SSCP_60: operation=DataServices_DidB020_Data_Mod4PCBTemp.ConditionCheckRead
            SSCP_61: operation=DataServices_DidB021_Data_Mod5CellInfo.ReadData
            SSCP_62: operation=DataServices_DidB021_Data_Mod5CellInfo.ConditionCheckRead
            SSCP_63: operation=DataServices_DidB022_Data_Mod5CellVmax.ReadData
            SSCP_64: operation=DataServices_DidB022_Data_Mod5CellVmax.ConditionCheckRead
            SSCP_65: operation=DataServices_DidB026_Data_Mod5Temp2.ReadData
            SSCP_66: operation=DataServices_DidB026_Data_Mod5Temp2.ConditionCheckRead
            SSCP_67: operation=DataServices_DidB027_Data_Mod5Temp1.ReadData
            SSCP_68: operation=DataServices_DidB027_Data_Mod5Temp1.ConditionCheckRead
            SSCP_69: operation=DataServices_DidB028_Data_Mod5PCBTemp.ReadData
            SSCP_70: operation=DataServices_DidB028_Data_Mod5PCBTemp.ConditionCheckRead
            SSCP_71: operation=DataServices_DidB029_Data_Mod6CellInfo.ReadData
            SSCP_72: operation=DataServices_DidB029_Data_Mod6CellInfo.ConditionCheckRead
            SSCP_73: operation=DataServices_DidB02A_Data_Mod6CellVmax.ReadData
            SSCP_74: operation=DataServices_DidB02A_Data_Mod6CellVmax.ConditionCheckRead
            SSCP_75: operation=DataServices_DidB02E_Data_Mod6Temp2.ReadData
            SSCP_76: operation=DataServices_DidB02E_Data_Mod6Temp2.ConditionCheckRead
            SSCP_77: operation=DataServices_DidB02F_Data_Mod6Temp1.ReadData
            SSCP_78: operation=DataServices_DidB02F_Data_Mod6Temp1.ConditionCheckRead
            SSCP_79: operation=DataServices_DidB030_Data_Mod6PCBTemp.ReadData
            SSCP_80: operation=DataServices_DidB030_Data_Mod6PCBTemp.ConditionCheckRead
            SSCP_81: operation=DataServices_DidB031_Data_Mod7CellVmin.ReadData
            SSCP_82: operation=DataServices_DidB031_Data_Mod7CellVmin.ConditionCheckRead
            SSCP_83: operation=DataServices_DidB032_Data_Mod7CellVmax.ReadData
            SSCP_84: operation=DataServices_DidB032_Data_Mod7CellVmax.ConditionCheckRead
            SSCP_85: operation=DataServices_DidB036_Data_Mod7Temp2.ReadData
            SSCP_86: operation=DataServices_DidB036_Data_Mod7Temp2.ConditionCheckRead
            SSCP_87: operation=DataServices_DidB037_Data_Mod7Temp1.ReadData
            SSCP_88: operation=DataServices_DidB037_Data_Mod7Temp1.ConditionCheckRead
            SSCP_89: operation=DataServices_DidB038_Data_Mod7PCBTemp.ReadData
            SSCP_90: operation=DataServices_DidB038_Data_Mod7PCBTemp.ConditionCheckRead
            SSCP_91: operation=DataServices_DidB039_Data_Mod8CellVmin.ReadData
            SSCP_92: operation=DataServices_DidB039_Data_Mod8CellVmin.ConditionCheckRead
            SSCP_93: operation=DataServices_DidB03A_Data_Mod8CellVmax.ReadData
            SSCP_94: operation=DataServices_DidB03A_Data_Mod8CellVmax.ConditionCheckRead
            SSCP_95: operation=DataServices_DidB03E_Data_Mod8Temp2.ReadData
            SSCP_96: operation=DataServices_DidB03E_Data_Mod8Temp2.ConditionCheckRead
            SSCP_97: operation=DataServices_DidB03F_Data_Mod8Temp1.ReadData
            SSCP_98: operation=DataServices_DidB03F_Data_Mod8Temp1.ConditionCheckRead
            SSCP_99: operation=DataServices_DidB040_Data_Mod8PCBTemp.ReadData
            SSCP_100: operation=DataServices_DidB040_Data_Mod8PCBTemp.ConditionCheckRead
            SSCP_101: operation=DataServices_DidB041_Data_BMSBusV.ReadData
            SSCP_102: operation=DataServices_DidB041_Data_BMSBusV.ConditionCheckRead
            SSCP_103: operation=DataServices_DidB042_Data_BMSBatV.ReadData
            SSCP_104: operation=DataServices_DidB042_Data_BMSBatV.ConditionCheckRead
            SSCP_105: operation=DataServices_DidB043_Data_BMSCur1.ReadData
            SSCP_106: operation=DataServices_DidB043_Data_BMSCur1.ConditionCheckRead
            SSCP_107: operation=DataServices_DidB044_Data_BMSCur2.ReadData
            SSCP_108: operation=DataServices_DidB044_Data_BMSCur2.ConditionCheckRead
            SSCP_109: operation=DataServices_DidB045_Data_BMSIso.ReadData
            SSCP_110: operation=DataServices_DidB045_Data_BMSIso.ConditionCheckRead
            SSCP_111: operation=DataServices_DidB046_Data_BMSPackSOC.ReadData
            SSCP_112: operation=DataServices_DidB046_Data_BMSPackSOC.ConditionCheckRead
            SSCP_113: operation=DataServices_DidB046_Data_BMSPackSOC.WriteData
            SSCP_114: operation=DataServices_DidB047_Data_BMSFltLvl.ReadData
            SSCP_115: operation=DataServices_DidB047_Data_BMSFltLvl.ConditionCheckRead
            SSCP_116: operation=DataServices_DidB048_Data_BMSBscSts.ReadData
            SSCP_117: operation=DataServices_DidB048_Data_BMSBscSts.ConditionCheckRead
            SSCP_118: operation=DataServices_DidB049_Data_BMSVehHVIL.ReadData
            SSCP_119: operation=DataServices_DidB049_Data_BMSVehHVIL.ConditionCheckRead
            SSCP_120: operation=DataServices_DidB04A_Data_BMSChgHVIL.ReadData
            SSCP_121: operation=DataServices_DidB04A_Data_BMSChgHVIL.ConditionCheckRead
            SSCP_122: operation=DataServices_DidB04B_Data_BMSVehWake.ReadData
            SSCP_123: operation=DataServices_DidB04B_Data_BMSVehWake.ConditionCheckRead
            SSCP_124: operation=DataServices_DidB04C_Data_BMSBMSOnbdWake.ReadData
            SSCP_125: operation=DataServices_DidB04C_Data_BMSBMSOnbdWake.ConditionCheckRead
            SSCP_126: operation=DataServices_DidB04D_Data_BMSOffbdWake.ReadData
            SSCP_127: operation=DataServices_DidB04D_Data_BMSOffbdWake.ConditionCheckRead
            SSCP_128: operation=DataServices_DidB04E_Data_BMSLvBat.ReadData
            SSCP_129: operation=DataServices_DidB04E_Data_BMSLvBat.ConditionCheckRead
            SSCP_130: operation=DataServices_DidB04F_Data_BMSModuleEn.ReadData
            SSCP_131: operation=DataServices_DidB04F_Data_BMSModuleEn.ConditionCheckRead
            SSCP_132: operation=DataServices_DidB050_Data_OffbdChgPlugOn.ReadData
            SSCP_133: operation=DataServices_DidB050_Data_OffbdChgPlugOn.ConditionCheckRead
            SSCP_134: operation=DataServices_DidB051_Data_OnbdChgPlugOn.ReadData
            SSCP_135: operation=DataServices_DidB051_Data_OnbdChgPlugOn.ConditionCheckRead
            SSCP_136: operation=DataServices_DidB052_Data_CrashSts.ReadData
            SSCP_137: operation=DataServices_DidB052_Data_CrashSts.ConditionCheckRead
            SSCP_138: operation=DataServices_DidB053_Data_BMSBalSts.ReadData
            SSCP_139: operation=DataServices_DidB053_Data_BMSBalSts.ConditionCheckRead
            SSCP_140: operation=DataServices_DidB054_Data_BMSBalCnt.ReadData
            SSCP_141: operation=DataServices_DidB054_Data_BMSBalCnt.ConditionCheckRead
            SSCP_142: operation=DataServices_DidB055_Data_BMSEnergyAvail.ReadData
            SSCP_143: operation=DataServices_DidB055_Data_BMSEnergyAvail.ConditionCheckRead
            SSCP_144: operation=DataServices_DidB056_Data_BMSCellTmax.ReadData
            SSCP_145: operation=DataServices_DidB056_Data_BMSCellTmax.ConditionCheckRead
            SSCP_146: operation=DataServices_DidB057_Data_BMSCellTmin.ReadData
            SSCP_147: operation=DataServices_DidB057_Data_BMSCellTmin.ConditionCheckRead
            SSCP_148: operation=DataServices_DidB058_Data_BMSCellVmax.ReadData
            SSCP_149: operation=DataServices_DidB058_Data_BMSCellVmax.ConditionCheckRead
            SSCP_150: operation=DataServices_DidB059_Data_BMSCellVmin.ReadData
            SSCP_151: operation=DataServices_DidB059_Data_BMSCellVmin.ConditionCheckRead
            SSCP_152: operation=DataServices_DidB05C_Data_BMSCoolantTemp.ReadData
            SSCP_153: operation=DataServices_DidB05C_Data_BMSCoolantTemp.ConditionCheckRead
            SSCP_154: operation=DataServices_DidB05F_Data_BMSShuntTemp.ReadData
            SSCP_155: operation=DataServices_DidB05F_Data_BMSShuntTemp.ConditionCheckRead
            SSCP_156: operation=DataServices_DidB061_Data_BMSPackSoh.ReadData
            SSCP_157: operation=DataServices_DidB061_Data_BMSPackSoh.ConditionCheckRead
            SSCP_158: operation=DataServices_DidB062_Data_BMSPackCapFade.ReadData
            SSCP_159: operation=DataServices_DidB062_Data_BMSPackCapFade.ConditionCheckRead
            SSCP_160: operation=DataServices_DidB063_Data_BMSPackResiGrw.ReadData
            SSCP_161: operation=DataServices_DidB063_Data_BMSPackResiGrw.ConditionCheckRead
            SSCP_162: operation=DataServices_DidB064_Data_BMSCldAccumTime.ReadData
            SSCP_163: operation=DataServices_DidB064_Data_BMSCldAccumTime.ConditionCheckRead
            SSCP_164: operation=DataServices_DidB064_Data_BMSCldAccumTime.WriteData
            SSCP_165: operation=DataServices_DidB065_Data_BMSCldCapFade.ReadData
            SSCP_166: operation=DataServices_DidB065_Data_BMSCldCapFade.ConditionCheckRead
            SSCP_167: operation=DataServices_DidB065_Data_BMSCldCapFade.WriteData
            SSCP_168: operation=DataServices_DidB066_Data_BMSCldResiGrw.ReadData
            SSCP_169: operation=DataServices_DidB066_Data_BMSCldResiGrw.ConditionCheckRead
            SSCP_170: operation=DataServices_DidB066_Data_BMSCldResiGrw.WriteData
            SSCP_171: operation=DataServices_DidB067_Data_BMSCycAccumTime.ReadData
            SSCP_172: operation=DataServices_DidB067_Data_BMSCycAccumTime.ConditionCheckRead
            SSCP_173: operation=DataServices_DidB067_Data_BMSCycAccumTime.WriteData
            SSCP_174: operation=DataServices_DidB068_Data_BMSCycAccumEngy.ReadData
            SSCP_175: operation=DataServices_DidB068_Data_BMSCycAccumEngy.ConditionCheckRead
            SSCP_176: operation=DataServices_DidB068_Data_BMSCycAccumEngy.WriteData
            SSCP_177: operation=DataServices_DidB069_Data_BMSCycCapFade.ReadData
            SSCP_178: operation=DataServices_DidB069_Data_BMSCycCapFade.ConditionCheckRead
            SSCP_179: operation=DataServices_DidB069_Data_BMSCycCapFade.WriteData
            SSCP_180: operation=DataServices_DidB06A_Data_BMSCycResiGrw.ReadData
            SSCP_181: operation=DataServices_DidB06A_Data_BMSCycResiGrw.ConditionCheckRead
            SSCP_182: operation=DataServices_DidB06A_Data_BMSCycResiGrw.WriteData
            SSCP_183: operation=DataServices_DidB06D_Data_HvmRtcTime.ReadData
            SSCP_184: operation=DataServices_DidB06D_Data_HvmRtcTime.ConditionCheckRead
            SSCP_185: operation=DataServices_DidB06D_Data_HvmRtcTime.WriteData
            SSCP_186: operation=DataServices_DidB072_Data_BMSAccumAhLower.ReadData
            SSCP_187: operation=DataServices_DidB072_Data_BMSAccumAhLower.ConditionCheckRead
            SSCP_188: operation=DataServices_DidB072_Data_BMSAccumAhLower.WriteData
            SSCP_189: operation=DataServices_DidB073_Data_BMSAccumAhUpper.ReadData
            SSCP_190: operation=DataServices_DidB073_Data_BMSAccumAhUpper.ConditionCheckRead
            SSCP_191: operation=DataServices_DidB073_Data_BMSAccumAhUpper.WriteData
            SSCP_192: operation=DataServices_DidB074_Data_BMSCellTemDiffTime.ReadData
            SSCP_193: operation=DataServices_DidB074_Data_BMSCellTemDiffTime.ConditionCheckRead
            SSCP_194: operation=DataServices_DidB074_Data_BMSCellTemDiffTime.WriteData
            SSCP_195: operation=DataServices_DidB075_Data_UnlockLogi.ReadData
            SSCP_196: operation=DataServices_DidB075_Data_UnlockLogi.ConditionCheckRead
            SSCP_197: operation=DataServices_DidB075_Data_UnlockLogi.WriteData
            SSCP_198: operation=DataServices_DidB076_Data_BMSOffChgAccumTime.ReadData
            SSCP_199: operation=DataServices_DidB076_Data_BMSOffChgAccumTime.ConditionCheckRead
            SSCP_200: operation=DataServices_DidB076_Data_BMSOffChgAccumTime.WriteData
            SSCP_201: operation=DataServices_DidB080_Data_BMSBalanceTime.ReadData
            SSCP_202: operation=DataServices_DidB080_Data_BMSBalanceTime.ConditionCheckRead
            SSCP_203: operation=DataServices_DidB080_Data_BMSBalanceTime.WriteData
            SSCP_204: operation=DataServices_DidB081_Data_CMUMissingCnt.ReadData
            SSCP_205: operation=DataServices_DidB081_Data_CMUMissingCnt.ConditionCheckRead
            SSCP_206: operation=DataServices_DidB081_Data_CMUMissingCnt.WriteData
            SSCP_207: operation=DataServices_DidB082_Data_CMUMissingTime.ReadData
            SSCP_208: operation=DataServices_DidB082_Data_CMUMissingTime.ConditionCheckRead
            SSCP_209: operation=DataServices_DidB082_Data_CMUMissingTime.WriteData
            SSCP_210: operation=DataServices_DidB083_Data_ExtPackLeakageFltCnt.ReadData
            SSCP_211: operation=DataServices_DidB083_Data_ExtPackLeakageFltCnt.ConditionCheckRead
            SSCP_212: operation=DataServices_DidB083_Data_ExtPackLeakageFltCnt.WriteData
            SSCP_213: operation=DataServices_DidB084_Data_IntPackLeakageFltCnt.ReadData
            SSCP_214: operation=DataServices_DidB084_Data_IntPackLeakageFltCnt.ConditionCheckRead
            SSCP_215: operation=DataServices_DidB084_Data_IntPackLeakageFltCnt.WriteData
            SSCP_216: operation=DataServices_DidB085_Data_CellOverVoltageCnt.ReadData
            SSCP_217: operation=DataServices_DidB085_Data_CellOverVoltageCnt.ConditionCheckRead
            SSCP_218: operation=DataServices_DidB085_Data_CellOverVoltageCnt.WriteData
            SSCP_219: operation=DataServices_DidB086_Data_PrechrgResEnrgExCnt.ReadData
            SSCP_220: operation=DataServices_DidB086_Data_PrechrgResEnrgExCnt.ConditionCheckRead
            SSCP_221: operation=DataServices_DidB086_Data_PrechrgResEnrgExCnt.WriteData
            SSCP_222: operation=DataServices_DidB087_Data_PrechrgTimeOutExCnt.ReadData
            SSCP_223: operation=DataServices_DidB087_Data_PrechrgTimeOutExCnt.ConditionCheckRead
            SSCP_224: operation=DataServices_DidB087_Data_PrechrgTimeOutExCnt.WriteData
            SSCP_225: operation=DataServices_DidB088_Data_RlyOpenWithCrntCnt.ReadData
            SSCP_226: operation=DataServices_DidB088_Data_RlyOpenWithCrntCnt.ConditionCheckRead
            SSCP_227: operation=DataServices_DidB088_Data_RlyOpenWithCrntCnt.WriteData
            SSCP_228: operation=DataServices_DidB089_Data_RlyOpenWithCrntLvl1Cnt.ReadData
            SSCP_229: operation=DataServices_DidB089_Data_RlyOpenWithCrntLvl1Cnt.ConditionCheckRead
            SSCP_230: operation=DataServices_DidB089_Data_RlyOpenWithCrntLvl1Cnt.WriteData
            SSCP_231: operation=DataServices_DidB08A_Data_RlyOpenWithCrntLvl2Cnt.ReadData
            SSCP_232: operation=DataServices_DidB08A_Data_RlyOpenWithCrntLvl2Cnt.ConditionCheckRead
            SSCP_233: operation=DataServices_DidB08A_Data_RlyOpenWithCrntLvl2Cnt.WriteData
            SSCP_234: operation=DataServices_DidB08B_Data_RlyOpenWithCrntLvl3Cnt.ReadData
            SSCP_235: operation=DataServices_DidB08B_Data_RlyOpenWithCrntLvl3Cnt.ConditionCheckRead
            SSCP_236: operation=DataServices_DidB08B_Data_RlyOpenWithCrntLvl3Cnt.WriteData
            SSCP_237: operation=DataServices_DidB08C_Data_PackSOCLowTime.ReadData
            SSCP_238: operation=DataServices_DidB08C_Data_PackSOCLowTime.ConditionCheckRead
            SSCP_239: operation=DataServices_DidB08C_Data_PackSOCLowTime.WriteData
            SSCP_240: operation=DataServices_DidB08D_Data_CellUnderVoltageCnt.ReadData
            SSCP_241: operation=DataServices_DidB08D_Data_CellUnderVoltageCnt.ConditionCheckRead
            SSCP_242: operation=DataServices_DidB08D_Data_CellUnderVoltageCnt.WriteData
            SSCP_243: operation=DataServices_DidB08E_Data_TempLvl1Cnt.ReadData
            SSCP_244: operation=DataServices_DidB08E_Data_TempLvl1Cnt.ConditionCheckRead
            SSCP_245: operation=DataServices_DidB08E_Data_TempLvl1Cnt.WriteData
            SSCP_246: operation=DataServices_DidB08F_Data_TempLvl2Cnt.ReadData
            SSCP_247: operation=DataServices_DidB08F_Data_TempLvl2Cnt.ConditionCheckRead
            SSCP_248: operation=DataServices_DidB08F_Data_TempLvl2Cnt.WriteData
            SSCP_249: operation=DataServices_DidB090_Data_TempLvl3Cnt.ReadData
            SSCP_250: operation=DataServices_DidB090_Data_TempLvl3Cnt.ConditionCheckRead
            SSCP_251: operation=DataServices_DidB090_Data_TempLvl3Cnt.WriteData
            SSCP_252: operation=DataServices_DidB091_Data_TempLvl4Cnt.ReadData
            SSCP_253: operation=DataServices_DidB091_Data_TempLvl4Cnt.ConditionCheckRead
            SSCP_254: operation=DataServices_DidB091_Data_TempLvl4Cnt.WriteData
            SSCP_255: operation=DataServices_DidB092_Data_TempLvl5Cnt.ReadData
            SSCP_256: operation=DataServices_DidB092_Data_TempLvl5Cnt.ConditionCheckRead
            SSCP_257: operation=DataServices_DidB092_Data_TempLvl5Cnt.WriteData
            SSCP_258: operation=DataServices_DidB093_Data_TempLvl6Cnt.ReadData
            SSCP_259: operation=DataServices_DidB093_Data_TempLvl6Cnt.ConditionCheckRead
            SSCP_260: operation=DataServices_DidB093_Data_TempLvl6Cnt.WriteData
            SSCP_261: operation=DataServices_DidB094_Data_TempLvl7Cnt.ReadData
            SSCP_262: operation=DataServices_DidB094_Data_TempLvl7Cnt.ConditionCheckRead
            SSCP_263: operation=DataServices_DidB094_Data_TempLvl7Cnt.WriteData
            SSCP_264: operation=DataServices_DidB095_Data_BMSOnChgEngy.ReadData
            SSCP_265: operation=DataServices_DidB095_Data_BMSOnChgEngy.ConditionCheckRead
            SSCP_266: operation=DataServices_DidB095_Data_BMSOnChgEngy.WriteData
            SSCP_267: operation=DataServices_DidB096_Data_BMSReservedData1.ReadData
            SSCP_268: operation=DataServices_DidB096_Data_BMSReservedData1.ConditionCheckRead
            SSCP_269: operation=DataServices_DidB097_Data_BMSReservedData2.ReadData
            SSCP_270: operation=DataServices_DidB097_Data_BMSReservedData2.ConditionCheckRead
            SSCP_271: operation=DataServices_DidB098_Data_BMSReservedData3.ReadData
            SSCP_272: operation=DataServices_DidB098_Data_BMSReservedData3.ConditionCheckRead
            SSCP_273: operation=DataServices_DidB099_Data_BMSReservedData4.ReadData
            SSCP_274: operation=DataServices_DidB099_Data_BMSReservedData4.ConditionCheckRead
            SSCP_275: operation=DataServices_DidB09A_Data_BMSReservedData5.ReadData
            SSCP_276: operation=DataServices_DidB09A_Data_BMSReservedData5.ConditionCheckRead
            SSCP_277: operation=DataServices_DidB09B_Data_BMSReservedData6.ReadData
            SSCP_278: operation=DataServices_DidB09B_Data_BMSReservedData6.ConditionCheckRead
            SSCP_279: operation=DataServices_DidB09C_Data_BMSReservedData7.ReadData
            SSCP_280: operation=DataServices_DidB09C_Data_BMSReservedData7.ConditionCheckRead
            SSCP_281: operation=DataServices_DidB09D_Data_BMSReservedData8.ReadData
            SSCP_282: operation=DataServices_DidB09D_Data_BMSReservedData8.ConditionCheckRead
            SSCP_283: operation=DataServices_DidB09E_Data_BMSReservedData9.ReadData
            SSCP_284: operation=DataServices_DidB09E_Data_BMSReservedData9.ConditionCheckRead
            SSCP_285: operation=DataServices_DidB09F_Data_BMSReservedData10.ReadData
            SSCP_286: operation=DataServices_DidB09F_Data_BMSReservedData10.ConditionCheckRead
            SSCP_287: operation=DataServices_DidB0A0_Data_BMSOnChgAccumTime.ReadData
            SSCP_288: operation=DataServices_DidB0A0_Data_BMSOnChgAccumTime.ConditionCheckRead
            SSCP_289: operation=DataServices_DidB0A0_Data_BMSOnChgAccumTime.WriteData
            SSCP_290: operation=DataServices_DidB0A1_Data_BMSOnChgCnt.ReadData
            SSCP_291: operation=DataServices_DidB0A1_Data_BMSOnChgCnt.ConditionCheckRead
            SSCP_292: operation=DataServices_DidB0A1_Data_BMSOnChgCnt.WriteData
            SSCP_293: operation=DataServices_DidB0A2_Data_BMSSupConfigParam.WriteData
            SSCP_294: operation=DataServices_DidB0BD_Data_VehicleSpeed.ReadData
            SSCP_295: operation=DataServices_DidB0BD_Data_VehicleSpeed.ConditionCheckRead
            SSCP_296: operation=DataServices_DidD001_Data_PowerMode.ReadData
            SSCP_297: operation=DataServices_DidD001_Data_PowerMode.ConditionCheckRead
            SSCP_298: operation=DataServices_DidE000_Data_CoolingPump.ReadData
            SSCP_299: operation=DataServices_DidE000_Data_CoolingPump.ConditionCheckRead
            SSCP_300: operation=DataServices_DidE000_Data_CoolingPump.ReturnControlToECU
            SSCP_301: operation=DataServices_DidE000_Data_CoolingPump.ResetToDefault
            SSCP_302: operation=DataServices_DidE000_Data_CoolingPump.FreezeCurrentState
            SSCP_303: operation=DataServices_DidE000_Data_CoolingPump.ShortTermAdjustment
            SSCP_304: operation=DataServices_DidE001_Data_ChgIndDriver.ReadData
            SSCP_305: operation=DataServices_DidE001_Data_ChgIndDriver.ConditionCheckRead
            SSCP_306: operation=DataServices_DidE001_Data_ChgIndDriver.ReturnControlToECU
            SSCP_307: operation=DataServices_DidE001_Data_ChgIndDriver.ResetToDefault
            SSCP_308: operation=DataServices_DidE001_Data_ChgIndDriver.FreezeCurrentState
            SSCP_309: operation=DataServices_DidE001_Data_ChgIndDriver.ShortTermAdjustment
            SSCP_310: operation=DataServices_DidE002_Data_ConnIndDriver.ReadData
            SSCP_311: operation=DataServices_DidE002_Data_ConnIndDriver.ConditionCheckRead
            SSCP_312: operation=DataServices_DidE002_Data_ConnIndDriver.ReturnControlToECU
            SSCP_313: operation=DataServices_DidE002_Data_ConnIndDriver.ResetToDefault
            SSCP_314: operation=DataServices_DidE002_Data_ConnIndDriver.FreezeCurrentState
            SSCP_315: operation=DataServices_DidE002_Data_ConnIndDriver.ShortTermAdjustment
            SSCP_316: operation=DataServices_DidE003_Data_LeakDetectEn.ReadData
            SSCP_317: operation=DataServices_DidE003_Data_LeakDetectEn.ConditionCheckRead
            SSCP_318: operation=DataServices_DidE003_Data_LeakDetectEn.ReturnControlToECU
            SSCP_319: operation=DataServices_DidE003_Data_LeakDetectEn.ResetToDefault
            SSCP_320: operation=DataServices_DidE003_Data_LeakDetectEn.FreezeCurrentState
            SSCP_321: operation=DataServices_DidE003_Data_LeakDetectEn.ShortTermAdjustment
            SSCP_322: operation=DataServices_DidE004_Data_BthIndDriver.ReadData
            SSCP_323: operation=DataServices_DidE004_Data_BthIndDriver.ConditionCheckRead
            SSCP_324: operation=DataServices_DidE004_Data_BthIndDriver.ReturnControlToECU
            SSCP_325: operation=DataServices_DidE004_Data_BthIndDriver.ResetToDefault
            SSCP_326: operation=DataServices_DidE004_Data_BthIndDriver.FreezeCurrentState
            SSCP_327: operation=DataServices_DidE004_Data_BthIndDriver.ShortTermAdjustment
            SSCP_328: operation=DataServices_DidE101_Data_Odometer.ReadData
            SSCP_329: operation=DataServices_DidE101_Data_Odometer.ConditionCheckRead
            SSCP_330: operation=DataServices_DidF100_Data_SVIF.ReadData
            SSCP_331: operation=DataServices_DidF100_Data_SVIF.ConditionCheckRead
            SSCP_332: operation=DataServices_DidF110_Data_PIFptr.ReadData
            SSCP_333: operation=DataServices_DidF110_Data_PIFptr.ConditionCheckRead
            SSCP_334: operation=DataServices_DidF111_Data_PIF1.ReadData
            SSCP_335: operation=DataServices_DidF111_Data_PIF1.ConditionCheckRead
            SSCP_336: operation=DataServices_DidF112_Data_PIF2.ReadData
            SSCP_337: operation=DataServices_DidF112_Data_PIF2.ConditionCheckRead
            SSCP_338: operation=DataServices_DidF113_Data_PIF3.ReadData
            SSCP_339: operation=DataServices_DidF113_Data_PIF3.ConditionCheckRead
            SSCP_340: operation=DataServices_DidF114_Data_PIF4.ReadData
            SSCP_341: operation=DataServices_DidF114_Data_PIF4.ConditionCheckRead
            SSCP_342: operation=DataServices_DidF115_Data_PIF5.ReadData
            SSCP_343: operation=DataServices_DidF115_Data_PIF5.ConditionCheckRead
            SSCP_344: operation=DataServices_DidF116_Data_PIF6.ReadData
            SSCP_345: operation=DataServices_DidF116_Data_PIF6.ConditionCheckRead
            SSCP_346: operation=DataServices_DidF117_Data_PIF7.ReadData
            SSCP_347: operation=DataServices_DidF117_Data_PIF7.ConditionCheckRead
            SSCP_348: operation=DataServices_DidF118_Data_PIF8.ReadData
            SSCP_349: operation=DataServices_DidF118_Data_PIF8.ConditionCheckRead
            SSCP_350: operation=DataServices_DidF119_Data_PIF9.ReadData
            SSCP_351: operation=DataServices_DidF119_Data_PIF9.ConditionCheckRead
            SSCP_352: operation=DataServices_DidF11A_Data_PIFA.ReadData
            SSCP_353: operation=DataServices_DidF11A_Data_PIFA.ConditionCheckRead
            SSCP_354: operation=DataServices_DidF11B_Data_PIFB.ReadData
            SSCP_355: operation=DataServices_DidF11B_Data_PIFB.ConditionCheckRead
            SSCP_356: operation=DataServices_DidF11C_Data_PIFC.ReadData
            SSCP_357: operation=DataServices_DidF11C_Data_PIFC.ConditionCheckRead
            SSCP_358: operation=DataServices_DidF11D_Data_PIFD.ReadData
            SSCP_359: operation=DataServices_DidF11D_Data_PIFD.ConditionCheckRead
            SSCP_360: operation=DataServices_DidF11E_Data_PIFE.ReadData
            SSCP_361: operation=DataServices_DidF11E_Data_PIFE.ConditionCheckRead
            SSCP_362: operation=DataServices_DidF11F_Data_PIFF.ReadData
            SSCP_363: operation=DataServices_DidF11F_Data_PIFF.ConditionCheckRead
            SSCP_364: operation=DataServices_DidF120_Data_NIFfactory.ReadData
            SSCP_365: operation=DataServices_DidF120_Data_NIFfactory.ConditionCheckRead
            SSCP_366: operation=DataServices_DidF121_Data_NIFcur.ReadData
            SSCP_367: operation=DataServices_DidF121_Data_NIFcur.ConditionCheckRead
            SSCP_368: operation=DataServices_DidF183_Data_BootloaderSRN.ReadData
            SSCP_369: operation=DataServices_DidF183_Data_BootloaderSRN.ConditionCheckRead
            SSCP_370: operation=DataServices_DidF187_Data_ECUPN.ReadData
            SSCP_371: operation=DataServices_DidF187_Data_ECUPN.ConditionCheckRead
            SSCP_372: operation=DataServices_DidF18A_Data_SupID.ReadData
            SSCP_373: operation=DataServices_DidF18A_Data_SupID.ConditionCheckRead
            SSCP_374: operation=DataServices_DidF18B_Data_ECUDate.ReadData
            SSCP_375: operation=DataServices_DidF18B_Data_ECUDate.ConditionCheckRead
            SSCP_376: operation=DataServices_DidF18B_Data_ECUDate.WriteData
            SSCP_377: operation=DataServices_DidF18C_Data_ECUSN.ReadData
            SSCP_378: operation=DataServices_DidF18C_Data_ECUSN.ConditionCheckRead
            SSCP_379: operation=DataServices_DidF18C_Data_ECUSN.WriteData
            SSCP_380: operation=DataServices_DidF190_Data_VIN.ReadData
            SSCP_381: operation=DataServices_DidF190_Data_VIN.ConditionCheckRead
            SSCP_382: operation=DataServices_DidF190_Data_VIN.WriteData
            SSCP_383: operation=DataServices_DidF191_Data_ECUHWNo.ReadData
            SSCP_384: operation=DataServices_DidF191_Data_ECUHWNo.ConditionCheckRead
            SSCP_385: operation=DataServices_DidF192_Data_SupHWRN.ReadData
            SSCP_386: operation=DataServices_DidF192_Data_SupHWRN.ConditionCheckRead
            SSCP_387: operation=DataServices_DidF194_Data_SupSWRN.ReadData
            SSCP_388: operation=DataServices_DidF194_Data_SupSWRN.ConditionCheckRead
            SSCP_389: operation=DataServices_DidF198_Data_ConfigTF.ReadData
            SSCP_390: operation=DataServices_DidF198_Data_ConfigTF.ConditionCheckRead
            SSCP_391: operation=DataServices_DidF198_Data_ConfigTF.WriteData
            SSCP_392: operation=DataServices_DidF1A0_Data_AppSWNo.ReadData
            SSCP_393: operation=DataServices_DidF1A0_Data_AppSWNo.ConditionCheckRead
            SSCP_394: operation=DataServices_DidF1A1_Data_CalSWNo.ReadData
            SSCP_395: operation=DataServices_DidF1A1_Data_CalSWNo.ConditionCheckRead
            SSCP_396: operation=DataServices_DidF1A2_Data_NCFRN.ReadData
            SSCP_397: operation=DataServices_DidF1A2_Data_NCFRN.ConditionCheckRead
            SSCP_398: operation=DataServices_DidF1A5_Data_ECUIndex.ReadData
            SSCP_399: operation=DataServices_DidF1A5_Data_ECUIndex.ConditionCheckRead
            SSCP_400: operation=DataServices_DidF1A8_Data_VehFeature.ReadData
            SSCP_401: operation=DataServices_DidF1A8_Data_VehFeature.ConditionCheckRead
            SSCP_402: operation=DataServices_DidF1A8_Data_VehFeature.WriteData
            SSCP_403: operation=DataServices_DidF1A9_Data_ECUConfigFN.ReadData
            SSCP_404: operation=DataServices_DidF1A9_Data_ECUConfigFN.ConditionCheckRead
            SSCP_405: operation=DataServices_DidF1A9_Data_ECUConfigFN.WriteData
            SSCP_406: operation=DataServices_DidF1AA_Data_EUCProgPrcsFN.ReadData
            SSCP_407: operation=DataServices_DidF1AA_Data_EUCProgPrcsFN.ConditionCheckRead
            SSCP_408: operation=CallbackDCMRequestServices_CBReqServInd_1.StartProtocol
            SSCP_409: operation=CallbackDCMRequestServices_CBReqServInd_1.StopProtocol
            SSCP_410: operation=ServiceRequestManufacturerNotification_DcmDslServiceRequestManufacturerNotification.Indication
            SSCP_411: operation=ServiceRequestManufacturerNotification_DcmDslServiceRequestManufacturerNotification.Confirmation
